VERSION "HNNBNNNYNNNNNNNNNNNNNNNNNNNNNNNNNNNNNNNNNN/4/%%%/4/'%**4NNN///"

NS_ :

BS_ :

BU_:  Airbag BAP_Tester ICAS1_Gateway ICAS1_KommunikationsServer LE1 LE2 Motor_BEV Schaltbetaetigung

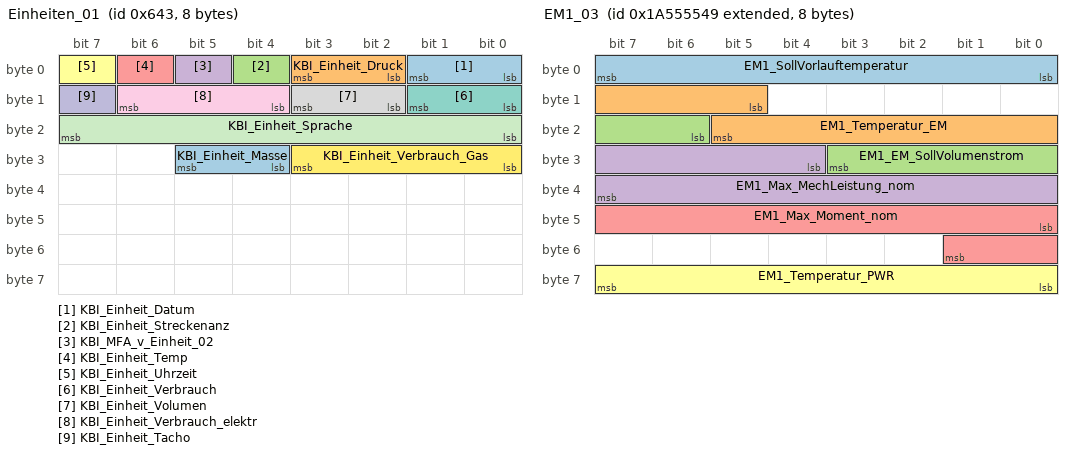
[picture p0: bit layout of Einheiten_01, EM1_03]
BO_ 1603 Einheiten_01: 8 ICAS1_KommunikationsServer
 SG_ KBI_Einheit_Datum  : 0|2@1+ (1.000000,0.000000) [0.000000|3.000000] "" Vector__XXX
 SG_ KBI_Einheit_Druck  : 2|2@1+ (1.000000,0.000000) [0.000000|3.000000] "" Vector__XXX
 SG_ KBI_Einheit_Streckenanz  : 4|1@1+ (1.000000,0.000000) [0.000000|1.000000] "" Vector__XXX
 SG_ KBI_MFA_v_Einheit_02  : 5|1@1+ (1.000000,0.000000) [0.000000|1.000000] "" Motor_BEV
 SG_ KBI_Einheit_Temp  : 6|1@1+ (1.000000,0.000000) [0.000000|1.000000] "" Vector__XXX
 SG_ KBI_Einheit_Uhrzeit  : 7|1@1+ (1.000000,0.000000) [0.000000|1.000000] "" Vector__XXX
 SG_ KBI_Einheit_Verbrauch  : 8|2@1+ (1.000000,0.000000) [0.000000|3.000000] "" Vector__XXX
 SG_ KBI_Einheit_Volumen  : 10|2@1+ (1.000000,0.000000) [0.000000|3.000000] "" Vector__XXX
 SG_ KBI_Einheit_Verbrauch_elektr  : 12|3@1+ (1.000000,0.000000) [0.000000|7.000000] "" Vector__XXX
 SG_ KBI_Einheit_Tacho  : 15|1@1+ (1.000000,0.000000) [0.000000|1.000000] "" Motor_BEV
 SG_ KBI_Einheit_Sprache  : 16|8@1+ (1.000000,0.000000) [0.000000|255.000000] "" Vector__XXX
 SG_ KBI_Einheit_Verbrauch_Gas  : 24|4@1+ (1.000000,0.000000) [0.000000|15.000000] "" Vector__XXX
 SG_ KBI_Einheit_Masse  : 28|2@1+ (1.000000,0.000000) [0.000000|3.000000] "" Vector__XXX

BO_ 192 EM1_01: 32 LE1
 SG_ EM1_01_CRC  : 0|8@1+ (1.000000,0.000000) [0.000000|255.000000] "" ICAS1_Gateway Motor_BEV
 SG_ EM1_01_BZ  : 8|4@1+ (1.000000,0.000000) [0.000000|15.000000] "" ICAS1_Gateway Motor_BEV
 SG_ EM1_Istmodus  : 12|4@1+ (1.000000,0.000000) [0.000000|15.000000] "" ICAS1_Gateway Motor_BEV
 SG_ EM1_IstMoment  : 16|12@1+ (0.500000,-1023.000000) [-1023.000000|1023.500000] "Unit_NewtoMeter" ICAS1_Gateway Motor_BEV
 SG_ EM1_Moment_AR_Eingriff  : 28|12@1+ (0.500000,-1023.000000) [-1023.000000|1023.500000] "Unit_NewtoMeter" ICAS1_Gateway Motor_BEV
 SG_ EM1_IstDrehzahl  : 40|15@1+ (1.000000,-10000.000000) [-10000.000000|22765.000000] "Unit_MinutInver" ICAS1_Gateway Motor_BEV
 SG_ EM1_AR_aktiv  : 55|1@1+ (1.000000,0.000000) [0.000000|1.000000] "" ICAS1_Gateway Motor_BEV
 SG_ EM1_IstSpannung  : 56|12@1+ (0.250000,0.000000) [0.000000|1023.250000] "Unit_Volt" ICAS1_Gateway Motor_BEV
 SG_ EM1_Strom_HV  : 68|12@1+ (0.500000,-1023.000000) [-1023.000000|1023.500000] "Unit_Amper" ICAS1_Gateway Motor_BEV
 SG_ EM1_Max_Moment  : 80|11@1+ (1.000000,-1023.000000) [-1023.000000|1022.000000] "Unit_NewtoMeter" ICAS1_Gateway Motor_BEV
 SG_ EM1_ErwGrenzen_aktiv  : 91|1@1+ (1.000000,0.000000) [0.000000|1.000000] "" ICAS1_Gateway Motor_BEV
 SG_ EM1_Min_Moment  : 92|11@1+ (1.000000,-1023.000000) [-1023.000000|1022.000000] "Unit_NewtoMeter" ICAS1_Gateway Motor_BEV
 SG_ EM1_Fehler_ElAntriebAbschaltung  : 103|1@1+ (1.000000,0.000000) [0.000000|1.000000] "" ICAS1_Gateway Motor_BEV
 SG_ EM1_Max_Moment_Lim  : 104|11@1+ (1.000000,-1023.000000) [-1023.000000|1022.000000] "Unit_NewtoMeter" ICAS1_Gateway Motor_BEV
 SG_ EM1_Fehler_Notabschaltung  : 115|1@1+ (1.000000,0.000000) [0.000000|1.000000] "" ICAS1_Gateway Motor_BEV
 SG_ EM1_Min_Moment_Lim  : 116|11@1+ (1.000000,-1023.000000) [-1023.000000|1022.000000] "Unit_NewtoMeter" ICAS1_Gateway Motor_BEV
 SG_ EM1_Status_DrzEingriff  : 127|2@1+ (1.000000,0.000000) [0.000000|3.000000] "" ICAS1_Gateway Motor_BEV
 SG_ EM1_Mom_DrzEingriff  : 129|11@1+ (1.000000,-1023.000000) [-1023.000000|1022.000000] "Unit_NewtoMeter" ICAS1_Gateway Motor_BEV

BO_ 2463978673 EM1_02: 32 LE1
 SG_ EM1_Status_Spgfreiheit  : 12|2@1+ (1.000000,0.000000) [0.000000|3.000000] "" Motor_BEV
 SG_ EM1_Status_EoHVL  : 14|2@1+ (1.000000,0.000000) [0.000000|3.000000] "" Motor_BEV
 SG_ EM1_Max_LeistungMech_Sockel  : 16|13@1+ (200.000000,-819000.000000) [-819000.000000|818800.000000] "Unit_Watt" Vector__XXX
 SG_ EM1_Max_Moment_Sockel  : 29|11@1+ (1.000000,-1023.000000) [-1023.000000|1022.000000] "Unit_NewtoMeter" Vector__XXX
 SG_ EM1_Min_LeistungMech_Sockel  : 40|13@1+ (200.000000,-819000.000000) [-819000.000000|818800.000000] "Unit_Watt" Vector__XXX
 SG_ EM1_Min_Moment_Sockel  : 53|11@1+ (1.000000,-1023.000000) [-1023.000000|1022.000000] "Unit_NewtoMeter" Vector__XXX
 SG_ EM1_PerfInd_MaxLeistung  : 64|10@1+ (0.200000,0.000000) [0.000000|200.000000] "Unit_PerCent" Motor_BEV
 SG_ EM1_PerfInd_MaxMoment  : 74|10@1+ (0.200000,0.000000) [0.000000|200.000000] "Unit_PerCent" Motor_BEV
 SG_ EM1_AnlernenElMotor_Anf  : 84|1@1+ (1.000000,0.000000) [0.000000|1.000000] "" Motor_BEV
 SG_ EM1_OBD_Lampe_Anf  : 85|1@1+ (1.000000,0.000000) [0.000000|1.000000] "" Motor_BEV
 SG_ EM1_Generator_Moment  : 86|10@1+ (1.000000,0.000000) [0.000000|1021.000000] "Unit_NewtoMeter" Motor_BEV
 SG_ EM1_PerfInd_Temperatur  : 96|8@1+ (0.800000,0.000000) [0.000000|200.000000] "Unit_PerCent" Motor_BEV
 SG_ EM1_MaxZul_Drehzahl  : 104|8@1+ (80.000000,0.000000) [0.000000|20240.000000] "Unit_RevPerMinute" Motor_BEV
 SG_ EM1_Min_Moment_Gesamt  : 112|11@1+ (1.000000,-1023.000000) [-1023.000000|1022.000000] "Unit_NewtoMeter" Motor_BEV
 SG_ EM1_Fehlerlampe_Anf  : 123|1@1+ (1.000000,0.000000) [0.000000|1.000000] "" Motor_BEV
 SG_ EM1_Max_Moment_Gesamt  : 124|11@1+ (1.000000,-1023.000000) [-1023.000000|1022.000000] "Unit_NewtoMeter" Motor_BEV
 SG_ EM1_Warnlampe_Anf  : 135|1@1+ (1.000000,0.000000) [0.000000|1.000000] "" Motor_BEV
 SG_ EM1_Rekuperation  : 136|15@1+ (10.000000,0.000000) [0.000000|327670.000000] "Unit_WattSecond" Motor_BEV
 SG_ EM1_Rekuperation_Ueberlauf  : 151|1@1+ (1.000000,0.000000) [0.000000|1.000000] "" Motor_BEV
 SG_ EM1_Verbrauch  : 152|15@1+ (10.000000,0.000000) [0.000000|327670.000000] "Unit_WattSecond" Motor_BEV
 SG_ EM1_Verbrauch_Ueberlauf  : 167|1@1+ (1.000000,0.000000) [0.000000|1.000000] "" Motor_BEV
 SG_ EM1_Fehler_AE  : 168|1@1+ (1.000000,0.000000) [0.000000|1.000000] "" Motor_BEV
 SG_ EM1_Fehler_Leistungsred  : 169|1@1+ (1.000000,0.000000) [0.000000|1.000000] "" Motor_BEV
 SG_ EM1_Fehler_ElAntriebFreilauf  : 170|1@1+ (1.000000,0.000000) [0.000000|1.000000] "" Motor_BEV
 SG_ EM1_PWR_SollVolumenstrom  : 171|6@1+ (0.500000,0.000000) [0.000000|30.500000] "Unit_LiterPerMinut" Motor_BEV

BO_ 2589283657 EM1_03: 8 LE1
 SG_ EM1_SollVorlauftemperatur  : 0|8@1+ (0.500000,-40.000000) [-40.000000|86.500000] "Unit_DegreCelsi" Motor_BEV
 SG_ EM1_Temperatur_EM  : 13|9@1+ (1.000000,-40.000000) [-40.000000|469.000000] "Unit_DegreCelsi" ICAS1_Gateway Motor_BEV
 SG_ EM1_EM_SollVolumenstrom  : 22|6@1+ (0.500000,0.000000) [0.000000|30.500000] "Unit_LiterPerMinut" Motor_BEV
 SG_ EM1_Max_MechLeistung_nom  : 28|12@1+ (200.000000,0.000000) [0.000000|818600.000000] "Unit_Watt" Motor_BEV
 SG_ EM1_Max_Moment_nom  : 40|10@1+ (1.000000,0.000000) [0.000000|1021.000000] "Unit_NewtoMeter" Motor_BEV
 SG_ EM1_Temperatur_PWR  : 56|8@1+ (1.000000,-40.000000) [-40.000000|213.000000] "Unit_DegreCelsi" ICAS1_Gateway Motor_BEV

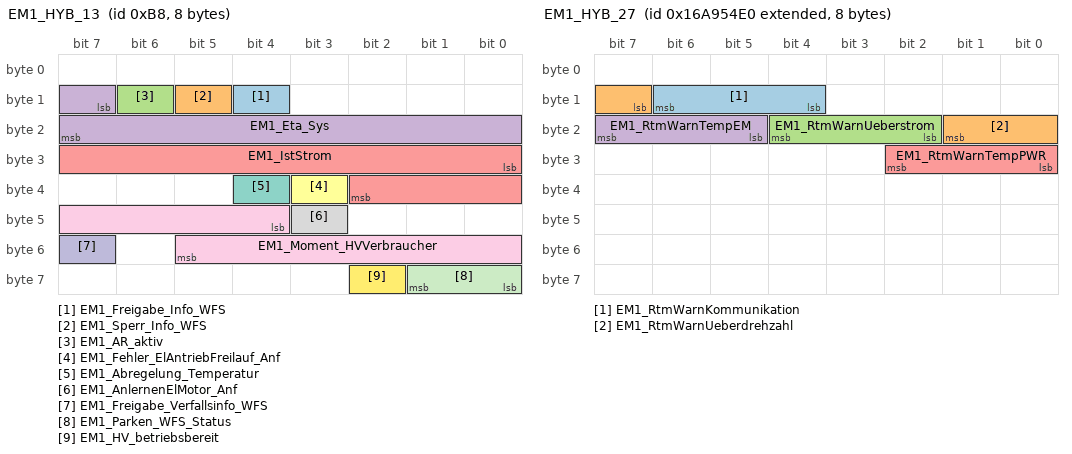
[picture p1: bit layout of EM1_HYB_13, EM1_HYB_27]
BO_ 184 EM1_HYB_13: 8 LE1
 SG_ EM1_Freigabe_Info_WFS  : 12|1@1+ (1.000000,0.000000) [0.000000|1.000000] "" ICAS1_Gateway Motor_BEV
 SG_ EM1_Sperr_Info_WFS  : 13|1@1+ (1.000000,0.000000) [0.000000|1.000000] "" ICAS1_Gateway Motor_BEV
 SG_ EM1_AR_aktiv  : 14|1@1+ (1.000000,0.000000) [0.000000|1.000000] "" ICAS1_Gateway
 SG_ EM1_Eta_Sys  : 15|9@1+ (0.200000,0.000000) [0.000000|101.800000] "Unit_PerCent" ICAS1_Gateway
 SG_ EM1_IstStrom  : 24|11@1+ (1.000000,-1023.000000) [-1023.000000|1022.000000] "Unit_Amper" ICAS1_Gateway
 SG_ EM1_Fehler_ElAntriebFreilauf_Anf  : 35|1@1+ (1.000000,0.000000) [0.000000|1.000000] "" ICAS1_Gateway
 SG_ EM1_Abregelung_Temperatur  : 36|1@1+ (1.000000,0.000000) [0.000000|1.000000] "" ICAS1_Gateway
 SG_ EM1_AnlernenElMotor_Anf  : 43|1@1+ (1.000000,0.000000) [0.000000|1.000000] "" ICAS1_Gateway
 SG_ EM1_Moment_HVVerbraucher  : 44|10@1+ (1.000000,-511.000000) [-511.000000|511.000000] "Unit_NewtoMeter" ICAS1_Gateway
 SG_ EM1_Freigabe_Verfallsinfo_WFS  : 55|1@1+ (1.000000,0.000000) [0.000000|1.000000] "" ICAS1_Gateway Motor_BEV
 SG_ EM1_Parken_WFS_Status  : 56|2@1+ (1.000000,0.000000) [0.000000|3.000000] "" ICAS1_Gateway
 SG_ EM1_HV_betriebsbereit  : 58|1@1+ (1.000000,0.000000) [0.000000|1.000000] "" ICAS1_Gateway

BO_ 2527679712 EM1_HYB_27: 8 LE1
 SG_ EM1_RtmWarnKommunikation  : 12|3@1+ (1.000000,0.000000) [0.000000|7.000000] "" Vector__XXX
 SG_ EM1_RtmWarnUeberdrehzahl  : 15|3@1+ (1.000000,0.000000) [0.000000|7.000000] "" ICAS1_Gateway
 SG_ EM1_RtmWarnUeberstrom  : 18|3@1+ (1.000000,0.000000) [0.000000|7.000000] "" ICAS1_Gateway
 SG_ EM1_RtmWarnTempEM  : 21|3@1+ (1.000000,0.000000) [0.000000|7.000000] "" ICAS1_Gateway
 SG_ EM1_RtmWarnTempPWR  : 24|3@1+ (1.000000,0.000000) [0.000000|7.000000] "" ICAS1_Gateway

BO_ 193 EM2_01: 32 LE2
 SG_ EM2_01_CRC  : 0|8@1+ (1.000000,0.000000) [0.000000|255.000000] "" Motor_BEV
 SG_ EM2_01_BZ  : 8|4@1+ (1.000000,0.000000) [0.000000|15.000000] "" Motor_BEV
 SG_ EM2_Istmodus  : 12|4@1+ (1.000000,0.000000) [0.000000|15.000000] "" ICAS1_Gateway Motor_BEV
 SG_ EM2_IstMoment  : 16|12@1+ (0.500000,-1023.000000) [-1023.000000|1023.500000] "Unit_NewtoMeter" ICAS1_Gateway Motor_BEV
 SG_ EM2_Moment_AR_Eingriff  : 28|12@1+ (0.500000,-1023.000000) [-1023.000000|1023.500000] "Unit_NewtoMeter" Motor_BEV
 SG_ EM2_IstDrehzahl  : 40|15@1+ (1.000000,-10000.000000) [-10000.000000|22765.000000] "Unit_MinutInver" ICAS1_Gateway Motor_BEV
 SG_ EM2_AR_aktiv  : 55|1@1+ (1.000000,0.000000) [0.000000|1.000000] "" Motor_BEV
 SG_ EM2_IstSpannung  : 56|12@1+ (0.250000,0.000000) [0.000000|1023.250000] "Unit_Volt" ICAS1_Gateway Motor_BEV
 SG_ EM2_Strom_HV  : 68|12@1+ (0.500000,-1023.000000) [-1023.000000|1023.500000] "Unit_Amper" ICAS1_Gateway Motor_BEV
 SG_ EM2_Max_Moment  : 80|11@1+ (1.000000,-1023.000000) [-1023.000000|1022.000000] "Unit_NewtoMeter" Motor_BEV
 SG_ EM2_ErwGrenzen_aktiv  : 91|1@1+ (1.000000,0.000000) [0.000000|1.000000] "" Motor_BEV
 SG_ EM2_Min_Moment  : 92|11@1+ (1.000000,-1023.000000) [-1023.000000|1022.000000] "Unit_NewtoMeter" Motor_BEV
 SG_ EM2_Fehler_ElAntriebAbschaltung  : 103|1@1+ (1.000000,0.000000) [0.000000|1.000000] "" Motor_BEV
 SG_ EM2_Max_Moment_Lim  : 104|11@1+ (1.000000,-1023.000000) [-1023.000000|1022.000000] "Unit_NewtoMeter" Motor_BEV
 SG_ EM2_Fehler_Notabschaltung  : 115|1@1+ (1.000000,0.000000) [0.000000|1.000000] "" ICAS1_Gateway Motor_BEV
 SG_ EM2_Min_Moment_Lim  : 116|11@1+ (1.000000,-1023.000000) [-1023.000000|1022.000000] "Unit_NewtoMeter" Motor_BEV
 SG_ EM2_Status_DrzEingriff  : 127|2@1+ (1.000000,0.000000) [0.000000|3.000000] "" ICAS1_Gateway Motor_BEV
 SG_ EM2_Mom_DrzEingriff  : 129|11@1+ (1.000000,-1023.000000) [-1023.000000|1022.000000] "Unit_NewtoMeter" Motor_BEV

BO_ 2463978674 EM2_02: 32 LE2
 SG_ EM2_Status_Spgfreiheit  : 12|2@1+ (1.000000,0.000000) [0.000000|3.000000] "" Motor_BEV
 SG_ EM2_Status_EoHVL  : 14|2@1+ (1.000000,0.000000) [0.000000|3.000000] "" Motor_BEV
 SG_ EM2_Max_LeistungMech_Sockel  : 16|13@1+ (200.000000,-819000.000000) [-819000.000000|818800.000000] "Unit_Watt" Vector__XXX
 SG_ EM2_Max_Moment_Sockel  : 29|11@1+ (1.000000,-1023.000000) [-1023.000000|1022.000000] "Unit_NewtoMeter" Vector__XXX
 SG_ EM2_Min_LeistungMech_Sockel  : 40|13@1+ (200.000000,-819000.000000) [-819000.000000|818800.000000] "Unit_Watt" Vector__XXX
 SG_ EM2_Min_Moment_Sockel  : 53|11@1+ (1.000000,-1023.000000) [-1023.000000|1022.000000] "Unit_NewtoMeter" Vector__XXX
 SG_ EM2_PerfInd_MaxLeistung  : 64|10@1+ (0.200000,0.000000) [0.000000|200.000000] "Unit_PerCent" Motor_BEV
 SG_ EM2_PerfInd_MaxMoment  : 74|10@1+ (0.200000,0.000000) [0.000000|200.000000] "Unit_PerCent" Motor_BEV
 SG_ EM2_AnlernenElMotor_Anf  : 84|1@1+ (1.000000,0.000000) [0.000000|1.000000] "" Motor_BEV
 SG_ EM2_OBD_Lampe_Anf  : 85|1@1+ (1.000000,0.000000) [0.000000|1.000000] "" Motor_BEV
 SG_ EM2_Generator_Moment  : 86|10@1+ (1.000000,0.000000) [0.000000|1021.000000] "Unit_NewtoMeter" Motor_BEV
 SG_ EM2_PerfInd_Temperatur  : 96|8@1+ (0.800000,0.000000) [0.000000|200.000000] "Unit_PerCent" Motor_BEV
 SG_ EM2_MaxZul_Drehzahl  : 104|8@1+ (80.000000,0.000000) [0.000000|20240.000000] "Unit_RevPerMinute" Motor_BEV
 SG_ EM2_Min_Moment_Gesamt  : 112|11@1+ (1.000000,-1023.000000) [-1023.000000|1022.000000] "Unit_NewtoMeter" Motor_BEV
 SG_ EM2_Fehlerlampe_Anf  : 123|1@1+ (1.000000,0.000000) [0.000000|1.000000] "" Motor_BEV
 SG_ EM2_Max_Moment_Gesamt  : 124|11@1+ (1.000000,-1023.000000) [-1023.000000|1022.000000] "Unit_NewtoMeter" Motor_BEV
 SG_ EM2_Warnlampe_Anf  : 135|1@1+ (1.000000,0.000000) [0.000000|1.000000] "" Motor_BEV
 SG_ EM2_Rekuperation  : 136|15@1+ (10.000000,0.000000) [0.000000|327670.000000] "Unit_WattSecond" Motor_BEV
 SG_ EM2_Rekuperation_Ueberlauf  : 151|1@1+ (1.000000,0.000000) [0.000000|1.000000] "" Motor_BEV
 SG_ EM2_Verbrauch  : 152|15@1+ (10.000000,0.000000) [0.000000|327670.000000] "Unit_WattSecond" Motor_BEV
 SG_ EM2_Verbrauch_Ueberlauf  : 167|1@1+ (1.000000,0.000000) [0.000000|1.000000] "" Motor_BEV
 SG_ EM2_Fehler_AE  : 168|1@1+ (1.000000,0.000000) [0.000000|1.000000] "" Motor_BEV
 SG_ EM2_Fehler_Leistungsred  : 169|1@1+ (1.000000,0.000000) [0.000000|1.000000] "" Motor_BEV
 SG_ EM2_Fehler_ElAntriebFreilauf  : 170|1@1+ (1.000000,0.000000) [0.000000|1.000000] "" Motor_BEV
 SG_ EM2_PWR_SollVolumenstrom  : 171|6@1+ (0.500000,0.000000) [0.000000|30.500000] "Unit_LiterPerMinut" Motor_BEV

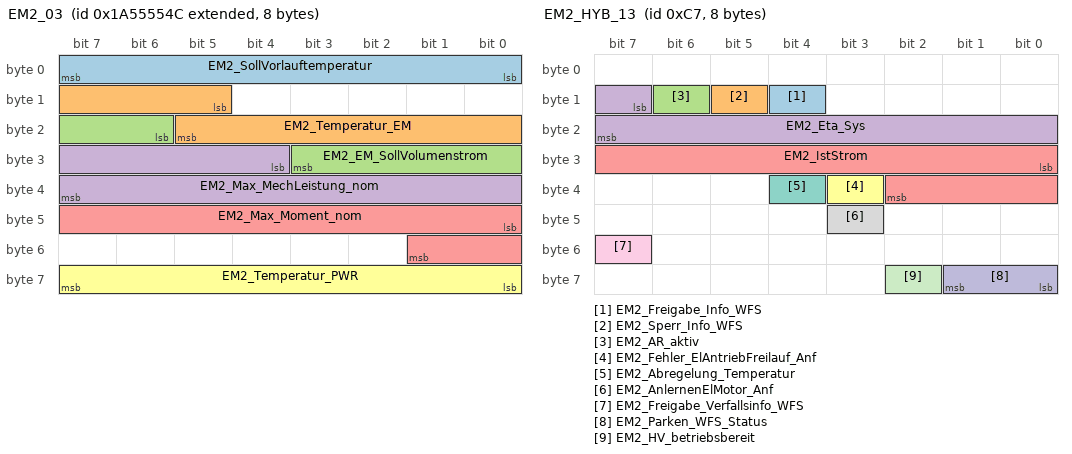
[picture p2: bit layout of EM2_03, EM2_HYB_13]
BO_ 2589283660 EM2_03: 8 LE2
 SG_ EM2_SollVorlauftemperatur  : 0|8@1+ (0.500000,-40.000000) [-40.000000|86.500000] "Unit_DegreCelsi" Motor_BEV
 SG_ EM2_Temperatur_EM  : 13|9@1+ (1.000000,-40.000000) [-40.000000|469.000000] "Unit_DegreCelsi" ICAS1_Gateway Motor_BEV
 SG_ EM2_EM_SollVolumenstrom  : 22|6@1+ (0.500000,0.000000) [0.000000|30.500000] "Unit_LiterPerMinut" Motor_BEV
 SG_ EM2_Max_MechLeistung_nom  : 28|12@1+ (200.000000,0.000000) [0.000000|818600.000000] "Unit_Watt" Motor_BEV
 SG_ EM2_Max_Moment_nom  : 40|10@1+ (1.000000,0.000000) [0.000000|1021.000000] "Unit_NewtoMeter" Motor_BEV
 SG_ EM2_Temperatur_PWR  : 56|8@1+ (1.000000,-40.000000) [-40.000000|213.000000] "Unit_DegreCelsi" ICAS1_Gateway Motor_BEV

BO_ 199 EM2_HYB_13: 8 LE2
 SG_ EM2_Freigabe_Info_WFS  : 12|1@1+ (1.000000,0.000000) [0.000000|1.000000] "" ICAS1_Gateway Motor_BEV
 SG_ EM2_Sperr_Info_WFS  : 13|1@1+ (1.000000,0.000000) [0.000000|1.000000] "" ICAS1_Gateway Motor_BEV
 SG_ EM2_AR_aktiv  : 14|1@1+ (1.000000,0.000000) [0.000000|1.000000] "" ICAS1_Gateway
 SG_ EM2_Eta_Sys  : 15|9@1+ (0.200000,0.000000) [0.000000|101.800000] "Unit_PerCent" ICAS1_Gateway
 SG_ EM2_IstStrom  : 24|11@1+ (1.000000,-1023.000000) [-1023.000000|1022.000000] "Unit_Amper" ICAS1_Gateway
 SG_ EM2_Fehler_ElAntriebFreilauf_Anf  : 35|1@1+ (1.000000,0.000000) [0.000000|1.000000] "" ICAS1_Gateway
 SG_ EM2_Abregelung_Temperatur  : 36|1@1+ (1.000000,0.000000) [0.000000|1.000000] "" ICAS1_Gateway
 SG_ EM2_AnlernenElMotor_Anf  : 43|1@1+ (1.000000,0.000000) [0.000000|1.000000] "" ICAS1_Gateway
 SG_ EM2_Freigabe_Verfallsinfo_WFS  : 55|1@1+ (1.000000,0.000000) [0.000000|1.000000] "" ICAS1_Gateway Motor_BEV
 SG_ EM2_Parken_WFS_Status  : 56|2@1+ (1.000000,0.000000) [0.000000|3.000000] "" ICAS1_Gateway
 SG_ EM2_HV_betriebsbereit  : 58|1@1+ (1.000000,0.000000) [0.000000|1.000000] "" ICAS1_Gateway

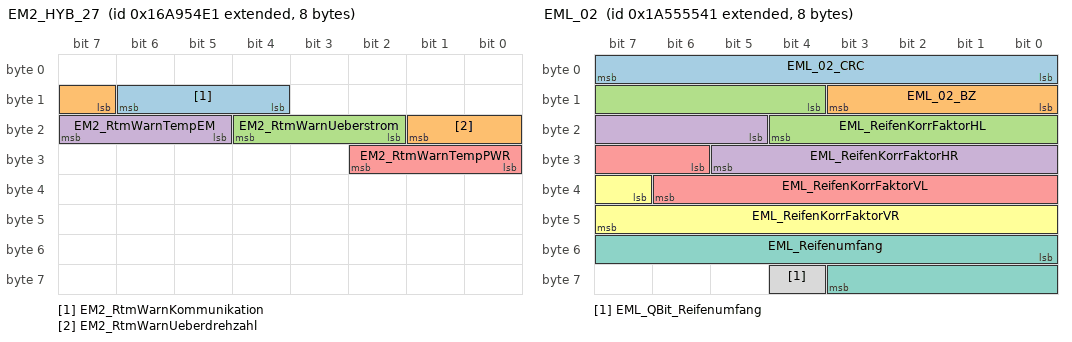
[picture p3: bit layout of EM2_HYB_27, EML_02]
BO_ 2527679713 EM2_HYB_27: 8 LE2
 SG_ EM2_RtmWarnKommunikation  : 12|3@1+ (1.000000,0.000000) [0.000000|7.000000] "" Vector__XXX
 SG_ EM2_RtmWarnUeberdrehzahl  : 15|3@1+ (1.000000,0.000000) [0.000000|7.000000] "" ICAS1_Gateway
 SG_ EM2_RtmWarnUeberstrom  : 18|3@1+ (1.000000,0.000000) [0.000000|7.000000] "" ICAS1_Gateway
 SG_ EM2_RtmWarnTempEM  : 21|3@1+ (1.000000,0.000000) [0.000000|7.000000] "" ICAS1_Gateway
 SG_ EM2_RtmWarnTempPWR  : 24|3@1+ (1.000000,0.000000) [0.000000|7.000000] "" ICAS1_Gateway

BO_ 2589283649 EML_02: 8 ICAS1_Gateway
 SG_ EML_02_CRC  : 0|8@1+ (1.000000,0.000000) [0.000000|255.000000] "" Vector__XXX
 SG_ EML_02_BZ  : 8|4@1+ (1.000000,0.000000) [0.000000|15.000000] "" Vector__XXX
 SG_ EML_ReifenKorrFaktorHL  : 12|9@1+ (0.000488,0.850000) [0.850000|1.098535] "" Vector__XXX
 SG_ EML_ReifenKorrFaktorHR  : 21|9@1+ (0.000488,0.850000) [0.850000|1.098535] "" Vector__XXX
 SG_ EML_ReifenKorrFaktorVL  : 30|9@1+ (0.000488,0.850000) [0.850000|1.098535] "" Vector__XXX
 SG_ EML_ReifenKorrFaktorVR  : 39|9@1+ (0.000488,0.850000) [0.850000|1.098535] "" Vector__XXX
 SG_ EML_Reifenumfang  : 48|12@1+ (1.000000,0.000000) [0.000000|4095.000000] "Unit_MilliMeter" Motor_BEV
 SG_ EML_QBit_Reifenumfang  : 60|1@1+ (1.000000,0.000000) [0.000000|1.000000] "" Motor_BEV

BO_ 608 EML_07: 8 ICAS1_Gateway
 SG_ EML_AnzeigeGeschw  : 54|10@1+ (0.320000,0.000000) [0.000000|325.120000] "Unit_KiloMeterPerHour" Motor_BEV

BO_ 2589283751 Entfernungen_01: 8 ICAS1_KommunikationsServer
 SG_ KBI_Kilometerstand_HiRes_meter  : 32|32@1+ (1.000000,0.000000) [0.000000|4294967295.000000] "Unit_Meter" Motor_BEV

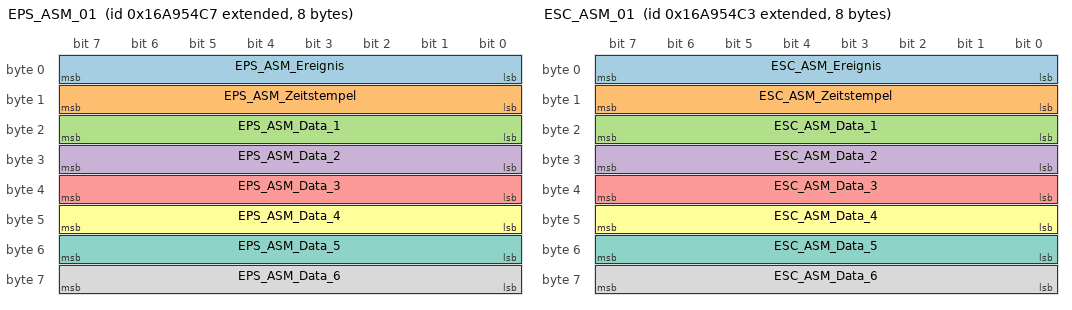
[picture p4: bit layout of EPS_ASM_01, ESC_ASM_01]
BO_ 2527679687 EPS_ASM_01: 8 ICAS1_Gateway
 SG_ EPS_ASM_Ereignis  : 0|8@1+ (1.000000,0.000000) [1.000000|254.000000] "Unit_None" Airbag
 SG_ EPS_ASM_Zeitstempel  : 8|8@1+ (0.080000,0.000000) [0.000000|20.320000] "Unit_None" Airbag
 SG_ EPS_ASM_Data_1  : 16|8@1+ (1.000000,0.000000) [0.000000|255.000000] "Unit_None" Airbag
 SG_ EPS_ASM_Data_2  : 24|8@1+ (1.000000,0.000000) [0.000000|255.000000] "Unit_None" Airbag
 SG_ EPS_ASM_Data_3  : 32|8@1+ (1.000000,0.000000) [0.000000|255.000000] "Unit_None" Airbag
 SG_ EPS_ASM_Data_4  : 40|8@1+ (1.000000,0.000000) [0.000000|255.000000] "Unit_None" Airbag
 SG_ EPS_ASM_Data_5  : 48|8@1+ (1.000000,0.000000) [0.000000|255.000000] "Unit_None" Airbag
 SG_ EPS_ASM_Data_6  : 56|8@1+ (1.000000,0.000000) [0.000000|255.000000] "Unit_None" Airbag

BO_ 258 ESC_50: 48 ICAS1_Gateway
 SG_ ESC_50_CRC  : 0|8@1+ (1.000000,0.000000) [0.000000|255.000000] "" Motor_BEV
 SG_ ESC_50_BZ  : 8|4@1+ (1.000000,0.000000) [0.000000|15.000000] "" Motor_BEV
 SG_ ESP_QBit_Gierrate  : 12|1@1+ (1.000000,0.000000) [0.000000|1.000000] "" Motor_BEV
 SG_ ESP_QBit_Laengsbeschl  : 13|1@1+ (1.000000,0.000000) [0.000000|1.000000] "" Motor_BEV
 SG_ ESP_QBit_Querb  : 14|1@1+ (1.000000,0.000000) [0.000000|1.000000] "" Motor_BEV
 SG_ ESP_Querbeschleunigung  : 16|8@1+ (0.010000,-1.270000) [-1.270000|1.270000] "Unit_ForceOfGravi" Airbag Motor_BEV
 SG_ ESP_Laengsbeschl  : 24|10@1+ (0.031250,-16.000000) [-16.000000|15.906250] "Unit_MeterPerSeconSquar" Airbag Motor_BEV
 SG_ ESC_Motorstartverzoegerung  : 34|1@1+ (1.000000,0.000000) [0.000000|1.000000] "" Vector__XXX
 SG_ ESC_SeitenwindAssistent_Eingriff  : 35|1@1+ (1.000000,0.000000) [0.000000|1.000000] "" Vector__XXX
 SG_ ESP_Anschleppstart_Freigabe  : 36|2@1+ (1.000000,0.000000) [0.000000|3.000000] "" Vector__XXX
 SG_ ESC_Unterdruckmangel_erkannt  : 38|1@1+ (1.000000,0.000000) [0.000000|1.000000] "" Vector__XXX
 SG_ ESP_Gierrate  : 40|14@1+ (0.010000,0.000000) [0.000000|163.820000] "Unit_DegreOfArcPerSecon" Airbag Motor_BEV
 SG_ ESP_VZ_Gierrate  : 54|1@1+ (1.000000,0.000000) [0.000000|1.000000] "" Airbag Motor_BEV
 SG_ ESP_Notbremsanzeige  : 55|1@1+ (1.000000,0.000000) [0.000000|1.000000] "" Vector__XXX
 SG_ ESP_SpannungsAnf  : 56|1@1+ (1.000000,0.000000) [0.000000|1.000000] "" Vector__XXX
 SG_ ESP_PLA_Abbruch  : 57|3@1+ (1.000000,0.000000) [0.000000|7.000000] "" Vector__XXX
 SG_ ESP_Status_ESP_PLA  : 60|4@1+ (1.000000,0.000000) [0.000000|15.000000] "" Vector__XXX
 SG_ ESP_QBit_Bremsdruck  : 76|1@1+ (1.000000,0.000000) [0.000000|1.000000] "" Airbag Motor_BEV
 SG_ ESP_QBit_Fahrer_bremst  : 77|1@1+ (1.000000,0.000000) [0.000000|1.000000] "" Vector__XXX
 SG_ ESP_Schwelle_Unterdruck  : 78|2@1+ (1.000000,0.000000) [0.000000|3.000000] "" Vector__XXX
 SG_ ESP_Bremsdruck  : 80|10@1+ (0.300000,-30.000000) [-30.000000|276.600000] "Unit_Bar" Motor_BEV
 SG_ ESP_Fahrer_bremst  : 90|1@1+ (1.000000,0.000000) [0.000000|1.000000] "" Vector__XXX
 SG_ ESP_Verz_TSK_aktiv  : 91|1@1+ (1.000000,0.000000) [0.000000|1.000000] "" Vector__XXX
 SG_ ESP_Lenkeingriff_ADS  : 92|1@1+ (1.000000,0.000000) [0.000000|1.000000] "" Vector__XXX
 SG_ ESP_Konsistenz_TSK  : 93|1@1+ (1.000000,0.000000) [0.000000|1.000000] "" Vector__XXX
 SG_ ESP_Bremsruck_AWV2  : 94|1@1+ (1.000000,0.000000) [0.000000|1.000000] "" Vector__XXX
 SG_ ESP_Konsistenz_AWV2  : 95|1@1+ (1.000000,0.000000) [0.000000|1.000000] "" Vector__XXX
 SG_ ECD_Fehler  : 96|1@1+ (1.000000,0.000000) [0.000000|1.000000] "" Vector__XXX
 SG_ ECD_nicht_verfuegbar  : 97|1@1+ (1.000000,0.000000) [0.000000|1.000000] "" Vector__XXX
 SG_ ESP_Status_Bremsentemp  : 98|1@1+ (1.000000,0.000000) [0.000000|1.000000] "" Vector__XXX
 SG_ ESP_Autohold_Standby  : 99|1@1+ (1.000000,0.000000) [0.000000|1.000000] "" Vector__XXX
 SG_ ESP_HDC_Standby  : 100|1@1+ (1.000000,0.000000) [0.000000|1.000000] "" Vector__XXX
 SG_ ESP_HBA_aktiv  : 101|1@1+ (1.000000,0.000000) [0.000000|1.000000] "" Vector__XXX
 SG_ ESP_Prefill_ausgeloest  : 102|1@1+ (1.000000,0.000000) [0.000000|1.000000] "" Vector__XXX
 SG_ ESP_Rueckwaertsfahrt_erkannt  : 103|1@1+ (1.000000,0.000000) [0.000000|1.000000] "" Vector__XXX
 SG_ ESP_Status_Anfahrhilfe  : 104|1@1+ (1.000000,0.000000) [0.000000|1.000000] "" Vector__XXX
 SG_ ESP_HDC_aktiv  : 105|1@1+ (1.000000,0.000000) [0.000000|1.000000] "" Vector__XXX
 SG_ ESP_StartStopp_Info  : 106|2@1+ (1.000000,0.000000) [0.000000|3.000000] "" Vector__XXX
 SG_ ESP_Eingr_HL  : 108|1@1+ (1.000000,0.000000) [0.000000|1.000000] "" Vector__XXX
 SG_ ESP_Eingr_HR  : 109|1@1+ (1.000000,0.000000) [0.000000|1.000000] "" Vector__XXX
 SG_ ESP_Eingr_VL  : 110|1@1+ (1.000000,0.000000) [0.000000|1.000000] "" Vector__XXX
 SG_ ESP_Eingr_VR  : 111|1@1+ (1.000000,0.000000) [0.000000|1.000000] "" Vector__XXX
 SG_ ESP_BKV_Unterdruck  : 112|8@1+ (4.000000,0.000000) [4.000000|1012.000000] "Unit_MilliBar" Vector__XXX
 SG_ ESP_Autohold_aktiv  : 120|1@1+ (1.000000,0.000000) [0.000000|1.000000] "" Vector__XXX
 SG_ ESP_FStatus_Anfahrhilfe  : 121|1@1+ (1.000000,0.000000) [0.000000|1.000000] "" Vector__XXX
 SG_ ESP_Verz_EPB_aktiv  : 122|1@1+ (1.000000,0.000000) [0.000000|1.000000] "" Vector__XXX
 SG_ ECD_Bremslicht  : 123|1@1+ (1.000000,0.000000) [0.000000|1.000000] "" Motor_BEV
 SG_ ESP_Verzoeg_EPB_verf  : 124|1@1+ (1.000000,0.000000) [0.000000|1.000000] "" Vector__XXX
 SG_ ESP_Status_Bremsdruck  : 125|1@1+ (1.000000,0.000000) [0.000000|1.000000] "" Vector__XXX
 SG_ ESP_Anforderung_EPB  : 126|2@1+ (1.000000,0.000000) [0.000000|3.000000] "" Vector__XXX
 SG_ ESP_ANB_CM_Rueckk_Umsetz  : 140|1@1+ (1.000000,0.000000) [0.000000|1.000000] "" Vector__XXX
 SG_ ESP_Konsistenz_ACC_Botschaft  : 141|1@1+ (1.000000,0.000000) [0.000000|1.000000] "" Vector__XXX
 SG_ ESP_Stillstandsphase_erschoepft  : 142|1@1+ (1.000000,0.000000) [0.000000|1.000000] "" Vector__XXX
 SG_ ESP_ZT_Rueckk_Umsetz  : 143|1@1+ (1.000000,0.000000) [0.000000|1.000000] "" Vector__XXX
 SG_ ESP_Tuerkontakt_Fahrertuer  : 144|1@1+ (1.000000,0.000000) [0.000000|1.000000] "" Vector__XXX
 SG_ ESP_Abrutschen_Stillstand  : 146|1@1+ (1.000000,0.000000) [0.000000|1.000000] "" Vector__XXX
 SG_ ESP_Fahrer_tritt_ZBR_Schw  : 147|1@1+ (1.000000,0.000000) [0.000000|1.000000] "" Vector__XXX
 SG_ ESP_QBit_v_ref  : 169|1@1+ (1.000000,0.000000) [0.000000|1.000000] "" Vector__XXX
 SG_ ESP_v_ref_Fahrtrichtung  : 170|2@1+ (1.000000,0.000000) [0.000000|3.000000] "" Motor_BEV
 SG_ ESC_Bremsdruckgradient  : 172|8@1+ (10.000000,0.000000) [0.000000|2500.000000] "Unit_BarPerSecon" Vector__XXX
 SG_ ESP_v_ref  : 180|12@1+ (0.125000,0.000000) [0.000000|511.500000] "Unit_KiloMeterPerHour" Airbag Motor_BEV
 SG_ ESC_Hydr_Fkt_aktiv  : 223|2@1+ (1.000000,0.000000) [0.000000|3.000000] "" Vector__XXX
 SG_ ESC_QBit_Fahrerbremswunsch  : 225|1@1+ (1.000000,0.000000) [0.000000|1.000000] "" Motor_BEV
 SG_ ESC_Fahrerbremswunsch  : 226|10@1+ (0.300000,-30.000000) [-30.000000|276.600000] "Unit_Bar" Motor_BEV
 SG_ ESCGeneratorSollMoment  : 236|12@1+ (3.000000,-12279.000000) [-12279.000000|0.000000] "" Motor_BEV
 SG_ ESC_Raddruck_max  : 248|8@1+ (1.000000,0.000000) [0.000000|250.000000] "Unit_Bar" Vector__XXX
 SG_ EPB_QBit_Pedalweg_Kuppl  : 269|1@1+ (1.000000,0.000000) [0.000000|1.000000] "" Vector__XXX
 SG_ EPB_Freig_Verzoeg_Anf  : 271|1@1+ (1.000000,0.000000) [0.000000|1.000000] "" Vector__XXX
 SG_ EPB_Verzoeg_Anf  : 272|8@1+ (0.048000,-7.968000) [-7.968000|4.224000] "Unit_MeterPerSeconSquar" Vector__XXX
 SG_ EPB_Pedalweg_Kuppl  : 288|8@1+ (0.400000,0.000000) [8.000000|92.000000] "Unit_PerCent" Vector__XXX
 SG_ EPB_DAA_Randbed_erf  : 305|1@1+ (1.000000,0.000000) [0.000000|1.000000] "" Vector__XXX
 SG_ EPB_Fehlerstatus_02  : 306|2@1+ (1.000000,0.000000) [0.000000|3.000000] "" Vector__XXX
 SG_ EPB_Schalterposition  : 308|2@1+ (1.000000,0.000000) [0.000000|3.000000] "" Airbag
 SG_ EPB_QBit_Schalterpos  : 310|1@1+ (1.000000,0.000000) [0.000000|1.000000] "" Vector__XXX
 SG_ EPB_Spannkraft  : 312|5@1+ (1.000000,0.000000) [0.000000|29.000000] "Unit_KiloNewto" Vector__XXX
 SG_ EPB_Status_02  : 317|3@1+ (1.000000,0.000000) [0.000000|7.000000] "" Motor_BEV
 SG_ EPB_Status  : 320|2@1+ (1.000000,0.000000) [0.000000|3.000000] "" Vector__XXX
 SG_ ESP_Status_Bremsentemp_02  : 322|2@1+ (1.000000,0.000000) [0.000000|3.000000] "" Motor_BEV

BO_ 252 ESC_51: 48 ICAS1_Gateway
 SG_ ESC_51_CRC  : 0|8@1+ (1.000000,0.000000) [0.000000|255.000000] "" Motor_BEV
 SG_ ESC_51_BZ  : 8|4@1+ (1.000000,0.000000) [0.000000|15.000000] "" Motor_BEV
 SG_ ESC_aktBr_Modus  : 12|2@1+ (1.000000,0.000000) [0.000000|3.000000] "" Vector__XXX
 SG_ ESC_Blending_Solldruck  : 14|10@1+ (0.250000,0.000000) [0.000000|250.000000] "Unit_Bar" Vector__XXX
 SG_ ESC_aktBr_Volumenstrom  : 24|16@1+ (0.007812,-252.000000) [-252.000000|252.000000] "Unit_MilliLiterPerSec" Vector__XXX
 SG_ ESC_EBKV_Kraftblending_Modus  : 40|2@1+ (1.000000,0.000000) [0.000000|3.000000] "" Vector__XXX
 SG_ ESC_Bremsdruck_Modell  : 42|10@1+ (0.250000,0.000000) [0.000000|250.000000] "Unit_Bar" Motor_BEV
 SG_ ESC_Bremsdruck_02  : 52|10@1+ (0.300000,-30.000000) [-30.000000|276.600000] "Unit_Bar" Vector__XXX
 SG_ ESC_QBit_Bremsdruck_02  : 62|1@1+ (1.000000,0.000000) [0.000000|1.000000] "" Vector__XXX
 SG_ ESP_HL_Radgeschw_02  : 64|16@1+ (0.007500,0.000000) [0.000000|491.490000] "Unit_KiloMeterPerHour" Airbag LE1 LE2 Motor_BEV
 SG_ ESP_HR_Radgeschw_02  : 80|16@1+ (0.007500,0.000000) [0.000000|491.490000] "Unit_KiloMeterPerHour" Airbag LE1 LE2 Motor_BEV
 SG_ ESP_VL_Radgeschw_02  : 96|16@1+ (0.007500,0.000000) [0.000000|491.490000] "Unit_KiloMeterPerHour" Airbag LE1 LE2 Motor_BEV
 SG_ ESP_VR_Radgeschw_02  : 112|16@1+ (0.007500,0.000000) [0.000000|491.490000] "Unit_KiloMeterPerHour" Airbag LE1 LE2 Motor_BEV
 SG_ ESP_FZR_uebersteuern  : 128|8@1+ (0.004000,0.000000) [0.000000|1.000000] "" Vector__XXX
 SG_ ESP_FZR_untersteuern  : 136|8@1+ (0.004000,0.000000) [0.000000|1.000000] "" Vector__XXX
 SG_ ESC_Anf_Mindestreku  : 144|1@1+ (1.000000,0.000000) [0.000000|1.000000] "" Motor_BEV
 SG_ ESC_GMV_aktiv  : 145|3@1+ (1.000000,0.000000) [0.000000|7.000000] "" Vector__XXX
 SG_ ESC_GMV_nicht_verfuegbar  : 148|1@1+ (1.000000,0.000000) [0.000000|1.000000] "" Vector__XXX
 SG_ ESC_Status_vRef_Stuetzeingriff  : 149|1@1+ (1.000000,0.000000) [0.000000|1.000000] "" Motor_BEV
 SG_ FDR_Allradverteilung_aktiv  : 150|1@1+ (1.000000,0.000000) [0.000000|1.000000] "" Vector__XXX
 SG_ FDR_Anf_Allradbetrieb  : 151|1@1+ (1.000000,0.000000) [0.000000|1.000000] "" Vector__XXX
 SG_ ESP_HL_Bremsmoment  : 152|8@1+ (20.000000,0.000000) [0.000000|5060.000000] "Unit_NewtoMeter" Motor_BEV
 SG_ ESP_HR_Bremsmoment  : 160|8@1+ (20.000000,0.000000) [0.000000|5060.000000] "Unit_NewtoMeter" Motor_BEV
 SG_ ESP_VR_Bremsmoment  : 168|8@1+ (40.000000,0.000000) [0.000000|10120.000000] "Unit_NewtoMeter" Motor_BEV
 SG_ ESP_VL_Bremsmoment  : 176|8@1+ (40.000000,0.000000) [0.000000|10120.000000] "Unit_NewtoMeter" Motor_BEV
 SG_ ESP_FDR_uebersteuern  : 184|8@1+ (0.004000,0.000000) [0.000000|1.000000] "" Motor_BEV
 SG_ ESP_FDR_untersteuern  : 192|8@1+ (0.004000,0.000000) [0.000000|1.000000] "" Motor_BEV
 SG_ TSMomBegrenzung  : 268|12@1+ (3.000000,-12279.000000) [-12279.000000|0.000000] "" Motor_BEV
 SG_ ESC_Allrad_Anteil_max_sek  : 280|9@1+ (0.200000,0.000000) [0.000000|100.000000] "Unit_PerCent" Motor_BEV
 SG_ ESC_Allrad_Anteil_min_sek  : 289|9@1+ (0.200000,0.000000) [0.000000|100.000000] "Unit_PerCent" Motor_BEV
 SG_ ESC_Status_Eingriff  : 298|2@1+ (1.000000,0.000000) [0.000000|3.000000] "" Motor_BEV
 SG_ ESC_Status_Eingriff_sek  : 300|2@1+ (1.000000,0.000000) [0.000000|3.000000] "" Motor_BEV
 SG_ ESC_MomRad_Eingriff  : 302|13@1+ (3.000000,-12279.000000) [-12279.000000|12279.000000] "Unit_None" Motor_BEV
 SG_ ESC_MomRad_Eingriff_sek  : 315|13@1+ (3.000000,-12279.000000) [-12279.000000|12279.000000] "Unit_None" Motor_BEV
 SG_ ESC_Achsdrehzahl_Max  : 328|14@1+ (0.400000,-800.000000) [-800.000000|5752.400000] "Unit_MinutInver" Motor_BEV
 SG_ ESC_Achsdrehzahl_Min  : 342|14@1+ (0.400000,-800.000000) [-800.000000|5752.400000] "Unit_MinutInver" Motor_BEV
 SG_ ESC_Achsdrehzahl_Max_sek  : 356|14@1+ (0.400000,-800.000000) [-800.000000|5752.400000] "Unit_MinutInver" Motor_BEV
 SG_ ESC_Achsdrehzahl_Min_sek  : 370|14@1+ (0.400000,-800.000000) [-800.000000|5752.400000] "Unit_MinutInver" Motor_BEV

BO_ 2463978647 ESC_52: 16 ICAS1_Gateway
 SG_ ESP_ACC_LDE  : 12|1@1+ (1.000000,0.000000) [0.000000|1.000000] "" Vector__XXX
 SG_ ESP_Allrad_Antrieb  : 13|1@1+ (1.000000,0.000000) [0.000000|1.000000] "" Vector__XXX
 SG_ ESP_Codierung_ADS  : 14|2@1+ (1.000000,0.000000) [0.000000|3.000000] "" Vector__XXX
 SG_ ESP_RTA_HL  : 16|8@1+ (0.048828,-6.201170) [-6.201170|6.152346] "Unit_PerCent" Motor_BEV
 SG_ ESP_RTA_HR  : 24|8@1+ (0.048828,-6.201170) [-6.201170|6.152346] "Unit_PerCent" Motor_BEV
 SG_ ESP_RTA_VR  : 32|8@1+ (0.048828,-6.201170) [-6.201170|6.152346] "Unit_PerCent" Motor_BEV
 SG_ OBD_Fehler_Radsensor_HL  : 40|4@1+ (1.000000,0.000000) [0.000000|15.000000] "" Motor_BEV
 SG_ OBD_Fehler_Radsensor_HR  : 44|4@1+ (1.000000,0.000000) [0.000000|15.000000] "" Motor_BEV
 SG_ OBD_Fehler_Radsensor_VL  : 48|4@1+ (1.000000,0.000000) [0.000000|15.000000] "" Motor_BEV
 SG_ OBD_Fehler_Radsensor_VR  : 52|4@1+ (1.000000,0.000000) [0.000000|15.000000] "" Motor_BEV
 SG_ ESP_Qualifizierung_Antriebsart  : 56|1@1+ (1.000000,0.000000) [0.000000|1.000000] "" Vector__XXX
 SG_ ESP_Offroad_Modus  : 57|1@1+ (1.000000,0.000000) [0.000000|1.000000] "" Vector__XXX
 SG_ ESP_MKB_ausloesbar  : 58|1@1+ (1.000000,0.000000) [0.000000|1.000000] "" Vector__XXX
 SG_ ESP_Stat_FallBack_eBKV  : 59|1@1+ (1.000000,0.000000) [0.000000|1.000000] "" Vector__XXX
 SG_ ESP_CM_Variante  : 60|1@1+ (1.000000,0.000000) [0.000000|1.000000] "" Vector__XXX
 SG_ ESP_OBD_Status  : 61|1@1+ (1.000000,0.000000) [0.000000|1.000000] "" Motor_BEV
 SG_ ESP_Rollenmodus_Deaktivieren  : 62|1@1+ (1.000000,0.000000) [0.000000|1.000000] "" Motor_BEV
 SG_ ESP_nachtr_Stopp_Anf  : 63|1@1+ (1.000000,0.000000) [0.000000|1.000000] "" Vector__XXX

BO_ 2527679683 ESC_ASM_01: 8 ICAS1_Gateway
 SG_ ESC_ASM_Ereignis  : 0|8@1+ (1.000000,0.000000) [1.000000|254.000000] "Unit_None" Airbag
 SG_ ESC_ASM_Zeitstempel  : 8|8@1+ (0.080000,0.000000) [0.000000|20.320000] "Unit_Secon" Airbag
 SG_ ESC_ASM_Data_1  : 16|8@1+ (1.000000,0.000000) [0.000000|255.000000] "" Airbag
 SG_ ESC_ASM_Data_2  : 24|8@1+ (1.000000,0.000000) [0.000000|255.000000] "" Airbag
 SG_ ESC_ASM_Data_3  : 32|8@1+ (1.000000,0.000000) [0.000000|255.000000] "" Airbag
 SG_ ESC_ASM_Data_4  : 40|8@1+ (1.000000,0.000000) [0.000000|255.000000] "" Airbag
 SG_ ESC_ASM_Data_5  : 48|8@1+ (1.000000,0.000000) [0.000000|255.000000] "" Airbag
 SG_ ESC_ASM_Data_6  : 56|8@1+ (1.000000,0.000000) [0.000000|255.000000] "" Airbag

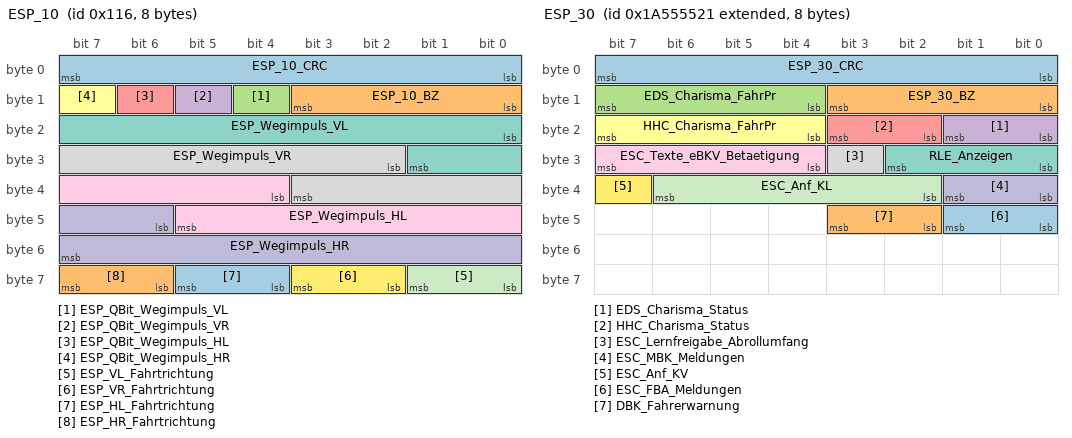
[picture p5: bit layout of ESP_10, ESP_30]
BO_ 278 ESP_10: 8 ICAS1_Gateway
 SG_ ESP_10_CRC  : 0|8@1+ (1.000000,0.000000) [0.000000|255.000000] "" Vector__XXX
 SG_ ESP_10_BZ  : 8|4@1+ (1.000000,0.000000) [0.000000|15.000000] "" Vector__XXX
 SG_ ESP_QBit_Wegimpuls_VL  : 12|1@1+ (1.000000,0.000000) [0.000000|1.000000] "" Motor_BEV
 SG_ ESP_QBit_Wegimpuls_VR  : 13|1@1+ (1.000000,0.000000) [0.000000|1.000000] "" Motor_BEV
 SG_ ESP_QBit_Wegimpuls_HL  : 14|1@1+ (1.000000,0.000000) [0.000000|1.000000] "" Motor_BEV
 SG_ ESP_QBit_Wegimpuls_HR  : 15|1@1+ (1.000000,0.000000) [0.000000|1.000000] "" Motor_BEV
 SG_ ESP_Wegimpuls_VL  : 16|10@1+ (1.000000,0.000000) [0.000000|1000.000000] "" Motor_BEV
 SG_ ESP_Wegimpuls_VR  : 26|10@1+ (1.000000,0.000000) [0.000000|1000.000000] "" Motor_BEV
 SG_ ESP_Wegimpuls_HL  : 36|10@1+ (1.000000,0.000000) [0.000000|1000.000000] "" Motor_BEV
 SG_ ESP_Wegimpuls_HR  : 46|10@1+ (1.000000,0.000000) [0.000000|1000.000000] "" Motor_BEV
 SG_ ESP_VL_Fahrtrichtung  : 56|2@1+ (1.000000,0.000000) [0.000000|3.000000] "" Motor_BEV
 SG_ ESP_VR_Fahrtrichtung  : 58|2@1+ (1.000000,0.000000) [0.000000|3.000000] "" Motor_BEV
 SG_ ESP_HL_Fahrtrichtung  : 60|2@1+ (1.000000,0.000000) [0.000000|3.000000] "" Motor_BEV
 SG_ ESP_HR_Fahrtrichtung  : 62|2@1+ (1.000000,0.000000) [0.000000|3.000000] "" Motor_BEV

BO_ 1629 ESP_20: 8 ICAS1_Gateway
 SG_ ESP_20_CRC  : 0|8@1+ (1.000000,0.000000) [0.000000|255.000000] "" Vector__XXX
 SG_ ESP_20_BZ  : 8|4@1+ (1.000000,0.000000) [0.000000|15.000000] "" Vector__XXX
 SG_ BR_Systemart  : 12|2@1+ (1.000000,0.000000) [0.000000|3.000000] "" Vector__XXX
 SG_ ESP_SpannungsAnf_02  : 14|2@1+ (1.000000,0.000000) [0.000000|3.000000] "" Vector__XXX
 SG_ ESP_Zaehnezahl  : 16|8@1+ (1.000000,0.000000) [0.000000|255.000000] "" Vector__XXX
 SG_ ESP_Charisma_FahrPr  : 24|4@1+ (1.000000,0.000000) [0.000000|15.000000] "" Vector__XXX
 SG_ ESP_Charisma_Status  : 28|2@1+ (1.000000,0.000000) [0.000000|3.000000] "" Vector__XXX
 SG_ ESP_Wiederstart_Anz_01  : 30|1@1+ (1.000000,0.000000) [0.000000|1.000000] "" Vector__XXX
 SG_ ESP_Wiederstart_Anz_02  : 31|1@1+ (1.000000,0.000000) [0.000000|1.000000] "" Vector__XXX
 SG_ ESP_Wiederstart_Anz_03  : 32|1@1+ (1.000000,0.000000) [0.000000|1.000000] "" Vector__XXX
 SG_ ESP_Wiederstart_Anz_04  : 33|1@1+ (1.000000,0.000000) [0.000000|1.000000] "" Vector__XXX
 SG_ ESP_Stoppverbot_Anz_01  : 34|1@1+ (1.000000,0.000000) [0.000000|1.000000] "" Vector__XXX
 SG_ ESP_Stoppverbot_Anz_02  : 35|1@1+ (1.000000,0.000000) [0.000000|1.000000] "" Vector__XXX
 SG_ ESP_Stoppverbot_Anz_03  : 36|1@1+ (1.000000,0.000000) [0.000000|1.000000] "" Vector__XXX
 SG_ ESP_Stoppverbot_Anz_04  : 37|1@1+ (1.000000,0.000000) [0.000000|1.000000] "" Vector__XXX
 SG_ ESP_Stoppverbot_Anz_05  : 38|1@1+ (1.000000,0.000000) [0.000000|1.000000] "" Vector__XXX
 SG_ ESP_Stoppverbot_Anz_06  : 39|1@1+ (1.000000,0.000000) [0.000000|1.000000] "" Vector__XXX
 SG_ ESP_Stoppverbot_Anz_07  : 40|1@1+ (1.000000,0.000000) [0.000000|1.000000] "" Vector__XXX
 SG_ ESP_Stoppverbot_Anz_Std  : 41|1@1+ (1.000000,0.000000) [0.000000|1.000000] "" Vector__XXX
 SG_ ESP_Dachrelingsensor  : 42|2@1+ (1.000000,0.000000) [0.000000|3.000000] "" Vector__XXX
 SG_ ESP_Stoppverbot_Anz_08  : 44|1@1+ (1.000000,0.000000) [0.000000|1.000000] "" Vector__XXX
 SG_ HDC_Charisma_FahrPr  : 45|4@1+ (1.000000,0.000000) [0.000000|15.000000] "" Vector__XXX
 SG_ HDC_Charisma_Status  : 49|2@1+ (1.000000,0.000000) [0.000000|3.000000] "" Vector__XXX
 SG_ BR_QBit_Reifenumfang  : 51|1@1+ (1.000000,0.000000) [0.000000|1.000000] "" LE1 LE2
 SG_ BR_Reifenumfang  : 52|12@1+ (1.000000,0.000000) [0.000000|4095.000000] "Unit_MilliMeter" LE1 LE2

BO_ 253 ESP_21: 8 ICAS1_Gateway
 SG_ ESP_21_CRC  : 0|8@1+ (1.000000,0.000000) [0.000000|255.000000] "" Airbag LE1 LE2 Motor_BEV
 SG_ ESP_21_BZ  : 8|4@1+ (1.000000,0.000000) [0.000000|15.000000] "" Airbag LE1 LE2 Motor_BEV
 SG_ BR_Eingriffsmoment  : 12|10@1+ (1.000000,-509.000000) [-509.000000|509.000000] "" Vector__XXX
 SG_ ESP_PLA_Bremseingriff  : 22|1@1+ (1.000000,0.000000) [0.000000|1.000000] "" Vector__XXX
 SG_ ESP_Diagnose  : 23|1@1+ (1.000000,0.000000) [0.000000|1.000000] "" Vector__XXX
 SG_ ESC_Reku_Freigabe  : 24|1@1+ (1.000000,0.000000) [0.000000|1.000000] "" Motor_BEV
 SG_ ESC_v_Signal_Qualifier_High_Low  : 25|3@1+ (1.000000,0.000000) [0.000000|7.000000] "" Airbag
 SG_ ESP_Vorsteuerung  : 28|1@1+ (1.000000,0.000000) [0.000000|1.000000] "" Motor_BEV
 SG_ ESP_AWV3_Brems_aktiv  : 29|1@1+ (1.000000,0.000000) [0.000000|1.000000] "" Vector__XXX
 SG_ OBD_Schlechtweg  : 30|1@1+ (1.000000,0.000000) [0.000000|1.000000] "" Vector__XXX
 SG_ OBD_QBit_Schlechtweg  : 31|1@1+ (1.000000,0.000000) [0.000000|1.000000] "" Vector__XXX
 SG_ ESP_v_Signal  : 32|16@1+ (0.010000,0.000000) [0.000000|655.320000] "Unit_KiloMeterPerHour" Airbag LE1 LE2 Motor_BEV
 SG_ ASR_Tastung_passiv  : 48|1@1+ (1.000000,0.000000) [0.000000|1.000000] "" Airbag Motor_BEV
 SG_ ESP_Tastung_passiv  : 49|1@1+ (1.000000,0.000000) [0.000000|1.000000] "" Airbag Motor_BEV
 SG_ ESP_Systemstatus  : 50|1@1+ (1.000000,0.000000) [0.000000|1.000000] "" Motor_BEV
 SG_ ASR_Schalteingriff  : 51|2@1+ (1.000000,0.000000) [0.000000|3.000000] "" Vector__XXX
 SG_ ESP_Haltebestaetigung  : 53|1@1+ (1.000000,0.000000) [0.000000|1.000000] "" Vector__XXX
 SG_ ESP_MKB_Abbruch_Geschw  : 54|1@1+ (1.000000,0.000000) [0.000000|1.000000] "" Vector__XXX
 SG_ ESP_QBit_v_Signal  : 55|1@1+ (1.000000,0.000000) [0.000000|1.000000] "" LE1 LE2 Motor_BEV
 SG_ ABS_Bremsung  : 56|1@1+ (1.000000,0.000000) [0.000000|1.000000] "" Airbag Motor_BEV
 SG_ ASR_Anf  : 57|1@1+ (1.000000,0.000000) [0.000000|1.000000] "" Vector__XXX
 SG_ MSR_Anf  : 58|1@1+ (1.000000,0.000000) [0.000000|1.000000] "" Vector__XXX
 SG_ EBV_Eingriff  : 59|1@1+ (1.000000,0.000000) [0.000000|1.000000] "" Vector__XXX
 SG_ EDS_Eingriff  : 60|1@1+ (1.000000,0.000000) [0.000000|1.000000] "" Motor_BEV
 SG_ ESP_Eingriff  : 61|1@1+ (1.000000,0.000000) [0.000000|1.000000] "" Airbag Motor_BEV
 SG_ ESP_ASP  : 62|1@1+ (1.000000,0.000000) [0.000000|1.000000] "" Vector__XXX
 SG_ ESP_Anhaltevorgang_ACC_aktiv  : 63|1@1+ (1.000000,0.000000) [0.000000|1.000000] "" Vector__XXX

BO_ 795 ESP_24: 8 ICAS1_Gateway
 SG_ ESP_24_CRC  : 0|8@1+ (1.000000,0.000000) [0.000000|255.000000] "" Vector__XXX
 SG_ ESP_24_BZ  : 8|4@1+ (1.000000,0.000000) [0.000000|15.000000] "" Vector__XXX
 SG_ ESP_Lampe  : 12|1@1+ (1.000000,0.000000) [0.000000|1.000000] "" Motor_BEV
 SG_ ABS_Lampe  : 13|1@1+ (1.000000,0.000000) [0.000000|1.000000] "" Vector__XXX
 SG_ BK_Lampe_02  : 14|2@1+ (1.000000,0.000000) [0.000000|3.000000] "" Vector__XXX
 SG_ TC_Lampe  : 16|1@1+ (1.000000,0.000000) [0.000000|1.000000] "" Vector__XXX
 SG_ ESP_m_Raddrehz  : 17|15@1+ (0.002000,0.000000) [0.000000|65.278000] "Unit_Hertz" Vector__XXX
 SG_ ESP_Textanzeigen_03  : 32|5@1+ (1.000000,0.000000) [0.000000|31.000000] "" Vector__XXX
 SG_ ESP_Meldungen  : 37|3@1+ (1.000000,0.000000) [0.000000|7.000000] "" Vector__XXX
 SG_ ESP_Wegimp_VA  : 40|11@1+ (1.000000,0.000000) [0.000000|2047.000000] "" Vector__XXX
 SG_ ESP_Fehlerstatus_Wegimp  : 51|1@1+ (1.000000,0.000000) [0.000000|1.000000] "" Vector__XXX
 SG_ ESP_Wegimp_Ueberlauf  : 52|1@1+ (1.000000,0.000000) [0.000000|1.000000] "" Vector__XXX
 SG_ ESP_QBit_Wegimp_VA  : 53|1@1+ (1.000000,0.000000) [0.000000|1.000000] "" Vector__XXX
 SG_ ESP_HDC_FktLampe  : 54|1@1+ (1.000000,0.000000) [0.000000|1.000000] "" Vector__XXX
 SG_ ESP_Off_Lampe  : 55|1@1+ (1.000000,0.000000) [0.000000|1.000000] "" Airbag
 SG_ ESP_HDC_Regelgeschw  : 56|7@1+ (0.320000,0.000000) [0.320000|39.680000] "Unit_KiloMeterPerHour" Vector__XXX
 SG_ ESP_BKV_Warnung  : 63|1@1+ (1.000000,0.000000) [0.000000|1.000000] "" Vector__XXX

BO_ 2589283617 ESP_30: 8 ICAS1_Gateway
 SG_ ESP_30_CRC  : 0|8@1+ (1.000000,0.000000) [0.000000|255.000000] "" Vector__XXX
 SG_ ESP_30_BZ  : 8|4@1+ (1.000000,0.000000) [0.000000|15.000000] "" Vector__XXX
 SG_ EDS_Charisma_FahrPr  : 12|4@1+ (1.000000,0.000000) [0.000000|15.000000] "" Vector__XXX
 SG_ EDS_Charisma_Status  : 16|2@1+ (1.000000,0.000000) [0.000000|3.000000] "" Vector__XXX
 SG_ HHC_Charisma_Status  : 18|2@1+ (1.000000,0.000000) [0.000000|3.000000] "" Vector__XXX
 SG_ HHC_Charisma_FahrPr  : 20|4@1+ (1.000000,0.000000) [0.000000|15.000000] "" Vector__XXX
 SG_ RLE_Anzeigen  : 24|3@1+ (1.000000,0.000000) [0.000000|7.000000] "" Vector__XXX
 SG_ ESC_Lernfreigabe_Abrollumfang  : 27|1@1+ (1.000000,0.000000) [0.000000|1.000000] "" Vector__XXX
 SG_ ESC_Texte_eBKV_Betaetigung  : 28|4@1+ (1.000000,0.000000) [0.000000|15.000000] "" Vector__XXX
 SG_ ESC_MBK_Meldungen  : 32|2@1+ (1.000000,0.000000) [0.000000|3.000000] "" Vector__XXX
 SG_ ESC_Anf_KL  : 34|5@1+ (3.225806,0.000000) [0.000000|100.000000] "Unit_PerCent" Motor_BEV
 SG_ ESC_Anf_KV  : 39|1@1+ (1.000000,0.000000) [0.000000|1.000000] "" Motor_BEV
 SG_ ESC_FBA_Meldungen  : 40|2@1+ (1.000000,0.000000) [0.000000|3.000000] "" Vector__XXX
 SG_ DBK_Fahrerwarnung  : 42|2@1+ (1.000000,0.000000) [0.000000|3.000000] "" Vector__XXX

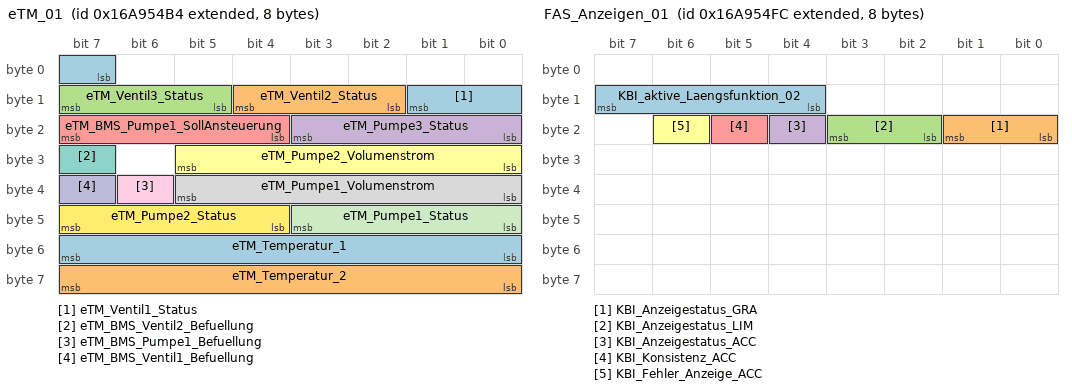
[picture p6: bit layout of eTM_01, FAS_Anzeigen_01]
BO_ 2527679668 eTM_01: 8 Motor_BEV
 SG_ eTM_Ventil1_Status  : 7|3@1+ (1.000000,0.000000) [0.000000|7.000000] "" ICAS1_Gateway
 SG_ eTM_Ventil2_Status  : 10|3@1+ (1.000000,0.000000) [0.000000|7.000000] "" ICAS1_Gateway
 SG_ eTM_Ventil3_Status  : 13|3@1+ (1.000000,0.000000) [0.000000|7.000000] "" ICAS1_Gateway
 SG_ eTM_Pumpe3_Status  : 16|4@1+ (10.000000,0.000000) [0.000000|130.000000] "Unit_PerCent" ICAS1_Gateway
 SG_ eTM_BMS_Pumpe1_SollAnsteuerung  : 20|4@1+ (10.000000,0.000000) [0.000000|130.000000] "Unit_PerCent" ICAS1_Gateway
 SG_ eTM_Pumpe2_Volumenstrom  : 24|6@1+ (0.500000,0.000000) [0.000000|30.500000] "Unit_LiterPerMinut" ICAS1_Gateway LE1 LE2
 SG_ eTM_BMS_Ventil2_Befuellung  : 31|1@1+ (1.000000,0.000000) [0.000000|1.000000] "" ICAS1_Gateway
 SG_ eTM_Pumpe1_Volumenstrom  : 32|6@1+ (0.500000,0.000000) [0.000000|30.500000] "Unit_LiterPerMinut" ICAS1_Gateway LE1 LE2
 SG_ eTM_BMS_Pumpe1_Befuellung  : 38|1@1+ (1.000000,0.000000) [0.000000|1.000000] "" ICAS1_Gateway
 SG_ eTM_BMS_Ventil1_Befuellung  : 39|1@1+ (1.000000,0.000000) [0.000000|1.000000] "" ICAS1_Gateway
 SG_ eTM_Pumpe1_Status  : 40|4@1+ (10.000000,0.000000) [0.000000|130.000000] "Unit_PerCent" ICAS1_Gateway LE1 LE2
 SG_ eTM_Pumpe2_Status  : 44|4@1+ (10.000000,0.000000) [0.000000|130.000000] "Unit_PerCent" ICAS1_Gateway LE1 LE2
 SG_ eTM_Temperatur_1  : 48|8@1+ (0.750000,-40.000000) [-40.000000|149.750000] "Unit_DegreCelsi" ICAS1_Gateway LE1 LE2
 SG_ eTM_Temperatur_2  : 56|8@1+ (0.750000,-40.000000) [-40.000000|149.750000] "Unit_DegreCelsi" ICAS1_Gateway LE1 LE2

BO_ 2527679740 FAS_Anzeigen_01: 8 ICAS1_KommunikationsServer
 SG_ KBI_aktive_Laengsfunktion_02  : 12|4@1+ (1.000000,0.000000) [0.000000|15.000000] "" Motor_BEV
 SG_ KBI_Anzeigestatus_GRA  : 16|2@1+ (1.000000,0.000000) [0.000000|3.000000] "" Motor_BEV
 SG_ KBI_Anzeigestatus_LIM  : 18|2@1+ (1.000000,0.000000) [0.000000|3.000000] "" Motor_BEV
 SG_ KBI_Anzeigestatus_ACC  : 20|1@1+ (1.000000,0.000000) [0.000000|1.000000] "" Vector__XXX
 SG_ KBI_Konsistenz_ACC  : 21|1@1+ (1.000000,0.000000) [0.000000|1.000000] "" Vector__XXX
 SG_ KBI_Fehler_Anzeige_ACC  : 22|1@1+ (1.000000,0.000000) [0.000000|1.000000] "" Vector__XXX

BO_ 2589283684 FoD_01: 8 ICAS1_Gateway
 SG_ GRA_FoD_Status  : 58|2@1+ (1.000000,0.000000) [0.000000|3.000000] "" Vector__XXX
 SG_ FoD_Transmission_Info  : 60|2@1+ (1.000000,0.000000) [0.000000|3.000000] "" Motor_BEV

BO_ 2549875574 FoD_MO_01_Req: 8 ICAS1_Gateway
 SG_ FoD_MO_01_Req_Data  : 0|64@1+ (1.000000,0.000000) [0.000000|18446744073709551616.000000] "" Motor_BEV

BO_ 2550006646 FoD_MO_01_Resp: 8 Motor_BEV
 SG_ FoD_MO_01_Resp_Data  : 0|64@1+ (1.000000,0.000000) [0.000000|18446744073709551616.000000] "" ICAS1_Gateway

BO_ 987 Gateway_72: 8 ICAS1_Gateway
 SG_ BCM_01_alt  : 0|1@1+ (1.000000,0.000000) [0.000000|1.000000] "" Airbag
 SG_ SMLS_01_alt  : 1|1@1+ (1.000000,0.000000) [0.000000|1.000000] "" Vector__XXX
 SG_ ZV_02_alt  : 2|1@1+ (1.000000,0.000000) [0.000000|1.000000] "" Vector__XXX
 SG_ Wischer_01_alt  : 3|1@1+ (1.000000,0.000000) [0.000000|1.000000] "" Vector__XXX
 SG_ Anhaenger_01_alt  : 4|1@1+ (1.000000,0.000000) [0.000000|1.000000] "" Airbag
 SG_ Klima_Sensor_02_alt  : 5|1@1+ (1.000000,0.000000) [0.000000|1.000000] "" Vector__XXX
 SG_ Verdeck_01_alt  : 6|1@1+ (1.000000,0.000000) [0.000000|1.000000] "" Vector__XXX
 SG_ Klima_11_alt  : 7|1@1+ (1.000000,0.000000) [0.000000|1.000000] "" Vector__XXX
 SG_ WFS_01_alt  : 8|1@1+ (1.000000,0.000000) [0.000000|1.000000] "" Vector__XXX
 SG_ Licht_Anf_01_alt  : 9|1@1+ (1.000000,0.000000) [0.000000|1.000000] "" Vector__XXX
 SG_ ZV_verriegelt_extern_soll  : 10|1@1+ (1.000000,0.000000) [0.000000|1.000000] "" Vector__XXX
 SG_ BH_Lichthupe  : 11|1@1+ (1.000000,0.000000) [0.000000|1.000000] "" Vector__XXX
 SG_ WFS_Klemmenfreigabe  : 12|1@1+ (1.000000,0.000000) [0.000000|1.000000] "" Vector__XXX
 SG_ ZV_Tankklappe_offen  : 13|1@1+ (1.000000,0.000000) [0.000000|1.000000] "" Vector__XXX
 SG_ AAG_Anhaenger_abgesteckt  : 14|1@1+ (1.000000,0.000000) [0.000000|1.000000] "" Vector__XXX
 SG_ BCM1_LDS_Stellung  : 15|3@1+ (1.000000,0.000000) [0.000000|7.000000] "" Vector__XXX
 SG_ VS_Verdeck_Anf  : 18|1@1+ (1.000000,0.000000) [0.000000|1.000000] "" Vector__XXX
 SG_ VS_VD_entriegelt  : 19|1@1+ (1.000000,0.000000) [0.000000|1.000000] "" Vector__XXX
 SG_ ZV_HFS_offen  : 20|1@1+ (1.000000,0.000000) [0.000000|1.000000] "" Vector__XXX
 SG_ ZV_HBFS_offen  : 21|1@1+ (1.000000,0.000000) [0.000000|1.000000] "" Vector__XXX
 SG_ VS_VD_offen_ver  : 22|1@1+ (1.000000,0.000000) [0.000000|1.000000] "" Vector__XXX
 SG_ VS_VD_zu_ver  : 23|1@1+ (1.000000,0.000000) [0.000000|1.000000] "" Vector__XXX
 SG_ ZV_BT_offen  : 24|1@1+ (1.000000,0.000000) [0.000000|1.000000] "" Vector__XXX
 SG_ BCM1_Rueckfahrlicht_Schalter  : 25|1@1+ (1.000000,0.000000) [0.000000|1.000000] "" Airbag Motor_BEV
 SG_ ZV_FT_offen  : 26|1@1+ (1.000000,0.000000) [0.000000|1.000000] "" Vector__XXX
 SG_ Wischer_vorne_aktiv  : 27|1@1+ (1.000000,0.000000) [0.000000|1.000000] "" Vector__XXX
 SG_ AAG_Anhaenger_erkannt  : 28|1@1+ (1.000000,0.000000) [0.000000|1.000000] "" Airbag
 SG_ BCM1_MH_Schalter  : 29|1@1+ (1.000000,0.000000) [0.000000|1.000000] "" Vector__XXX
 SG_ ZV_HD_offen  : 30|1@1+ (1.000000,0.000000) [0.000000|1.000000] "" Vector__XXX
 SG_ Waschen_vorne_aktiv  : 31|1@1+ (1.000000,0.000000) [0.000000|1.000000] "" Vector__XXX
 SG_ KL_Thermomanagement  : 32|2@1+ (1.000000,0.000000) [0.000000|3.000000] "" Vector__XXX
 SG_ WFS_Schluessel_Fahrberecht  : 34|4@1+ (1.000000,0.000000) [0.000000|15.000000] "" Vector__XXX
 SG_ BCM_Rueckfahrlicht_Anf  : 38|1@1+ (1.000000,0.000000) [0.000000|1.000000] "" Vector__XXX
 SG_ WWSs_01_alt  : 39|1@1+ (1.000000,0.000000) [0.000000|1.000000] "" Vector__XXX
 SG_ BCM_Tankklappensteller_Fehler  : 40|1@1+ (1.000000,0.000000) [0.000000|1.000000] "" Vector__XXX
 SG_ AAG_LED_aktiv  : 41|1@1+ (1.000000,0.000000) [0.000000|1.000000] "" Vector__XXX
 SG_ ZV_verriegelt_soll  : 42|2@1+ (1.000000,0.000000) [0.000000|3.000000] "" Vector__XXX
 SG_ ZV_Schluessel_Zugang  : 44|4@1+ (1.000000,0.000000) [0.000000|15.000000] "" Vector__XXX
 SG_ WFS_ID_Geb_autorisiert_in_Kl15  : 48|1@1+ (1.000000,0.000000) [0.000000|1.000000] "" Vector__XXX
 SG_ BH_Fernlicht  : 49|1@1+ (1.000000,0.000000) [0.000000|1.000000] "" Vector__XXX
 SG_ BH_Blinker_li  : 50|1@1+ (1.000000,0.000000) [0.000000|1.000000] "" Vector__XXX
 SG_ BH_Blinker_re  : 51|1@1+ (1.000000,0.000000) [0.000000|1.000000] "" Vector__XXX
 SG_ BCM1_OBD_FStatus_ATemp  : 52|4@1+ (1.000000,0.000000) [0.000000|15.000000] "" Vector__XXX
 SG_ BCM1_Aussen_Temp_ungef  : 56|8@1+ (0.500000,-50.000000) [-50.000000|76.000000] "Unit_DegreCelsi" Vector__XXX

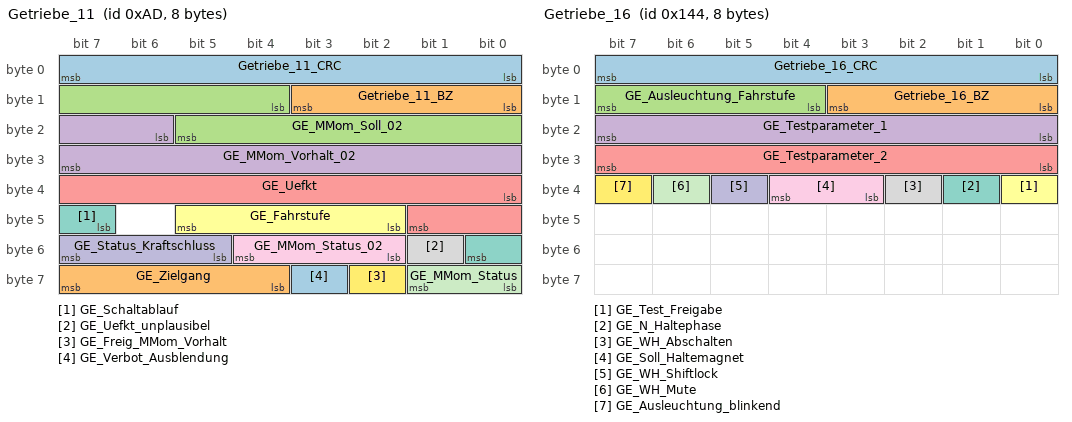
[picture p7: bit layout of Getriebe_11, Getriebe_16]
BO_ 173 Getriebe_11: 8 Motor_BEV
 SG_ Getriebe_11_CRC  : 0|8@1+ (1.000000,0.000000) [0.000000|255.000000] "" ICAS1_Gateway
 SG_ Getriebe_11_BZ  : 8|4@1+ (1.000000,0.000000) [0.000000|15.000000] "" ICAS1_Gateway
 SG_ GE_MMom_Soll_02  : 12|10@1+ (1.000000,-509.000000) [-509.000000|509.000000] "" ICAS1_Gateway
 SG_ GE_MMom_Vorhalt_02  : 22|10@1+ (1.000000,-509.000000) [-509.000000|509.000000] "" ICAS1_Gateway
 SG_ GE_Uefkt  : 32|10@1+ (0.100000,0.000000) [0.000000|102.200000] "" ICAS1_Gateway
 SG_ GE_Fahrstufe  : 42|4@1+ (1.000000,0.000000) [0.000000|15.000000] "" ICAS1_Gateway
 SG_ GE_Schaltablauf  : 47|2@1+ (1.000000,0.000000) [0.000000|3.000000] "" ICAS1_Gateway
 SG_ GE_Uefkt_unplausibel  : 49|1@1+ (1.000000,0.000000) [0.000000|1.000000] "" ICAS1_Gateway
 SG_ GE_MMom_Status_02  : 50|3@1+ (1.000000,0.000000) [0.000000|7.000000] "" ICAS1_Gateway
 SG_ GE_Status_Kraftschluss  : 53|3@1+ (1.000000,0.000000) [0.000000|7.000000] "" ICAS1_Gateway
 SG_ GE_MMom_Status  : 56|2@1+ (1.000000,0.000000) [0.000000|3.000000] "" ICAS1_Gateway
 SG_ GE_Freig_MMom_Vorhalt  : 58|1@1+ (1.000000,0.000000) [0.000000|1.000000] "" ICAS1_Gateway
 SG_ GE_Verbot_Ausblendung  : 59|1@1+ (1.000000,0.000000) [0.000000|1.000000] "" ICAS1_Gateway
 SG_ GE_Zielgang  : 60|4@1+ (1.000000,0.000000) [0.000000|15.000000] "" ICAS1_Gateway

BO_ 324 Getriebe_16: 8 Motor_BEV
 SG_ Getriebe_16_CRC  : 0|8@1+ (1.000000,0.000000) [0.000000|255.000000] "" ICAS1_Gateway Schaltbetaetigung
 SG_ Getriebe_16_BZ  : 8|4@1+ (1.000000,0.000000) [0.000000|15.000000] "" ICAS1_Gateway Schaltbetaetigung
 SG_ GE_Ausleuchtung_Fahrstufe  : 12|4@1+ (1.000000,0.000000) [0.000000|15.000000] "" ICAS1_Gateway Schaltbetaetigung
 SG_ GE_Testparameter_1  : 16|8@1+ (1.000000,0.000000) [0.000000|255.000000] "" ICAS1_Gateway Schaltbetaetigung
 SG_ GE_Testparameter_2  : 24|8@1+ (1.000000,0.000000) [0.000000|255.000000] "" ICAS1_Gateway Schaltbetaetigung
 SG_ GE_Test_Freigabe  : 32|1@1+ (1.000000,0.000000) [0.000000|1.000000] "" ICAS1_Gateway Schaltbetaetigung
 SG_ GE_N_Haltephase  : 33|1@1+ (1.000000,0.000000) [0.000000|1.000000] "" ICAS1_Gateway Schaltbetaetigung
 SG_ GE_WH_Abschalten  : 34|1@1+ (1.000000,0.000000) [0.000000|1.000000] "" ICAS1_Gateway Schaltbetaetigung
 SG_ GE_Soll_Haltemagnet  : 35|2@1+ (1.000000,0.000000) [0.000000|3.000000] "" ICAS1_Gateway Schaltbetaetigung
 SG_ GE_WH_Shiftlock  : 37|1@1+ (1.000000,0.000000) [0.000000|1.000000] "" ICAS1_Gateway Schaltbetaetigung
 SG_ GE_WH_Mute  : 38|1@1+ (1.000000,0.000000) [0.000000|1.000000] "" ICAS1_Gateway Schaltbetaetigung
 SG_ GE_Ausleuchtung_blinkend  : 39|1@1+ (1.000000,0.000000) [0.000000|1.000000] "" ICAS1_Gateway Schaltbetaetigung

CM_ BO_ 1603 "abMQBmit8Byte";
CM_ BO_ 1629 "neuimMQB";
CM_ BO_ 253 "NeueMomenteimMQB
Struktur ab MQB mit CRC8 entstanden aus ESP_01";
CM_ BO_ 795 "neufürMQBwg.Absicherung
Entstanden aus ESP_04";
CM_ BO_ 987 "Komfort->Antrieb,Extended,Fahrwerk,Infotainment";
CM_ SG_ 1603 KBI_Einheit_Datum "AnzeigevariantedesDatums";
CM_ SG_ 1603 KBI_Einheit_Druck "EinheitdesDruckes";
CM_ SG_ 1603 KBI_Einheit_Streckenanz "EinheitderStreckenanzeige";
CM_ SG_ 1603 KBI_MFA_v_Einheit_02 "EinheitderGeschwindigkeit,dievomFahrerimCar-Menügewähltwurde.VeränderlicheGrösse,imGegensatzzurEinheitdesTachokranzes.

Redundant in der Einheiten_01 Botschaft definiert, um Konsistenz zur BAP-Festlegung zu haben.";
CM_ SG_ 1603 KBI_Einheit_Temp "EinheitderTemperatur";
CM_ SG_ 1603 KBI_Einheit_Uhrzeit "AnzeigevariantederUhrzeit";
CM_ SG_ 1603 KBI_Einheit_Verbrauch "EinheitderVerbrauchs";
CM_ SG_ 1603 KBI_Einheit_Volumen "EinheitdesVolumens";
CM_ SG_ 1603 KBI_Einheit_Verbrauch_elektr "EinheitelektrischerVerbrauch";
CM_ SG_ 1603 KBI_Einheit_Tacho "Information,obessichumMeilen-oderKmh-Kombihandelt,EinheitdesTachosentsprichtdemZifferblatt,Grösseistnichtveränderlich";
CM_ SG_ 1603 KBI_Einheit_Sprache "SieheBAP-DatenfestlegungUnitMaster";
CM_ SG_ 1603 KBI_Einheit_Verbrauch_Gas "UnterscheidungzwischenM3/hundkg/hfürKomfortverbrauchsberechnung.";
CM_ SG_ 1603 KBI_Einheit_Masse "EinheitderMasse(Verwendungz.B.ASTA)";
CM_ SG_ 192 EM1_01_CRC "FürMLB:
Berechnung siehe Lastenheft 'Kommunikationsabsicherung für FlexRay und CAN'
Ab MQB und MLBevo:
Berechnung siehe Lastenheft 'End-to-End Kommunikationsabsicherung'

Endwerte siehe Begleitdokument 'S-PDU Kennungsfolgen'";
CM_ SG_ 192 EM1_01_BZ "4bitBotschaftszähler,wirdmitjederSendebotschaftinkrementiert";
CM_ SG_ 192 EM1_Istmodus "aktuelleBetriebsartderE-Maschine...
0: Standby; Kommunikation aktiv; PSM: Aktiver Kurzschluss eingenommen
1: Momentenreglung
2: Drehzahlregeung (interner Regelkreis)
3: Spannungsregelung
4: Drehzahlregelung (externer Regelkreis)
5: interner Inver";
CM_ SG_ 192 EM1_IstMoment "Momentanwert:E-MaschinenMoment";
CM_ SG_ 192 EM1_Moment_AR_Eingriff "Momentanwert:EingriffsmomentderAnti-Ruckel-FunktionimPWR";
CM_ SG_ 192 EM1_IstDrehzahl "Momentanwert:E-MaschinenDrehzahl";
CM_ SG_ 192 EM1_AR_aktiv "Ruckeldämpferaktiv";
CM_ SG_ 192 EM1_IstSpannung "Momentanwert:HV-SpannungamPWR";
CM_ SG_ 192 EM1_Strom_HV "Momentanwert:HVDC-StromdesPWR";
CM_ SG_ 192 EM1_Max_Moment "maximaldarstellbaresMomentfüreineimFunktionslastenheftdefinierteDauer

Die Berechnung der Momentengrenzen wird projektspezifisch festgelegt";
CM_ SG_ 192 EM1_ErwGrenzen_aktiv "DieabsolutenMomentengrenzensindfürdieDurchführungeinesVKM-Startsggf.aufgeweitet";
CM_ SG_ 192 EM1_Min_Moment "minimaldarstellbaresMomentfüreineimFunktionslastenheftdefinierteDauer

Die Berechnung der Momentengrenzen wird projektspezifisch festgelegt
";
CM_ SG_ 192 EM1_Fehler_ElAntriebAbschaltung "Fehler:PWRbefindetsichimaktivenKurzschluss
alle vom EMS gesendeten Max- und Min-Momente und das aktuelle EM-Moment nehmen in diesem Zustand den Wert des für die aktuelle Drehzahl entsprechenden Schleppmoments der E-Maschine an";
CM_ SG_ 192 EM1_Max_Moment_Lim "MaximalesMomentbeidermomentanenMaschinendrehzahl,motorischerBetrieb,berechnetausAbregelstromMO_EMx_Max_Strom_LimundaktuellerSpannung";
CM_ SG_ 192 EM1_Fehler_Notabschaltung "Fehler:LeistungselektronikfordertAbschaltungdesHV-NetzeswegeneinesschwerenFehlersan";
CM_ SG_ 192 EM1_Min_Moment_Lim "MinimalesMomentbeidermomentanenMaschinendrehzahl,generatorischerBetrieb,berechnetausAbregelstromMO_EMx_Min_Strom_LimundaktuellerSpannung";
CM_ SG_ 192 EM1_Status_DrzEingriff "StatusASR-EingriffüberEM-Regelung";
CM_ SG_ 192 EM1_Mom_DrzEingriff "WirksamesMomentderEMzumBegrenzenderDrehzahlaufDrehzahlbegrenzung";
CM_ SG_ 2463978673 EM1_Status_Spgfreiheit "0=Init(ohneFunktion)
1 = Leistungselektronik HV-Komponenten spannungsfrei (U_Zwkr < 20V)
2 = Leistungselektronik HV_Komponenten nicht spannungsfrei (U_Zwkr >= 20V)
3 = Fehler (z. B. Fehler in der Sensorik)";
CM_ SG_ 2463978673 EM1_Status_EoHVL "StatusderHV-SpannungamPWRfürdieFunktionEoHVL";
CM_ SG_ 2463978673 EM1_Max_LeistungMech_Sockel "MaximalmöglichemechanischeLeistungoberhalbdesEckpunkts,bezogenaufdiezugeteilteelektrischeLeistung,";
CM_ SG_ 2463978673 EM1_Max_Moment_Sockel "MaximalmöglichesMomentbiszumEckpunktbezogenaufdiezugeteilteelektrischeLeistung,motorischerBetrieb";
CM_ SG_ 2463978673 EM1_Min_LeistungMech_Sockel "MinimalmöglichemechanischeLeistungoberhalbdesEckpunkts,bezogenaufdiezugeteilteelektrischeLeistung,generatorischerBetrieb";
CM_ SG_ 2463978673 EM1_Min_Moment_Sockel "MinimalmöglichesMomentbiszumEckpunktbezogenaufdiezugeteilteelektrischeLeistung,generatorischerBetrieb";
CM_ SG_ 2463978673 EM1_PerfInd_MaxLeistung "Performance-IndikatorfürdieVerfügbarkeitderMaximalleistung";
CM_ SG_ 2463978673 EM1_PerfInd_MaxMoment "Performance-IndikatorfürdieVerfügbarkeitdesMaximalmoments";
CM_ SG_ 2463978673 EM1_AnlernenElMotor_Anf "DiagnoseanforderungvonE-Maschine/PWR:Hybrid-ControllerschaltetüberMO_EM_Sollmodus=6bzw.MY3_EM_modeReq=6E-Maschine/PWRaktivindenKalibriermodus(Strategiemusssicherstellen,dasskeinMomentbeiderEMangefordertwird.)";
CM_ SG_ 2463978673 EM1_OBD_Lampe_Anf "InallenVW-/Audi-FahrzeugenisteinMIL-Master-Konzeptumgesetzt.DazuermitteltjedesOBD-SteuergerätdeneigenenMIL-Status.EineMIL-AnsteuerungwirdvombetroffenenOBD-SteuergerätperMIL-RequestüberCANandenMIL-Masterweitergegeben.DerMIL-Mas";
CM_ SG_ 2463978673 EM1_Generator_Moment "ErforderlichesgeneratorischesMomentzurDarstellungderelektrischenWunschleistungbeidermomentanenMaschinendrehzahl";
CM_ SG_ 2463978673 EM1_PerfInd_Temperatur "ThermischerPerformance-IndikatorabhängigvonMaschinen-undLE-Temperatur";
CM_ SG_ 2463978673 EM1_MaxZul_Drehzahl "EM1_MaxZul_DrehzahlstelltdiemaximaleDrehzahlgrenzefürLEbzw.EMdardieimFreilaufzulässigist.FürDrehzahlengrößerdieserGrenzewirddieLEzumKomponentenschutzunabhängigvonderKommandierungindenAKSumschalten.";
CM_ SG_ 2463978673 EM1_Min_Moment_Gesamt "MinimalmöglichesMomentbeidermomentanenMaschinendrehzahlbezogenaufdievomSystemaufnehmbareelektrischeGesamtleistungMO_EM1_Min_Leistung_Gesamt,generatorischerBetrieb";
CM_ SG_ 2463978673 EM1_Fehlerlampe_Anf "AnforderungderrotenHybrid-WarnlampeimKombi";
CM_ SG_ 2463978673 EM1_Max_Moment_Gesamt "MaximalmöglichesMomentbeidermomentanenMaschinendrehzahlbezogenaufdieimSystemverfügbareelektrischeGesamtleistungMO_EM1_Max_Leistung_Gesamt,motorischerBetrieb";
CM_ SG_ 2463978673 EM1_Warnlampe_Anf "AnforderungdergelbenHybrid-WarnlampeimKombi";
CM_ SG_ 2463978673 EM1_Rekuperation "Rekuperation-EnergiederEMgetriebeintegriert";
CM_ SG_ 2463978673 EM1_Rekuperation_Ueberlauf "RekuperationleistungssignalEM1_Rekuperationmindest1xübergelaufen";
CM_ SG_ 2463978673 EM1_Verbrauch "Antriebs-EnergiederEM1getriebeintegriert";
CM_ SG_ 2463978673 EM1_Verbrauch_Ueberlauf "Überlauf-BitfürdasSignalEM1_Verbrauch.
Rekuperationleistungssignal mindest 1x übergelaufen;";
CM_ SG_ 2463978673 EM1_Fehler_AE "AusgabeeinesFehlersinderFunktionaktiveEntladungimPWR";
CM_ SG_ 2463978673 EM1_Fehler_Leistungsred "EingeschränkteLeistungsfähigkeitaufGrundeinsinternenFehlers";
CM_ SG_ 2463978673 EM1_Fehler_ElAntriebFreilauf "Fehler:EMimFreilauf;LeistungselektronikfordertBegrenzungdermaximalenDrehzahlan,umÜberspannungimHV-Zwischenkreiszuvermeiden";
CM_ SG_ 2463978673 EM1_PWR_SollVolumenstrom "FürdieKühlungdesPWRaktuellmindestensbenötigterKühlwasservolumenstrom";
CM_ SG_ 2589283657 EM1_SollVorlauftemperatur "SolltemperaturdesKühlmittelsamVorlaufdesPWR";
CM_ SG_ 2589283657 EM1_Temperatur_EM "TemperaturderE-Maschine";
CM_ SG_ 2589283657 EM1_EM_SollVolumenstrom "FürdieKühlungderE-MaschineaktuellmindestensbenötigterKühlwasservolumenstrom


MQB/MEB: funktional 500ms (Cyclic) Zykluszeit notwendig

MLBevo: funktional 50ms (OnChange) Zykluszeit notwendig";
CM_ SG_ 2589283657 EM1_Max_MechLeistung_nom "MaximaleparametrierteLeistungdeselektrischenAntriebsbestehendausPWRundEM,interneBegrenzung";
CM_ SG_ 2589283657 EM1_Max_Moment_nom "MaximalesparametriertesMomentdeselektrischenAntriebsbestehendausPWRundEM,interneBegrenzung";
CM_ SG_ 2589283657 EM1_Temperatur_PWR "Momentanwert:TemperaturdesPWR";
CM_ SG_ 184 EM1_Freigabe_Info_WFS "WFS-Freigabeinformation";
CM_ SG_ 184 EM1_Sperr_Info_WFS "WFS-Sperrinformation
";
CM_ SG_ 184 EM1_AR_aktiv "Ruckeldämpferaktiv";
CM_ SG_ 184 EM1_Eta_Sys "InstantaneousefficiencyofelectricaldriveEM1/MomentanerWirkungsgradelektrischerAntriebEM1";
CM_ SG_ 184 EM1_IstStrom "Momentanwert:StromüberPWR";
CM_ SG_ 184 EM1_Fehler_ElAntriebFreilauf_Anf "WirdgesetztumdenzwingendenBedarfeinerUmschaltungindenFreilaufanzuzeigen.VergleicheSignalEM1_MaxZul_Drehzahl.";
CM_ SG_ 184 EM1_Abregelung_Temperatur "LeistungsbegrenzungaufgrundÜbertemperaturderE-Maschine/desPWR";
CM_ SG_ 184 EM1_AnlernenElMotor_Anf "DiagnoseanforderungvonE-Maschine/PWR:Hybrid-ControllerschaltetüberMO_EM_Sollmodus=6bzw.MY3_EM_modeReq=6E-Maschine/PWRaktivindenKalibriermodus(Strategiemusssicherstellen,dasskeinMomentbeiderEMangefordertwird.)";
CM_ SG_ 184 EM1_Moment_HVVerbraucher "rechnerischbenötigtesGenerator-Moment,umdenBedarfderel.Nebenverbraucherincl.Batterieladungabzudecken";
CM_ SG_ 184 EM1_Freigabe_Verfallsinfo_WFS "WFS";
CM_ SG_ 184 EM1_Parken_WFS_Status "StatusderLimitierung";
CM_ SG_ 184 EM1_HV_betriebsbereit "1:Ready_HV/1:HV-NetzSpannungimBetriebsbereich";
CM_ SG_ 2527679712 EM1_RtmWarnKommunikation "RealTimeMonitoringEM1buscommunicationfault";
CM_ SG_ 2527679712 EM1_RtmWarnUeberdrehzahl "RTMSignaloverspeedwarningEM1";
CM_ SG_ 2527679712 EM1_RtmWarnUeberstrom "RTMSignalover-currentwarningEM1";
CM_ SG_ 2527679712 EM1_RtmWarnTempEM "RTMSignalover-tempwarningEM1";
CM_ SG_ 2527679712 EM1_RtmWarnTempPWR "RTMSignalover-tempwarningEM1-PWR";
CM_ SG_ 193 EM2_01_CRC "FürMLB:
Berechnung siehe Lastenheft 'Kommunikationsabsicherung für FlexRay und CAN'
Ab MQB und MLBevo:
Berechnung siehe Lastenheft 'End-to-End Kommunikationsabsicherung'

Endwerte siehe Begleitdokument 'S-PDU Kennungsfolgen'";
CM_ SG_ 193 EM2_01_BZ "4bitBotschaftszähler,wirdmitjederSendebotschaftinkrementiert";
CM_ SG_ 193 EM2_Istmodus "aktuelleBetriebsartderE-Maschine...
0: Standby; Kommunikation aktiv; PSM: Aktiver Kurzschluss eingenommen
1: Momentenreglung
2: Drezahlregeung (interner Regelkreis)
3: Spannungsregelung
4: Drehzahlregelung (externer Regelkreis)
5: interner Invert";
CM_ SG_ 193 EM2_IstMoment "Momentanwert:E-MaschinenMoment";
CM_ SG_ 193 EM2_Moment_AR_Eingriff "Momentanwert:EingriffsmomentderAnti-Ruckel-FunktionimPWR";
CM_ SG_ 193 EM2_IstDrehzahl "Momentanwert:E-MaschinenDrehzahl";
CM_ SG_ 193 EM2_AR_aktiv "Ruckeldämpferaktiv";
CM_ SG_ 193 EM2_IstSpannung "Momentanwert:HV-SpannungamPWR";
CM_ SG_ 193 EM2_Strom_HV "Momentanwert:HVDC-StromdesPWR";
CM_ SG_ 193 EM2_Max_Moment "maximaldarstellbaresMomentfüreineimFunktionslastenheftdefinierteDauer

Die Berechnung der Momentengrenzen wird projektspezifisch festgelegt
";
CM_ SG_ 193 EM2_ErwGrenzen_aktiv "DieabsolutenMomentengrenzensindfürdieDurchführungeinesVKM-Startsggf.aufgeweitet";
CM_ SG_ 193 EM2_Min_Moment "minimaldarstellbaresMomentfüreineimFunktionslastenheftdefinierteDauer

Die Berechnung der Momentengrenzen wird projektspezifisch festgelegt
";
CM_ SG_ 193 EM2_Fehler_ElAntriebAbschaltung "Fehler:PWRbefindetsichimaktivenKurzschluss
alle vom EMS gesendeten Max- und Min-Momente und das aktuelle EM-Moment nehmen in diesem Zustand den Wert des für die aktuelle Drehzahl entsprechenden Schleppmoments der E-Maschine an";
CM_ SG_ 193 EM2_Max_Moment_Lim "MaximalesMomentbeidermomentanenMaschinendrehzahl,motorischerBetrieb,berechnetausAbregelstromMO_EMx_Max_Strom_LimundaktuellerSpannung";
CM_ SG_ 193 EM2_Fehler_Notabschaltung "Fehler:LeistungselektronikfordertAbschaltungdesHV-NetzeswegeneinesschwerenFehlersan";
CM_ SG_ 193 EM2_Min_Moment_Lim "MinimalesMomentbeidermomentanenMaschinendrehzahl,generatorischerBetrieb,berechnetausAbregelstromMO_EMx_Min_Strom_LimundaktuellerSpannung";
CM_ SG_ 193 EM2_Status_DrzEingriff "StatusASR-EingriffüberEM-Regelung";
CM_ SG_ 193 EM2_Mom_DrzEingriff "WirksamesMomentderEMzumBegrenzenderDrehzahlaufDrehzahlbegrenzung";
CM_ SG_ 2463978674 EM2_Status_Spgfreiheit "0=Init(ohneFunktion)
1 = Leistungselektronik HV-Komponenten spannungsfrei (U_Zwkr < 20V)
2 = Leistungselektronik HV_Komponenten nicht spannungsfrei (U_Zwkr >= 20V)
3 = Fehler (z. B. Fehler in der Sensorik)";
CM_ SG_ 2463978674 EM2_Status_EoHVL "StatusderHV-SpannungamPWRfürdieFunktionEoHVL";
CM_ SG_ 2463978674 EM2_Max_LeistungMech_Sockel "MaximalmöglichemechanischeLeistungoberhalbdesEckpunkts,bezogenaufdiezugeteilteelektrischeLeistung,";
CM_ SG_ 2463978674 EM2_Max_Moment_Sockel "MaximalmöglichesMomentbiszumEckpunktbezogenaufdiezugeteilteelektrischeLeistung,motorischerBetrieb";
CM_ SG_ 2463978674 EM2_Min_LeistungMech_Sockel "MinimalmöglichemechanischeLeistungoberhalbdesEckpunkts,bezogenaufdiezugeteilteelektrischeLeistung,generatorischerBetrieb";
CM_ SG_ 2463978674 EM2_Min_Moment_Sockel "MinimalmöglichesMomentbiszumEckpunktbezogenaufdiezugeteilteelektrischeLeistung,generatorischerBetrieb";
CM_ SG_ 2463978674 EM2_PerfInd_MaxLeistung "Performance-IndikatorfürdieVerfügbarkeitderMaximalleistung";
CM_ SG_ 2463978674 EM2_PerfInd_MaxMoment "Performance-IndikatorfürdieVerfügbarkeitdesMaximalmoments";
CM_ SG_ 2463978674 EM2_AnlernenElMotor_Anf "DiagnoseanforderungvonE-Maschine/PWR:Hybrid-ControllerschaltetüberMO_EM_Sollmodus=6bzw.MY3_EM_modeReq=6E-Maschine/PWRaktivindenKalibriermodus(Strategiemusssicherstellen,dasskeinMomentbeiderEMangefordertwird.)";
CM_ SG_ 2463978674 EM2_OBD_Lampe_Anf "InallenVW-/Audi-FahrzeugenisteinMIL-Master-Konzeptumgesetzt.DazuermitteltjedesOBD-SteuergerätdeneigenenMIL-Status.EineMIL-AnsteuerungwirdvombetroffenenOBD-SteuergerätperMIL-RequestüberCANandenMIL-Masterweitergegeben.DerMIL-Mas";
CM_ SG_ 2463978674 EM2_Generator_Moment "ErforderlichesgeneratorischesMomentzurDarstellungderelektrischenWunschleistungbeidermomentanenMaschinendrehzahl";
CM_ SG_ 2463978674 EM2_PerfInd_Temperatur "ThermischerPerformance-IndikatorabhängigvonMaschinen-undLE-Temperatur";
CM_ SG_ 2463978674 EM2_MaxZul_Drehzahl "EM2_MaxZul_DrehzahlstelltdiemaximaleDrehzahlgrenzefürLEbzw.EMdardieimFreilaufzulässigist.FürDrehzahlengrößerdieserGrenzewirddieLEzumKomponentenschutzunabhängigvonderKommandierungindenAKSumschalten.";
CM_ SG_ 2463978674 EM2_Min_Moment_Gesamt "MinimalmöglichesMomentbeidermomentanenMaschinendrehzahlbezogenaufdievomSystemaufnehmbareelektrischeGesamtleistungMO_EM1_Min_Leistung_Gesamt,generatorischerBetrieb";
CM_ SG_ 2463978674 EM2_Fehlerlampe_Anf "AnforderungderrotenHybrid-WarnlampeimKombi";
CM_ SG_ 2463978674 EM2_Max_Moment_Gesamt "MaximalmöglichesMomentbeidermomentanenMaschinendrehzahlbezogenaufdieimSystemverfügbareelektrischeGesamtleistungMO_EM1_Max_Leistung_Gesamt,motorischerBetrieb";
CM_ SG_ 2463978674 EM2_Warnlampe_Anf "AnforderungdergelbenHybrid-WarnlampeimKombi";
CM_ SG_ 2463978674 EM2_Rekuperation "Rekuperation-EnergiederEMhinterachsintegriert";
CM_ SG_ 2463978674 EM2_Rekuperation_Ueberlauf "RekuperationleistungssignalEM2_Rekuperationmindest1xübergelaufen";
CM_ SG_ 2463978674 EM2_Verbrauch "Antriebs-EnergiederEM2hinterachsintegriert";
CM_ SG_ 2463978674 EM2_Verbrauch_Ueberlauf "Überlauf-BitfürdasSignalEM2_Verbrauch.
Rekuperationleistungssignal mindest 1x übergelaufen;";
CM_ SG_ 2463978674 EM2_Fehler_AE "AusgabeeinesFehlersinderFunktionaktiveEntladungimPWR";
CM_ SG_ 2463978674 EM2_Fehler_Leistungsred "EingeschränkteLeistungsfähigkeitaufGrundeinsinternenFehlers";
CM_ SG_ 2463978674 EM2_Fehler_ElAntriebFreilauf "Fehler:EMimFreilauf;LeistungselektronikfordertBegrenzungdermaximalenDrehzahlan,umÜberspannungimHV-Zwischenkreiszuvermeiden";
CM_ SG_ 2463978674 EM2_PWR_SollVolumenstrom "FürdieKühlungdesPWRaktuellmindestensbenötigterKühlwasservolumenstrom";
CM_ SG_ 2589283660 EM2_SollVorlauftemperatur "SolltemperaturdesKühlmittelsamVorlaufdesPWR";
CM_ SG_ 2589283660 EM2_Temperatur_EM "TemperaturderE-Maschine";
CM_ SG_ 2589283660 EM2_EM_SollVolumenstrom "FürdieKühlungderE-MaschineaktuellmindestensbenötigterKühlwasservolumenstrom


MQB/MEB: funktional 500ms (Cyclic) Zykluszeit notwendig

MLBevo: funktional 50ms (OnChange) Zykluszeit notwendig";
CM_ SG_ 2589283660 EM2_Max_MechLeistung_nom "MaximaleparametrierteLeistungdeselektrischenAntriebsbestehendausPWRundEM,interneBegrenzung";
CM_ SG_ 2589283660 EM2_Max_Moment_nom "MaximalesparametriertesMomentdeselektrischenAntriebsbestehendausPWRundEM,interneBegrenzung";
CM_ SG_ 2589283660 EM2_Temperatur_PWR "Momentanwert:TemperaturdesPWR";
CM_ SG_ 199 EM2_Freigabe_Info_WFS "WFS-Freigabeinformation

";
CM_ SG_ 199 EM2_Sperr_Info_WFS "WFS-Sperrinformation
";
CM_ SG_ 199 EM2_AR_aktiv "Ruckeldämpferaktiv";
CM_ SG_ 199 EM2_Eta_Sys "InstantaneousefficiencyofelectricaldriveEM2/MomentanerWirkungsgradelektrischerAntriebEM2";
CM_ SG_ 199 EM2_IstStrom "Momentanwert:StromüberPWR";
CM_ SG_ 199 EM2_Fehler_ElAntriebFreilauf_Anf "WirdgesetztumdenzwingendenBedarfeinerUmschaltungindenFreilaufanzuzeigen.VergleicheSignalEM1_MaxZul_Drehzahl.";
CM_ SG_ 199 EM2_Abregelung_Temperatur "LeistungsbegrenzungaufgrundÜbertemperaturderE-Maschine/desPWR";
CM_ SG_ 199 EM2_AnlernenElMotor_Anf "DiagnoseanforderungvonE-Maschine/PWR:Hybrid-ControllerschaltetüberMO_EM_Sollmodus=6bzw.MY3_EM_modeReq=6E-Maschine/PWRaktivindenKalibriermodus(Strategiemusssicherstellen,dasskeinMomentbeiderEMangefordertwird.)";
CM_ SG_ 199 EM2_Freigabe_Verfallsinfo_WFS "WFS";
CM_ SG_ 199 EM2_Parken_WFS_Status "StatusderLimitierung";
CM_ SG_ 199 EM2_HV_betriebsbereit "1:Ready_HV/1:HV-NetzSpannungimBetriebsbereich";
CM_ SG_ 2527679713 EM2_RtmWarnKommunikation "RealTimeMonitoringEM2buscommunicationfault";
CM_ SG_ 2527679713 EM2_RtmWarnUeberdrehzahl "RTMSignaloverspeedwarningEM2";
CM_ SG_ 2527679713 EM2_RtmWarnUeberstrom "RTMSignalover-currentwarningEM2";
CM_ SG_ 2527679713 EM2_RtmWarnTempEM "RTMSignalover-tempwarningEM2";
CM_ SG_ 2527679713 EM2_RtmWarnTempPWR "RTMSignalover-tempwarningEM2-PWR";
CM_ SG_ 2589283649 EML_02_CRC "FürMLB:
Berechnung siehe Lastenheft 'Kommunikationsabsicherung für FlexRay und CAN'
Ab MQB und MLBevo:
Berechnung siehe Lastenheft 'End-to-End Kommunikationsabsicherung'

Endwerte siehe Begleitdokument 'S-PDU Kennungsfolgen'";
CM_ SG_ 2589283649 EML_02_BZ "4bitBotschaftszähler,wirdmitjederSendebotschaftinkrementiert";
CM_ SG_ 2589283649 EML_ReifenKorrFaktorHL "KorrekturfaktorReifenumfangHintenLinks";
CM_ SG_ 2589283649 EML_ReifenKorrFaktorHR "KorrekturfaktorReifenumfangHintenRechts";
CM_ SG_ 2589283649 EML_ReifenKorrFaktorVL "KorrekturfaktorReifenumfangVorneLinks";
CM_ SG_ 2589283649 EML_ReifenKorrFaktorVR "KorrekturfaktorReifenumfangVorneRechts";
CM_ SG_ 2589283649 EML_Reifenumfang "MittlererReifenumfangdesEMLinMillimeter.BeiASIL-AnforderungenistdieFachabteilungzukontaktieren.";
CM_ SG_ 2589283649 EML_QBit_Reifenumfang "QBitdesmittlerenReifenumfangs.GesetztbeiErsatzwert,InitoderFehler.";
CM_ SG_ 608 EML_AnzeigeGeschw "BetragdesaktuellenGeschwindigkeitssignalsinFahrzeugbewegungsrichtungzurAnzeigenachEuroNCAP.BeiASIL-AnforderungenistdieFachabteilungzukontaktieren.";
CM_ SG_ 2589283751 KBI_Kilometerstand_HiRes_meter "HöchauflösenderesSignalalsKBI_Kilometerstand_HiResumUmrechnungzuvermindernundeinehöhereAuflösungals0,1kmzuerhalten.
Auflösung 1m / Bit
4 Byte länge (Doubleword)";
CM_ SG_ 2527679687 EPS_ASM_Ereignis "DiesesSignaldefiniert,welcheFunktionundwelcheArtvonAktivitätdasSendenderBotschaftandenAssistenzsystemmonitorASMveranlassthat.";
CM_ SG_ 2527679687 EPS_ASM_Zeitstempel "DiesesSignalermöglichtdiezeitlicheZuordnungdervonmehrerenFunktionenaufdemEPS-SGandenAssistenzsystemmonitorASMgesendetenStatusbotschaften.";
CM_ SG_ 2527679687 EPS_ASM_Data_1 "DieseSignalwirdvonmehrerenFunktionenaufdemEPS-SGgemäßderASM-DatendefinitionbefülltundandenAssistenzsystemmonitorASMgesendet";
CM_ SG_ 2527679687 EPS_ASM_Data_2 "DieseSignalwirdvonmehrerenFunktionenaufdemEPS-SGgemäßderASM-DatendefinitionbefülltundandenAssistenzsystemmonitorASMgesendet";
CM_ SG_ 2527679687 EPS_ASM_Data_3 "DieseSignalwirdvonmehrerenFunktionenaufdemEPS-SGgemäßderASM-DatendefinitionbefülltundandenAssistenzsystemmonitorASMgesendet";
CM_ SG_ 2527679687 EPS_ASM_Data_4 "DieseSignalwirdvonmehrerenFunktionenaufdemEPS-SGgemäßderASM-DatendefinitionbefülltundandenAssistenzsystemmonitorASMgesendet";
CM_ SG_ 2527679687 EPS_ASM_Data_5 "DieseSignalwirdvonmehrerenFunktionenaufdemEPS-SGgemäßderASM-DatendefinitionbefülltundandenAssistenzsystemmonitorASMgesendet";
CM_ SG_ 2527679687 EPS_ASM_Data_6 "DieseSignalwirdvonmehrerenFunktionenaufdemEPS-SGgemäßderASM-DatendefinitionbefülltundandenAssistenzsystemmonitorASMgesendet";
CM_ SG_ 258 ESC_50_CRC "FürMLB:
Berechnung siehe Lastenheft 'Kommunikationsabsicherung für FlexRay und CAN'
Ab MQB und MLBevo:
Berechnung siehe Lastenheft 'End-to-End Kommunikationsabsicherung'

Endwerte siehe Begleitdokument 'S-PDU Kennungsfolgen'";
CM_ SG_ 258 ESC_50_BZ "4bitBotschaftszähler,wirdmitjederSendebotschaftinkrementiert";
CM_ SG_ 258 ESP_QBit_Gierrate "QBitderGierrate.GesetztbeiErsatzwert,InitoderFehler.
";
CM_ SG_ 258 ESP_QBit_Laengsbeschl "QBitderLängsbeschleunigung.GesetztbeiErsatzwert,InitoderFehler.
";
CM_ SG_ 258 ESP_QBit_Querb "QBitderQuerbeschleunigung.GesetztbeiErsatzwert,InitoderFehler.";
CM_ SG_ 258 ESP_Querbeschleunigung "Beschleunigungswertiny-Achse

MLB: Gemessener Wert
0xFF = Fehler (wie bereits im Wertebereich spezifizert)
Bei ESP-Abschaltung durch modellgestützte Überwachung wird das Signal weiterhin ausgegeben.
Im AU64x und AU57x erfolgt die Bereitstellung der";
CM_ SG_ 258 ESP_Laengsbeschl "Beschleunigungswertinx-Achse

MLB: Im AU64x und AU57x erfolgt die Bereitstellung der Sensorwerte durch SARA-SG! Im AU64x und AU57x wird bei ESP-Abschaltung durch modellgestützte Überwachung das Signal weiterhin ausgegeben.

MQB: reines ABS schickt 0";
CM_ SG_ 258 ESC_Motorstartverzoegerung "MitdemSignal'Motorstartverzögerung'wirddenaktivenTeilnehmernermöglicht,einenMotorstartdurchdieStart-Stop-Funktionzuverzögern.";
CM_ SG_ 258 ESC_SeitenwindAssistent_Eingriff "MitdiesemStatusbitwirdeineaktiveRegelungdurchdenSeitenwindassistentensignalisiert.";
CM_ SG_ 258 ESP_Anschleppstart_Freigabe "BildeneinerSchleppstartfreigabeausFahrdynamiksicht.SchleppstartabbruchbeikritischerFahrzeugstabilität";
CM_ SG_ 258 ESC_Unterdruckmangel_erkannt "ESChateinenUnterdruckmangelimBremskraftverstärkerfestgestellt";
CM_ SG_ 258 ESP_Gierrate "Winkelgeschwindigkeitumdiez-Achse,ESP_VZ_Gierrate&ESP_QBit_Gierratebeachten!!!

MLB: gemessener Wert
tatsächliche Auflösung Bosch ESP: 0,27 Grad/s

Ab AU64x Auflösung wie die tatsächliche Skalierung 0,01. Im AU64x und AU57x wird bei ESP-Absch";
CM_ SG_ 258 ESP_VZ_Gierrate "VorzeichenderGierrate";
CM_ SG_ 258 ESP_Notbremsanzeige "ABS/ASRoderESPhatNotbremssituationerkannt.
Weiterführende Informationen im Lastenheft spezifiziert und in der entsprechenden Fachabteilung zu erfragen.

";
CM_ SG_ 258 ESP_SpannungsAnf "DieRekuperationkannmitderAnforderungeinerhöherenSpannungeingeschränktwerden.";
CM_ SG_ 258 ESP_PLA_Abbruch "WennderBremseingriffabgebrochenwurde,wirdindiesemSignalderGrunddesAbbruchsdargestellt.
Dies ist nur gültig, wenn der Status ESP_Status_ESP_PLA = '0xA' ist.";
CM_ SG_ 258 ESP_Status_ESP_PLA "ZustandderStatusmaschinederBremsefürdiekorrespondierendeStatusmaschineindemPLA-SG";
CM_ SG_ 258 ESP_QBit_Bremsdruck "QBitdesBremsdrucks.GesetztbeiErsatzwert,InitoderFehler.";
CM_ SG_ 258 ESP_QBit_Fahrer_bremst "GültigkeitderBremsdruckschwelleninformationdesSignalsESP_Fahrer_bremstvomESPSG
0x1 = Druckschwelleninformation kann noch nicht oder aufgrund eines Fehlers nicht ausgegeben werden
";
CM_ SG_ 258 ESP_Schwelle_Unterdruck "VerwendungimMQBfürHBV-ProjekteoderwennfürSt/SteinUnterdrucksensorverbautist";
CM_ SG_ 258 ESP_Bremsdruck "RohwertdesBremsdrucks
Für Fahrzeuge mit elektrischem Bremskraftverstärker gilt: Aus dem Signal ESP_Bremsdruck lässt sich kein Fahrerbremswunsch ableiten. Das Signal bildet lediglich den hydraulischen Anteil der Fahrzeugverzögerung ab. Der Rohwert des S";
CM_ SG_ 258 ESP_Fahrer_bremst "BitwirdgesetztbeimÜberschreitenderBremsdruckschwelle

Weiterführende Informationen im Lastenheft spezifiziert und in der entsprechenden Fachabteilung zu erfragen.
";
CM_ SG_ 258 ESP_Verz_TSK_aktiv "RückmeldeinformationandenTriebsstrangkoordinator/ACC,dassdieECD-Verzögerungsanforderungaktuellumgesetztwird";
CM_ SG_ 258 ESP_Lenkeingriff_ADS "ImFalleeinesfahrzeugstabilisierendenLenkeingriffsdesADS-SystemssollACC/GRAdeaktiviertwerden.

Im MQB wird dieses Signal nicht unterstützt!";
CM_ SG_ 258 ESP_Konsistenz_TSK "RückmeldungzumSendereinerVerzögerungsanforderung(Triebstrangskoordinator)bezüglichPrüfungderChecksumme,desBotschaftszählers,deslangenTimeoutundDLC.WirdauchgesetztbeiVerzögerungsanforderunggrößereinerapplizierbarenSchwelle.
";
CM_ SG_ 258 ESP_Bremsruck_AWV2 "DasSignaldientalsRückmeldungzumACC,dasseinangeforderterAWV2-Bremsruckdurchgeführtwird.DiepositiveRückmeldunglöstu.a.eineentsprechendeFahrerinformationimKombiinstrumentaus";
CM_ SG_ 258 ESP_Konsistenz_AWV2 "RückmeldungzumSendereinerAWV-Anforderung(ACC-Steuergerät)bezüglichPrüfungderChecksumme,desBotschaftszählers,deslangenTimeoutundDLC.
";
CM_ SG_ 258 ECD_Fehler "ESPkanndieVerzögerungsregelung/BremsenregelungaufgrundeinesinternenFehlersnichtausführen,mitFehlereintragimESP.
";
CM_ SG_ 258 ECD_nicht_verfuegbar "ESPkanndieVerzögerungsregelung/Bremsenregelungtemporärnichtausführen(z.B.Netzwerkmanagement-Betriebe-KL15Aus;v<18km/h;ESPinDiagnose,...),ohneFehlereintragimESP.

";
CM_ SG_ 258 ESP_Status_Bremsentemp "ECD-Bremsscheibentemperaturmodell.RückmeldungfürSendereinerECDVerzögerungsanforderung,ohneFehlereintragimESP";
CM_ SG_ 258 ESP_Autohold_Standby "RückmeldunganEPB,dassderFahrerdieFunktionAutoholdmindestenseinmalangeforderthat.ImFalleinesESP-AusfallesodereinerÜbernahmeaufforderungerfolgtdieEPB-ZuschaltungnurnachSetzendiesesBits.BitwirdgesetztnachBetätigungdesAutohol";
CM_ SG_ 258 ESP_HDC_Standby "Verwendung/BedienungimMQBundAU57xAllroad:
Flag wird vom ESP gesetzt, wenn über den HDC-Taster die HDC-Funktion eingeschalten wurde";
CM_ SG_ 258 ESP_HBA_aktiv "Verwendung/BedienungabD4
Signal gibt an, ob der hydraulische Bremsassistent im Regler aktiviert wurde

Im MQB wird das Signal nicht unterstützt!

";
CM_ SG_ 258 ESP_Prefill_ausgeloest "MLB:Verwendung/BedienungabD4
zeigt, ob die Funktion Prefill (aufgrund Fahrpedalgradient) ausgelöst wird; zeigt keinen Funktionszustand bezüglich Fehlerstilllegung

MQB: Wird gesetzt bei jeder Art von aktivem Prefill";
CM_ SG_ 258 ESP_Rueckwaertsfahrt_erkannt "nurbeiAU57xundAU416sowieAudiB8PA
Info, ob Rückwärtsfahrt über internen Algorithmus sicher erkannt

Im MQB wird das Signal nicht unterstützt!";
CM_ SG_ 258 ESP_Status_Anfahrhilfe "FunktionsstatusdesBerganfahrassistenten
MQB: Auswertung im Getriebe zwecks Standabkopplung";
CM_ SG_ 258 ESP_HDC_aktiv "MQBundAU57xAllroad:MitdiesemStatusbitwirdeinegeradeaktiveRegelungdesBergabfahrassistenten(HillDescentControl)signalisiert.";
CM_ SG_ 258 ESP_StartStopp_Info "Stopp-FreigabeundStart-AnforderungandenStart-Stopp-Koordinator";
CM_ SG_ 258 ESP_Eingr_HL "wirdvonQSPundNeigungsanzeigeverwendet

Flag wird vom ESP gesetzt, sobald aufgrund eines ESP-Eingriffs am Rad aktiv Druck aufgebaut wird.
Frühestens mit öffnen des Ventils und spätestens bei einem Bremsmoment von 100Nm. Flag bleibt solange gesetzt ";
CM_ SG_ 258 ESP_Eingr_HR "wirdvonQSPundNeigungsanzeigeverwendet

Flag wird vom ESP gesetzt, sobald aufgrund eines ESP-Eingriffs am Rad aktiv Druck aufgebaut wird.
Frühestens mit öffnen des Ventils und spätestens bei einem Bremsmoment von 100Nm. Flag bleibt solange gesetzt ";
CM_ SG_ 258 ESP_Eingr_VL "wirdvonQSPundNeigungsanzeigeverwendet

Flag wird vom ESP gesetzt, sobald aufgrund eines ESP-Eingriffs am Rad aktiv Druck aufgebaut wird.
Frühestens mit öffnen des Ventils und spätestens bei einem Bremsmoment von 100Nm. Flag bleibt solange gesetzt ";
CM_ SG_ 258 ESP_Eingr_VR "wirdvonQSPundNeigungsanzeigeverwendet

Flag wird vom ESP gesetzt, sobald aufgrund eines ESP-Eingriffs am Rad aktiv Druck aufgebaut wird.
Frühestens mit öffnen des Ventils und spätestens bei einem Bremsmoment von 100Nm. Flag bleibt solange gesetzt ";
CM_ SG_ 258 ESP_BKV_Unterdruck "DermaximaleWertwirdauf1012mbarbegrenzt.
Dieses Signal wird im AU64x nicht unterstützt.

Hinweis: Auch bei nicht verbautem BKV-Unterdrucksensor könnte während der Initialisierung der Initialisierungswert gesendet werden.";
CM_ SG_ 258 ESP_Autohold_aktiv "RückmeldunganEPB,dassAutoholdaktivist.";
CM_ SG_ 258 ESP_FStatus_Anfahrhilfe "BeigesetztemBitstehtdieFunktionBerganfahrassistent(Hillhold)nichtzurVerfügung";
CM_ SG_ 258 ESP_Verz_EPB_aktiv "BeigesetztemBitwirddieVerzögerungsanforderungvonEPBumgesetzt.";
CM_ SG_ 258 ECD_Bremslicht "BremslichtansteuerungdurchECD-Funktion";
CM_ SG_ 258 ESP_Verzoeg_EPB_verf "BeigesetztemBitistderVerzögerungsregelerfürEPBverfügbar.";
CM_ SG_ 258 ESP_Status_Bremsdruck "MLB:BeigesetztemBitliegtp>ca.2baran,hervorgerufendurchFahrer,ASR,FZR,ECD,Bremsregler...beiAbfalldesBitsistp<Xbar,beiaktivemECD-EingriffEndedesEingriffs

Weiterführende Informationen im Lastenheft spezifiziert und in der";
CM_ SG_ 258 ESP_Anforderung_EPB "ESPfordertvonderEPBÖffnenbzw.Schliessenan.NotwendigwegenAutohold-Funktion.";
CM_ SG_ 258 ESP_ANB_CM_Rueckk_Umsetz "DasSignaldientalsRückmeldungzumACC,dasseineangeforderteANB-CMdurchgeführtwird.DiepositiveRückmeldunglöstu.a.eineentsprechendeFahrerinformationimKombiinstrumentaus";
CM_ SG_ 258 ESP_Konsistenz_ACC_Botschaft "RückmeldungzumSenderderVerzögerungsanforderungACCbezüglichPrüfungCHK/CRC,BZundlangerTimeout.WirdauchgesetztbeieinerVerzögerungsanforderunggrößeralseineapplizierbareSchwelle.

Im D4/C7: Botschaft ACC_05
Im MQB: Botschaft ACC_07";
CM_ SG_ 258 ESP_Stillstandsphase_erschoepft "RückmeldungvomESP,dasseineangefordertessicheresHaltenimStillstandnichtmehrlängermöglichist.";
CM_ SG_ 258 ESP_ZT_Rueckk_Umsetz "DasSignaldientalsRückmeldungzumACC,dasseineangeforderteZielbremsung/Teilbremsungdurchgeführtwird.DiepositiveRückmeldunglöstu.a.eineentsprechendeFahrerinformationimKombiinstrumentaus";
CM_ SG_ 258 ESP_Tuerkontakt_Fahrertuer "LogischerPegelderHW-LeitungzumTürkontaktschalterimESP-SG.
0 > Schalter geschlossen
1 > Schalter offen

Ungefilterter und unplausibilisierter Status der HW-Leitung vom Fahrertür-Türkontaktschalter zum ESP.
Redundanz für Systemsicherheit notwend";
CM_ SG_ 258 ESP_Abrutschen_Stillstand "DasESPteiltüberdiesesBitmit,dasseinAbrutschenimStillstanderkanntwurde.

Im MQB wird das Signal nicht unterstützt!";
CM_ SG_ 258 ESP_Fahrer_tritt_ZBR_Schw "RückmeldungdesESPanAWV,obderFahrerdieaktuellgültigeZBR-Schwelleübertritt";
CM_ SG_ 258 ESP_QBit_v_ref "QBitderReferenzgeschwindigkeitESP_v_ref.GesetztbeiErsatzwert,InitoderFehler.
Detailinformationen zu dem Signal sind dem Lastenheft 'Signalexport - Funktionale Anforderungen an ESP' zu entnehmen - Signal ESP_St_v_fzg_ref";
CM_ SG_ 258 ESP_v_ref_Fahrtrichtung "SignalstelltdieInformationenüberdieFahrtrichtungdesFahrzeugesdar.SiewirdalsVorzeichenderReferenzgeschwindigkeitESP_v_refinterpretiertundbasiertaufdenDrehrichtungenderRäder.
Detailinformationen zu dem Signal sind dem Lastenheft 'Si";
CM_ SG_ 258 ESC_Bremsdruckgradient "DasSignalzeigtdenvomFahrergedrucktenBremsdruckgradienten";
CM_ SG_ 258 ESP_v_ref "MLBevo:
Signal wird nur von einem BOSCH ESP System zur Verfügung gestellt. Exklusives Signal vom BOSCH ESP zum BOSCH Airbag für ROSEII Funktion und für Fahrwerkregelsysteme.
Verwendung nur nach vorheriger Abstimmung mit den verantwortlichen EF Fachbere";
CM_ SG_ 258 ESC_Hydr_Fkt_aktiv "InfoüberdieAktivitätvonDruckaufbaufunktionenimESCundUebermittlungdesWarnlevelanEBKV.";
CM_ SG_ 258 ESC_QBit_Fahrerbremswunsch "GesetztbeiErsatzwert,InitoderFehler.";
CM_ SG_ 258 ESC_Fahrerbremswunsch "PHEV:BerechneterDruckanhanddeseBKV-AusgangsstangenwegssowieESP-pMC.Rekunichtaktiv-->vergleichbarmitESP_Bremsdruck;Rekuaktiv-->virtuellerBremsdruck
Konv.: entspricht ESP_Bremsdruck";
CM_ SG_ 258 ESCGeneratorSollMoment "InMLBevoFaktorinTS_Faktor_Radmomentebeachten!

Verzögernd wirkender Antriebsstrangsollmomentenanteil aus Bremspedalbetätigung auf Summenradebene.";
CM_ SG_ 258 ESC_Raddruck_max "StelltdenzahlenmäßighöchstenDruckwertderviermodelliertenRaddrückedar.";
CM_ SG_ 258 EPB_Freig_Verzoeg_Anf "Verzögerungsanforderung	";
CM_ SG_ 258 EPB_Verzoeg_Anf "SteuerungsanforderunganandereSysteme(z.B.ESP),umwährendderFahrt,durchdenHandbremsschalterausgelöst,zubremsen(ECD-Funktion)";
CM_ SG_ 258 EPB_Pedalweg_Kuppl "SignalentsprichtTastverhältnisdesPWM.GesamtwegKupplungspedal10%bis90%,damitzuerwartendeWerte25bis225.25beiKupplungspedalnichtgetreten,225beiKupplungspedalvolldurchgetreten.
2% Toleranz wird im Wertebereich ermöglicht (8%-92%).
";
CM_ SG_ 258 EPB_DAA_Randbed_erf "DieRandbedingungenzumautomatischenÖffnenderEPB(FunktionDAA)sinderfülltundeinBetätigendesFahrpedalsführtzumÖffnenderEPB.";
CM_ SG_ 258 EPB_Fehlerstatus_02 "AnpassungderTexteandieaktuellenZuständefürweitergehendeFunktionen(Stillstandsmanager)";
CM_ SG_ 258 EPB_Schalterposition "SpiegeltdieSchalterstellungwieder.

0x3 = Schalterfehler ";
CM_ SG_ 258 EPB_Spannkraft "ErzeugteSpannkraft.BeziehtsichaufdieAktuatoren.

MQB: Spannkraftwerte entsprechen nicht den tatsächlichen Spannkräften. Genauere Informationen bitte in der Fachabteilung erfragen! ";
CM_ SG_ 258 EPB_Status_02 "ErweiterungderZuständeumeingenaueresBilddesaktuellenZustandeszuerhaltenfürweitergehendeFunktionen(Stillstandsmanager)
";
CM_ SG_ 258 EPB_Status "GibtdenZustandderEPB-Aktuatorenan.

Nur VW526/PAG E2: Wert 0x3 bedeutet 'unbekannt'

";
CM_ SG_ 258 ESP_Status_Bremsentemp_02 "Bremsscheibentemperaturmodell.RückmeldungfürSendereinerVerzögerungsanforderung";
CM_ SG_ 252 ESC_51_CRC "FürMLB:
Berechnung siehe Lastenheft 'Kommunikationsabsicherung für FlexRay und CAN'
Ab MQB und MLBevo:
Berechnung siehe Lastenheft 'End-to-End Kommunikationsabsicherung'

Endwerte siehe Begleitdokument 'S-PDU Kennungsfolgen'";
CM_ SG_ 252 ESC_51_BZ "4bitBotschaftszähler,wirdmitjederSendebotschaftinkrementiert";
CM_ SG_ 252 ESC_aktBr_Modus "KontextdesSignalsESC_aktBr_Volumenstrom:
0: AktivBremsung per eBKV nicht aktiv
1: aktiver Druckaufbau per ESP-Pumpe: eBKV muss Volumen über HZ nachführen
2: Aktivbremsung per eBKV aktiv
3: eBKV bei Aktivbremsung im Runout: ESP-Pumpe muss zusätzlich";
CM_ SG_ 252 ESC_Blending_Solldruck "ZieldruckwährendRekuperation.DasSignalistspezifischaufbereitetundwirdfürdiePedakraftkompensationimeBKVgenutzt.

MQB/MQB2020: Wird nur von einem blendfähigen ESC unterstützt, wie es in mHEV und pHEV Fahrzeugen eingesetzt wird.";
CM_ SG_ 252 ESC_aktBr_Volumenstrom "VolumenstromvorgabefürAktivbremsungpereBKV,
Kontext des Volumenstroms wird im Signal ESC_aktBr_Modus übertragen";
CM_ SG_ 252 ESC_EBKV_Kraftblending_Modus "FreigabederPedalkraftkompensation(FunktiondeseBKV)

MQB/MQB2020: Wird nur von einem blendfähigen ESC unterstützt, wie es in mHEV und pHEV Fahrzeugen eingesetzt wird.";
CM_ SG_ 252 ESC_Bremsdruck_Modell "Virtueller,ausdemWert'EBKV_Stangenweg_Fahrerwunsch'berechneterHauptzylinderdruck.WährendeinerhydraulischenBremsungentsprichtdieserDrucknahezudem'ESC_Bremsdruck_02'.WährendeinerBremsungmitRekuperationisteseinberechneterWert,derd";
CM_ SG_ 252 ESC_Bremsdruck_02 "RohwertdesBremsdrucks
Für Fahrzeuge mit elektrischem Bremskraftverstärker gilt: Aus dem Signal ESC_Bremsdruck_02 lässt sich kein Fahrerbremswunsch ableiten. Das Signal bildet lediglich den hydraulischen Anteil der Fahrzeugverzögerung ab. Der Rohwert de";
CM_ SG_ 252 ESC_QBit_Bremsdruck_02 "QBitdesESC_Bremsdruck_02.GesetztbeiErsatzwert,InitoderFehler.";
CM_ SG_ 252 ESP_HL_Radgeschw_02 "Radgeschwindigkeithintenlinks";
CM_ SG_ 252 ESP_HR_Radgeschw_02 "Radgeschwindigkeithintenrechts";
CM_ SG_ 252 ESP_VL_Radgeschw_02 "Radgeschwindigkeitvornelinks";
CM_ SG_ 252 ESP_VR_Radgeschw_02 "Radgeschwindigkeitvornerechts";
CM_ SG_ 252 ESP_FZR_uebersteuern "Fahrzeugerkenntuebersteuern";
CM_ SG_ 252 ESP_FZR_untersteuern "Fahrzeugerkenntuntersteuern";
CM_ SG_ 252 ESC_Anf_Mindestreku "BeiWert==1solldurchdenAntriebeineimProjektdefinierteMindestrekuperationsleistungdesE-AntriebszurAnforderungdurchdasBremssystemschnellstmöglichfreigegebenwerden.DiesdientzurEntlastungderReibbremse.";
CM_ SG_ 252 ESC_GMV_aktiv "RueckmeldungGiermomentvorgabeaktiv";
CM_ SG_ 252 ESC_GMV_nicht_verfuegbar "RueckmeldungGiermomentvorgabenichtverfuegbar";
CM_ SG_ 252 ESC_Status_vRef_Stuetzeingriff "DasSignalqualifizierteineMomentenreduzierunganderHinterachsezurStützungderESCReferenzgeschwindigkeit.DieReduzierungerfolgtüberdieSignaleESC_MomRad_EingriffbzwESC_MomRad_Eingriff_sek";
CM_ SG_ 252 FDR_Allradverteilung_aktiv "AllradumverteilungausFDRaktivundvomMSGumzusetzen";
CM_ SG_ 252 FDR_Anf_Allradbetrieb "AnforderungdesFahrdynamikreglersanMSGzurAktivierungdesAllradbetriebs.";
CM_ SG_ 252 ESP_HL_Bremsmoment "BremsmomentHL
Ausgabe nach LAH: Ausgabe der internen Radbremsmomente / Radbremsdrücke / durch das ESP";
CM_ SG_ 252 ESP_HR_Bremsmoment "BremsmomentHR
Ausgabe nach LAH: Ausgabe der internen Radbremsmomente / Radbremsdrücke / durch das ESP";
CM_ SG_ 252 ESP_VR_Bremsmoment "BremsmomentVR
Ausgabe nach LAH: Ausgabe der internen Radbremsmomente / Radbremsdrücke / durch das ESP";
CM_ SG_ 252 ESP_VL_Bremsmoment "BremsmomentVL
Ausgabe nach LAH: Ausgabe der internen Radbremsmomente / Radbremsdrücke / durch das ESP";
CM_ SG_ 252 ESP_FDR_uebersteuern "ModularerFahrdynamikreglererkenntÜbersteuern.
Bei Integration modularer Fahrdynamikregler in ESC MEB: Verwendung durch eAllradfunktion in MSG.";
CM_ SG_ 252 ESP_FDR_untersteuern "ModularerFahrdynamikreglererkenntUntersteuern.
Bei Integration modularer Fahrdynamikregler in ESC MEB: Verwendung durch eAllradfunktion in MSG.";
CM_ SG_ 252 TSMomBegrenzung "InMLBevoFaktorinTS_Faktor_Radmomentebeachten!

Begrenzung des verzögernd wirkenden Antriebsstrangsollmomentenanteil auf Summenradebene";
CM_ SG_ 252 ESC_Allrad_Anteil_max_sek "MaximalerprozentualerAnteildersekundärenAntriebsachseamGesamtmoment-wirdsoweitdiesdurchdieLeistungsfähigkeitderAchsemöglichisteingehalten";
CM_ SG_ 252 ESC_Allrad_Anteil_min_sek "MinimalerprozentualerAnteildersekundärenAntriebsachseamGesamtmoment-wirdsoweitdiesdurchdieLeistungsfähigkeitderAchsemöglichisteingehalten";
CM_ SG_ 252 ESC_Status_Eingriff "DasSignalqualifiziert„ESC_MomRad_Eingriff“undgibtan,wiediesesSignalumzusetzenist";
CM_ SG_ 252 ESC_Status_Eingriff_sek "DasSignalqualifiziert„ESC_MomRad_Eingriff_sek“undgibtan,wiediesesSignalumzusetzenist";
CM_ SG_ 252 ESC_MomRad_Eingriff "Eingriffs-Momenten-AnforderungvomESCandasASGfürdieprimäreAchse;aufBezugsebene„MomentamRad;FaktorinTS_Faktor_Radmomentebeachten!";
CM_ SG_ 252 ESC_MomRad_Eingriff_sek "Eingriffs-Momenten-AnforderungvomESCandasASGfürdiesekundäreAchse;aufBezugsebene„MomentamRad;FaktorinTS_Faktor_Radmomentebeachten!SignalistnurrelevantfürmechanischgetrennteAchsantriebe(z.B.equattro)";
CM_ SG_ 252 ESC_Achsdrehzahl_Max "LimitAchsdrehzahlfürdiePrimärachse";
CM_ SG_ 252 ESC_Achsdrehzahl_Min "LimitAchsdrehzahlfürdiePrimärachse";
CM_ SG_ 252 ESC_Achsdrehzahl_Max_sek "LimitAchsdrehzahlfürdieSekundärachse";
CM_ SG_ 252 ESC_Achsdrehzahl_Min_sek "LimitAchsdrehzahlfürdieSekundärachse";
CM_ SG_ 2463978647 ESP_ACC_LDE "Verwendung/BedienungabFolgeprojekteD4,abernichtimD4selbst
Lebensdauerende für ACC-Bremsung erreicht";
CM_ SG_ 2463978647 ESP_Allrad_Antrieb "ImMQBwirddasSignalnichtunterstützt!";
CM_ SG_ 2463978647 ESP_Codierung_ADS "ESPgibtfürEmpfängerimFahrzeugaus,obADSverbaut/nichtverbautist.

Im MQB wird das Signal nicht unterstützt!
";
CM_ SG_ 2463978647 ESP_RTA_HL "PhysikalischerWertebereich+/-5%.DerReifentoleranzabgleichbeziehtsichaufdaslinkeVorderrad.

physikalischer Wert = ( (Hex-Wert - 0x7F) / 2048 )*100%

Im MQB wird das Signal nicht unterstützt!";
CM_ SG_ 2463978647 ESP_RTA_HR "PhysikalischerWertebereich+/-5%.DerReifentoleranzabgleichbeziehtsichaufdaslinkeVorderrad.

physikalischer Wert = ( (Hex-Wert - 0x7F) / 2048 )*100%

Im MQB wird das Signal nicht unterstützt!";
CM_ SG_ 2463978647 ESP_RTA_VR "PhysikalischerWertebereich+/-5%.DerReifentoleranzabgleichbeziehtsichaufdaslinkeVorderrad.

physikalischer Wert = ( (Hex-Wert - 0x7F) / 2048 )*100%

Im MQB wird das Signal nicht unterstützt!";
CM_ SG_ 2463978647 OBD_Fehler_Radsensor_HL "FürMotor-SG(gesetzlicheVorgabe)";
CM_ SG_ 2463978647 OBD_Fehler_Radsensor_HR "FürMotor-SG(gesetzlicheVorgabe)";
CM_ SG_ 2463978647 OBD_Fehler_Radsensor_VL "FürMotor-SG(gesetzlicheVorgabe)";
CM_ SG_ 2463978647 OBD_Fehler_Radsensor_VR "FürMotor-SG(gesetzlicheVorgabe)";
CM_ SG_ 2463978647 ESP_Qualifizierung_Antriebsart "SignalforBentleyBY83x:ESP_wheel_drive_selector

Bit qualifiziert für neue Projekte (ab D4 ff.) das Signal 'ESP_Quattro_Antrieb', d.h. ist 'ESP_Qualifizierung_Antriebsart'
auf 0x1 gesetzt, ändert sich die bisherige Bedeutung des Signals 'ESP_Quattro";
CM_ SG_ 2463978647 ESP_Offroad_Modus "NurVW526:BeiOffroad-FahrzeugenkannübereinenSchaltereinOffroadmodusgewähltwerden,dieserwirdhierangezeigt.BeiOffroadPlus-FahrzeugenwirdhierderOffroadmodusindirektdurchdasVerteilergetriebevorgegeben(ALR_Offroad=1)undeingespie";
CM_ SG_ 2463978647 ESP_MKB_ausloesbar "ESPhatFunktionMulti-Kollisions-Bremsungfreigeschaltet";
CM_ SG_ 2463978647 ESP_Stat_FallBack_eBKV "DasSignalzeigtdemeBKVan,obseineRückfallebeneimESPverfügbarist.";
CM_ SG_ 2463978647 ESP_CM_Variante "SignalgibtanwelcheCM-Varianteunterstuetztwird.
";
CM_ SG_ 2463978647 ESP_OBD_Status "DiesesBitsteuertdieMIL-Lampean(MotorsteuergerätreichtdieseInfoanKombiweiter).";
CM_ SG_ 2463978647 ESP_Rollenmodus_Deaktivieren "ZwangzumAbbruchdesRollenmodusmitanschließenderESP-Vollfunktion.
MQB: Zwang zum Abbruch des Rollenmodus in allen Funktionsteilnehmern (Empfänger) mit anschließender ESP-Vollfunktion (Sender).
Signal wird vom ESP dauerhaft mit gültigen Werten bedat";
CM_ SG_ 2463978647 ESP_nachtr_Stopp_Anf "DiesesSignaldientdemMotoralsTrigger,dasseinnachträglicherMotorstoppeingeleitetwerdenkann,wennesdieBedingungendesStStKoordinatorsdieszulassen.";
CM_ SG_ 2527679683 ESC_ASM_Ereignis "DiesesSignaldefiniert,welcheFunktionundwelcheArtvonAktivitätdasSendenderBotschaftandenAssistenzsystemmonitorASMveranlassthat.";
CM_ SG_ 2527679683 ESC_ASM_Zeitstempel "DiesesSignalermöglichtdiezeitlicheZuordnungdervonmehrerenFunktionenaufdemESC-SGandenAssistenzsystemmonitorASMgesendetenStatusbotschaften";
CM_ SG_ 2527679683 ESC_ASM_Data_1 "DieseSignalwirdvonmehrerenFunktionenaufdemESC-SGgemäßderASM-DatendefinitionbefülltundandenAssistenzsystemmonitorASMgesendet";
CM_ SG_ 2527679683 ESC_ASM_Data_2 "DieseSignalwirdvonmehrerenFunktionenaufdemESC-SGgemäßderASM-DatendefinitionbefülltundandenAssistenzsystemmonitorASMgesendet";
CM_ SG_ 2527679683 ESC_ASM_Data_3 "DieseSignalwirdvonmehrerenFunktionenaufdemESC-SGgemäßderASM-DatendefinitionbefülltundandenAssistenzsystemmonitorASMgesendet";
CM_ SG_ 2527679683 ESC_ASM_Data_4 "DieseSignalwirdvonmehrerenFunktionenaufdemESC-SGgemäßderASM-DatendefinitionbefülltundandenAssistenzsystemmonitorASMgesendet";
CM_ SG_ 2527679683 ESC_ASM_Data_5 "DieseSignalwirdvonmehrerenFunktionenaufdemESC-SGgemäßderASM-DatendefinitionbefülltundandenAssistenzsystemmonitorASMgesendet";
CM_ SG_ 2527679683 ESC_ASM_Data_6 "DieseSignalwirdvonmehrerenFunktionenaufdemESC-SGgemäßderASM-DatendefinitionbefülltundandenAssistenzsystemmonitorASMgesendet";
CM_ SG_ 278 ESP_10_CRC "FürMLB:
'Berechnung siehe Lastenheft 'Kommunikationsabsicherung für FlexRay und CAN''

Ab MQB und MLBevo:
'Berechnung siehe Lastenheft 'End-to-End Kommunikationsabsicherung''

Endwerte siehe Begleitdokument 'S-PDU Kennungsfolgen'

Wird im Projekt";
CM_ SG_ 278 ESP_10_BZ "Botschaftszähler

Wird im Projekt D4 und D4Hybrid nicht verwendet!  Wird im D4 PA verwendet";
CM_ SG_ 278 ESP_QBit_Wegimpuls_VL "QualifizierungsbitWegimpulszählerVL

Wird im Projekt D4 und D4Hybrid nicht verwendet!  Wird im D4 PA verwendet";
CM_ SG_ 278 ESP_QBit_Wegimpuls_VR "QualifizierungsbitWegimpulszählerVR

Wird im Projekt D4 und D4Hybrid nicht verwendet!  Wird im D4 PA verwendet";
CM_ SG_ 278 ESP_QBit_Wegimpuls_HL "QualifizierungsbitWegimpulszählerHL

Wird im Projekt D4 und D4Hybrid nicht verwendet!  Wird im D4 PA verwendet";
CM_ SG_ 278 ESP_QBit_Wegimpuls_HR "QualifizierungsbitWegimpulszählerHR

Wird im Projekt D4 und D4Hybrid nicht verwendet!  Wird im D4 PA verwendet";
CM_ SG_ 278 ESP_Wegimpuls_VL "WegimpulszählerVL.
Anzahl der Wegimpulse Vorderrad links (steigende und fallende Flanke)
Zähler läuft grundsätzlich vorwärts, auch bei Rückwärtsfahrt.
Nach SG-Reset ist immer, ohne Ausnahme, 1mal der Init Wert 1021 zu senden.

Wird im Projekt D4 und";
CM_ SG_ 278 ESP_Wegimpuls_VR "WegimpulszählerVR.
Anzahl der Wegimpulse Vorderrad rechts (steigende und fallende Flanke)
Zähler läuft grundsätzlich vorwärts, auch bei Rückwärtsfahrt.
Nach SG-Reset ist immer, ohne Ausnahme, 1mal der Init Wert 1021 zu senden.

Wird im Projekt D4 un";
CM_ SG_ 278 ESP_Wegimpuls_HL "WegimpulszählerHL.
Anzahl der Wegimpulse Hinterrad links (steigende und fallende Flanke)
Zähler läuft grundsätzlich vorwärts, auch bei Rückwärtsfahrt.
Nach SG-Reset ist immer, ohne Ausnahme, 1mal der Init Wert 1021 zu senden.

Wird im Projekt D4 und";
CM_ SG_ 278 ESP_Wegimpuls_HR "WegimpulszählerHR.
Anzahl der Wegimpulse Hinterrad rechts (steigende und fallende Flanke)
Zähler läuft grundsätzlich vorwärts, auch bei Rückwärtsfahrt.
Nach SG-Reset ist immer, ohne Ausnahme, 1mal der Init Wert 1021 zu senden.

Wird im Projekt D4 un";
CM_ SG_ 278 ESP_VL_Fahrtrichtung "DrehrichtungRadVL

Weiterführende Informationen im Lastenheft spezifiziert und in der entsprechenden Fachabteilung zu erfragen.

Wird im Projekt D4 und D4Hybrid nicht verwendet!  Wird im D4 PA verwendet";
CM_ SG_ 278 ESP_VR_Fahrtrichtung "DrehrichtungRadVR

Weiterführende Informationen im Lastenheft spezifiziert und in der entsprechenden Fachabteilung zu erfragen.

Wird im Projekt D4 und D4Hybrid nicht verwendet!  Wird im D4 PA verwendet";
CM_ SG_ 278 ESP_HL_Fahrtrichtung "DrehrichtungRadHL

Weiterführende Informationen im Lastenheft spezifiziert und in der entsprechenden Fachabteilung zu erfragen.

Wird im Projekt D4 und D4Hybrid nicht verwendet!  Wird im D4 PA verwendet";
CM_ SG_ 278 ESP_HR_Fahrtrichtung "DrehrichtungRadHR

Weiterführende Informationen im Lastenheft spezifiziert und in der entsprechenden Fachabteilung zu erfragen.

Wird im Projekt D4 und D4Hybrid nicht verwendet!  Wird im D4 PA verwendet";
CM_ SG_ 1629 ESP_20_CRC "FürMLB:
'Berechnung siehe Lastenheft 'Kommunikationsabsicherung für FlexRay und CAN''

Ab MQB und MLBevo:
'Berechnung siehe Lastenheft 'End-to-End Kommunikationsabsicherung''

Endwerte siehe Begleitdokument 'S-PDU Kennungsfolgen'";
CM_ SG_ 1629 BR_Systemart "IdentifikationdesverbautenBremssystems

Dient dem Kombi zur Plausibilisierung";
CM_ SG_ 1629 ESP_SpannungsAnf_02 "ForderungdesESP-SG'szurSpannungsanhebung.";
CM_ SG_ 1629 ESP_Zaehnezahl "KonstanterWertderZähnezahldesverwendetenImpulsradeswirdausgegeben,jederEmpfängerderWegimpulsemussdieZähnezahleinlesen,umeinevolleUmdrehungdesRadeszuerkennen.

Weiterführende Informationen im Lastenheft spezifiziert und in der en";
CM_ SG_ 1629 ESP_Charisma_FahrPr "MLBevo:AktuellesFahrprogrammdesCharisma-Teilnehmers(sieheSystemlastenheftDriveSelect)
MQB: Istwert der Kennlinie (siehe Systemlastenheft MQB FPA)";
CM_ SG_ 1629 ESP_Charisma_Status "SystemstatusdesCharismateilnehmers

Wert 0x3 ist nur für Fahrzeuge ab MQB relevant";
CM_ SG_ 1629 ESP_Wiederstart_Anz_01 "DiesesSignalgibtdiedetaillierteBegründungfüreinenWiederstartvomBremsensteuergerätan.";
CM_ SG_ 1629 ESP_Wiederstart_Anz_02 "DiesesSignalgibtdiedetaillierteBegründungfüreinenWiederstartvomBremsensteuergerätan.";
CM_ SG_ 1629 ESP_Wiederstart_Anz_03 "DiesesSignalgibtdiedetaillierteBegründungfüreinenWiederstartvomBremsensteuergerätan.";
CM_ SG_ 1629 ESP_Wiederstart_Anz_04 "DiesesSignalgibtdiedetaillierteBegründungfüreinenWiederstartvomBremsensteuergerätan.";
CM_ SG_ 1629 ESP_Stoppverbot_Anz_01 "DiesesSignalgibtdiedetaillierteBegründungfüreinStoppverbotvomBremsensteuergerätan.";
CM_ SG_ 1629 ESP_Stoppverbot_Anz_02 "DiesesSignalgibtdiedetaillierteBegründungfüreinStoppverbotvomBremsensteuergerätan.";
CM_ SG_ 1629 ESP_Stoppverbot_Anz_03 "DiesesSignalgibtdiedetaillierteBegründungfüreinStoppverbotvomBremsensteuergerätan.";
CM_ SG_ 1629 ESP_Stoppverbot_Anz_04 "DiesesSignalgibtdiedetaillierteBegründungfüreinStoppverbotvomBremsensteuergerätan.";
CM_ SG_ 1629 ESP_Stoppverbot_Anz_05 "DiesesSignalgibtdiedetaillierteBegründungfüreinStoppverbotvomBremsensteuergerätan.";
CM_ SG_ 1629 ESP_Stoppverbot_Anz_06 "DiesesSignalgibtdiedetaillierteBegründungfüreinStoppverbotvomBremsensteuergerätan.";
CM_ SG_ 1629 ESP_Stoppverbot_Anz_07 "DiesesSignalgibtdiedetaillierteBegründungfüreinStoppverbotvomBremsensteuergerätan.";
CM_ SG_ 1629 ESP_Stoppverbot_Anz_Std "DiesesSignalgibtdiedetaillierteBegründungfüreinStoppverbotvomBremsensteuergerätan.";
CM_ SG_ 1629 ESP_Dachrelingsensor "ErkennungaufVerbaudesDachrelingsensorsundDachquerträger.";
CM_ SG_ 1629 ESP_Stoppverbot_Anz_08 "DiesesSignalgibtdiedetaillierteBegründungfüreinStoppverbotvomBremsensteuergerätan.";
CM_ SG_ 1629 HDC_Charisma_FahrPr "MLBevo:AktuellesFahrprogrammdesCharisma-Teilnehmers(sieheSystemlastenheftDriveSelect)
MQB: Istwert der Kennlinie (siehe Systemlastenheft MQB FPA)";
CM_ SG_ 1629 HDC_Charisma_Status "SystemstatusdesCharismateilnehmers

Wert 0x3 ist nur für Fahrzeuge ab MQB relevant";
CM_ SG_ 1629 BR_QBit_Reifenumfang "GesetztbeiErsatzwert,InitoderFehler.";
CM_ SG_ 1629 BR_Reifenumfang "MittlererRadumfanggerechnetinMillimeter.
Von der Bremse plausibilisierter Wert (Kopie von KBI_Reifenumfang wenn dieser plausibel) oder Ersatzwert aus Bremse wenn KBI_Reifenumfang unplausibel. Bitte das QBit beachten!";
CM_ SG_ 253 ESP_21_CRC "FürMLB:
'Berechnung siehe Lastenheft 'Kommunikationsabsicherung für FlexRay und CAN''

Ab MQB und MLBevo:
'Berechnung siehe Lastenheft 'End-to-End Kommunikationsabsicherung''

Endwerte siehe Begleitdokument 'S-PDU Kennungsfolgen'";
CM_ SG_ 253 BR_Eingriffsmoment "EinheitenloserWert!FaktorinMO_Faktor_Momente_02inMotor_Code_01beachten!
Schnelle reduzierende (ASR) oder erhöhende (MSR) Momentanforderung an den Motor.";
CM_ SG_ 253 ESP_PLA_Bremseingriff "SignalisierungdesaktivenBremseingriffesdesESPaufgrundeinerBremsanforderungvomPLA.";
CM_ SG_ 253 ESP_Diagnose "MLB:NachDiagnoseendewirdeinSW-ResetausgelöstwelchereinenKommunikatiosausfallfürmax.150msverursacht.DiesistbeiSGmitverschärfterTimeoutüberwachung(nichtnachKonzern-LH)zubeachten.

MQB: Weiterführende Informationen im Lastenheft sp";
CM_ SG_ 253 ESC_Reku_Freigabe "MitdiesemBitwirddieRekuperationimMotorsteuergeräterlaubt.BeiAusfallESCwirdRekuperationnichtfreigegeben.

MQB/MQB2020: Wird nur von einem blendfähigen ESC unterstützt, wie es in mHEV und pHEV Fahrzeugen eingesetzt wird.";
CM_ SG_ 253 ESC_v_Signal_Qualifier_High_Low "DasQualifizerungssignalESC_v_Signal_Qualifier_High_LowgibteineInformationüberdieGütedervomBremsregelsystemausgegebenenGeschwindigkeitsinformation'mittlereGeschwindigkeit',wobeiVertrauensbereichefürdasausgegebeneGeschwindigkeitssignal";
CM_ SG_ 253 ESP_Vorsteuerung "zurUnterscheidungzwischenESP-VorsteuermaßnahmenundESP-Regeleingriffen";
CM_ SG_ 253 ESP_AWV3_Brems_aktiv "Teil-,Ziel-oderNotbremsungwirdimESPfürAWV3umgesetzt(dasMSGnutztdieseInfofürdenAbwurfderGRA-Regelung).";
CM_ SG_ 253 OBD_Schlechtweg "FürAusblendungderZündaussetzererkennungimMotorsteuergerät(Otto).Bitwirdgesetzt,wennRad-DrehbeschleunigungimESP>Grenzwertist.VorteilgegenüberRadgeschwindigkeiten,dassESPalle2msdynamischdieRad-Drehbeschleunigungerrechnetunddem";
CM_ SG_ 253 ESP_v_Signal "GeschwindigkeitssignalvomABS/ASRoderESP.MittelwertderangetriebenenRäder.
Bei MSR oder ABS Eingriffen wird die ABS-Referenzgeschwindigkeit für >= 200ms eingespiegelt (Zeit wird mit Aktiv-Flanke der Funktionsbits getriggert)

MQB: Bei Frontantrie";
CM_ SG_ 253 ASR_Tastung_passiv "ASRdeaktiviertoderSchwellengeändert(projektabhängig)
Weiterführende Informationen im Lastenheft spezifiziert und in der entsprechenden Fachabteilung zu erfragen.
";
CM_ SG_ 253 ESP_Tastung_passiv "ESPdeaktiviertoderSchwellengeändert(projektabhängig)
Weiterführende Informationen im Lastenheft spezifiziert und in der entsprechenden Fachabteilung zu erfragen.";
CM_ SG_ 253 ESP_Systemstatus "FehlerstehtfürStillegungESPmitFehlereintrag.

MLB: Flag wird bei Unterspannung im Stand bis einmalig 6km/h (AU48x) oder 10 km/h (AU641, AU57x) überschritten nicht gesetzt (Ausblendung Startvorgang)
Im AU64x, AU57x gilt ESP D4 Funktionsanforderung";
CM_ SG_ 253 ASR_Schalteingriff "WunschandasGetriebewährendeinerASRRegelung

MLB: Es wird nur 0x0 und 0x1 genutzt

";
CM_ SG_ 253 ESP_Haltebestaetigung "RückmeldungvomESP-SG,dassdasFahrzeugaufgrundeinerexternenBremsanforderung(z.B.ACC,PLA,ANB,o.ä.)abgebremstwurdeundimStillstandgehaltenwird.";
CM_ SG_ 253 ESP_MKB_Abbruch_Geschw "ImFalleeinerMultikollisionsbremsungteiltdasESPdenAbbruchderMKBaufgrundderunterenGeschwindigkeitsschwellemit.";
CM_ SG_ 253 ESP_QBit_v_Signal "GeschwindigkeitwirdvomABS/ASRoderESPausErsatzwertenerrechnet,wennBitgesetztist.GütedesSignalsistverändert.";
CM_ SG_ 253 ABS_Bremsung "Antiblockiersystem,BitzeigtauchDruckabbauan(z.B.ESPhatzuvielDruckaufgebautoderungebremsteRegelungaufBahnübergang)
Weiterführende Informationen im Lastenheft spezifiziert und in der entsprechenden Fachabteilung zu erfragen.";
CM_ SG_ 253 ASR_Anf "MLB:DieMomentenanforderung'ASR_MSR_Moment_schnell'und'ASR_Moment_langsam'sindauszuführen
MQB: Die Momentenanforderung 'BR_Eingriffsmoment' ist auszuführen";
CM_ SG_ 253 MSR_Anf "MLB:DieMomentenanforderung'ASR_MSR_Moment_schnell'istauszuführen.
MQB: Die Momentenanforderung 'BR_Eingriffsmoment' ist auszuführen";
CM_ SG_ 253 EBV_Eingriff "ElektronischeBremskraftverteilung,aktuellerEingriff(Druckhalten,Druckabbau)

Im MLB: kein ABS / ESP-Eingriff ???";
CM_ SG_ 253 EDS_Eingriff "ElektronischeDifferentialsperre";
CM_ SG_ 253 ESP_Eingriff "EingriffdesFahrdynamikreglers";
CM_ SG_ 253 ESP_ASP "MLB:Anhaenger-Stabilisierungs-Programm
MQB: Gespannstabilisierung";
CM_ SG_ 253 ESP_Anhaltevorgang_ACC_aktiv "Zeigtan,obACC-Anhaltevorgangaktiv";
CM_ SG_ 795 ESP_24_CRC "FürMLB:
'Berechnung siehe Lastenheft 'Kommunikationsabsicherung für FlexRay und CAN''

Ab MQB und MLBevo:
'Berechnung siehe Lastenheft 'End-to-End Kommunikationsabsicherung''

Endwerte siehe Begleitdokument 'S-PDU Kennungsfolgen'";
CM_ SG_ 795 ESP_Lampe "ZustandderFahrdynamikregelungslampe(MLB:ASRund/oderESP,MQB:nurESP)

Weiterführende Informationen im Lastenheft spezifiziert und in der entsprechenden Fachabteilung zu erfragen.";
CM_ SG_ 795 ABS_Lampe "Sicherheitswarnlampe

Weiterführende Informationen im Lastenheft spezifiziert und in der entsprechenden Fachabteilung zu erfragen.";
CM_ SG_ 795 BK_Lampe_02 "SicherheitswarnlampesignalisiertEBV-Ausfall

MQB: wird auch bei HBV-Ausfall verwendet.

Weiterführende Informationen im Lastenheft spezifiziert und in der entsprechenden Fachabteilung zu erfragen.";
CM_ SG_ 795 TC_Lampe "M-ABSLampe(separateLampefürM-ABS-SystemeMarktBrasilien)

Weiterführende Informationen im Lastenheft spezifiziert und in der entsprechenden Fachabteilung zu erfragen.";
CM_ SG_ 795 ESP_m_Raddrehz "RadumdrehungenproSekundesindEingangsgrößefürdieGeschwindigkeitsberechnungimKombi.AusdieserRaddrehzahlunddemRadumfangwirddieFahrzeuggeschwindigkeiterrechnet.

MLB: Exklusiver Empfänger ist das Kombiinstrument!
MQB: Bei Frontantrieb un";
CM_ SG_ 795 ESP_Textanzeigen_03 "TextanzeigenderFahrdynamikregelungimKombiinstrument

Weiterführende Informationen im Lastenheft spezifiziert und in der entsprechenden Fachabteilung zu erfragen.

Der Signalwert 24 wird nur im BY736 verwendet.";
CM_ SG_ 795 ESP_Meldungen "ESPsendetimHinweis-/StörungsfallandasKombiInformationenzumAnzeigen

Weiterführende Informationen im Lastenheft spezifiziert und in der entsprechenden Fachabteilung zu erfragen.
Ergänzender Hinweis:
1 = Autohold_Hinweis_1 (Anfahrassistent: nu";
CM_ SG_ 795 ESP_Wegimp_VA "WeiterführendeInformationenimLastenheftspezifiziertundinderentsprechendenFachabteilungzuerfragen.

MLB: Die Wegimpulse Vorderachse sind die gemittelten Werte (reine mathematische Operation: Addition und Division durch zwei, keine Filterung) d";
CM_ SG_ 795 ESP_Fehlerstatus_Wegimp "WeiterführendeInformationenimLastenheftspezifiziertundinderentsprechendenFachabteilungzuerfragen.

MLB: Fehler wird gesetzt, wenn beide ESP-Drehzahlfühler an der Vorderachse defekt sind.

MQB: Fehler wird gesetzt, wenn beide Raddrehzahlfühl";
CM_ SG_ 795 ESP_Wegimp_Ueberlauf "DerWegimpulszähleristproZündungslaufmindestenseinmalübergelaufen

Weiterführende Informationen im Lastenheft spezifiziert und in der entsprechenden Fachabteilung zu erfragen.";
CM_ SG_ 795 ESP_QBit_Wegimp_VA "GesetztbeiErsatzwert,InitoderFehler.";
CM_ SG_ 795 ESP_HDC_FktLampe "FunktionslampeBergabfahrassistent.
(Sender blinkt mit dem Bit 3,3Hz)";
CM_ SG_ 795 ESP_Off_Lampe "BitzurAnsteuerungderseparatenESP-off-LampeimKombi(GesetzesforderungUSA)

MLB:
Verwendung/Bedienung ab D4";
CM_ SG_ 795 ESP_HDC_Regelgeschw "Verwendung/BedienungnurimAU57xAllroad:
HDC-Geschwindigkeit
Dient der Anzeige der HDC-Geschwindigkeit und eines Bergabfahrsymbols im Kombi.
HDC-Standby wird gesetzt sobald der Fahrer den HDC-Taster aktiviert hat.
Bei HDC-Off oder während der Initia";
CM_ SG_ 795 ESP_BKV_Warnung "ESPsendetimHinweis-/StörungsfallandasKombiInformationenzumAnzeigen(Text+Akustik)

Im MQB wird dieses Signal nicht unterstützt!
";
CM_ SG_ 2589283617 ESP_30_CRC "FürMLB:
Berechnung siehe Lastenheft 'Kommunikationsabsicherung für FlexRay und CAN'
Ab MQB und MLBevo:
Berechnung siehe Lastenheft 'End-to-End Kommunikationsabsicherung'

Endwerte siehe Begleitdokument 'S-PDU Kennungsfolgen'";
CM_ SG_ 2589283617 ESP_30_BZ "4bitBotschaftszähler,wirdmitjederSendebotschaftinkrementiert";
CM_ SG_ 2589283617 EDS_Charisma_FahrPr "AktuellesFahrprogrammdesCharisma-TeilnehmersElektronischeDifferentialsperreEDS";
CM_ SG_ 2589283617 EDS_Charisma_Status "SystemstatusdesCharismateilnehmersElektronischeDifferentialsperreEDS";
CM_ SG_ 2589283617 HHC_Charisma_Status "SystemstatusdesCharismateilnehmersBerganfahrassistentHHC";
CM_ SG_ 2589283617 HHC_Charisma_FahrPr "AktuellesFahrprogrammdesCharisma-TeilnehmersBerganfahrassistentHHC";
CM_ SG_ 2589283617 RLE_Anzeigen "AnzeigenfürdieRadlöseerkennung";
CM_ SG_ 2589283617 ESC_Lernfreigabe_Abrollumfang "MeldeteinenFahrdynamikzustand,dereszulässt,dassderAbrollumfangderRädergenauererrechnetwerdendarf.
Die Verwendung des Signals ist ausschließlich für die MQB-Plattform zugelassen.";
CM_ SG_ 2589283617 ESC_Texte_eBKV_Betaetigung "AnweisungenandenFahrerfürdieBetätigungderBremseüberdeneBKVunterVerwendungderSchaltwippenamLenkrad.";
CM_ SG_ 2589283617 ESC_MBK_Meldungen "DasSignalsteuertdieSchaltempfehlungimKombi,diebeiBergabfahrtdenFahrerdaraufhinweistineinegeeigneteFahrstufezuschaltenumeineRekuperationzuermöglichen.";
CM_ SG_ 2589283617 ESC_Anf_KL "NachrichtanMotor-bzw.AntriebssteuergerätzurFestlegungderMotorluefterdrehzahl
Angabe in Prozent der Maximaldrehzahl";
CM_ SG_ 2589283617 ESC_Anf_KV "NachrichtanMotorbzw.AntriebssteuergerätzumÖffnenderKühlerjalousie.";
CM_ SG_ 2589283617 ESC_FBA_Meldungen "HinweisandenFahrerüberdasKombi,beidauerhafterBergabfahrteinenGangeinzulegenumdieMotorbremsezunutzen.
Unterscheidung zwischen:
Handschalterfahrzeugen (FBA_Warnung_aktiv_MT)
Automatikfahrzeugen (FBA_Warnung_aktiv_AT)";
CM_ SG_ 2589283617 DBK_Fahrerwarnung "WarntdenFahrerbeierkannterDampfblaseinderBremsflüssigkeitundfordertihnzumAnhaltensowieWerkstattbesuchauf(2Bit):
0: kein Anfordern (Initwert)
1: Warnereignis 1 - fordert Warnlampe, Warnmeldung (Aufforderung Anhalten) und Warnton sowie F";
CM_ SG_ 2527679668 eTM_Ventil1_Status "AnsteuerungNT2Kuehler-BypassventilimKuehlkreisHV-Komponenten";
CM_ SG_ 2527679668 eTM_Ventil2_Status "AnsteuerungHeizkreisabsperrventilimKühlkreisHTKreis";
CM_ SG_ 2527679668 eTM_Ventil3_Status "AnsteuerungGetriebeölkühler-AbsperrventilimKühlkreisHTKreis";
CM_ SG_ 2527679668 eTM_Pumpe3_Status "AnsteuerungPumpeNT1(KühlkreisNTKomponenten)";
CM_ SG_ 2527679668 eTM_BMS_Pumpe1_SollAnsteuerung "SollwertAnsteuerungBMSPumpe1fürBefüllung";
CM_ SG_ 2527679668 eTM_Pumpe2_Volumenstrom "Soll-KühlwasservolumenstromvonPumpe2KühlkreisHVKomponenten";
CM_ SG_ 2527679668 eTM_BMS_Ventil2_Befuellung "AnsteuerungBMSVentil2fürBefüllung";
CM_ SG_ 2527679668 eTM_Pumpe1_Volumenstrom "Soll-KühlwasservolumenstromvonPumpe1KühlkreisHVKomponenten";
CM_ SG_ 2527679668 eTM_BMS_Pumpe1_Befuellung "AnsteuerungBMSPumpe1fürBefüllungaktiv";
CM_ SG_ 2527679668 eTM_BMS_Ventil1_Befuellung "AnsteuerungBMSVentil1fürBefüllung";
CM_ SG_ 2527679668 eTM_Pumpe1_Status "AnsteuerungPumpe1KühlkreisHVKomponenten";
CM_ SG_ 2527679668 eTM_Pumpe2_Status "AnsteuerungPumpe2KühlkreisHVKomponenten";
CM_ SG_ 2527679668 eTM_Temperatur_1 "Wassertemperatur1KühlkreisHVKomponenten";
CM_ SG_ 2527679668 eTM_Temperatur_2 "Wassertemperatur2KühlkreisHVKomponenten";
CM_ SG_ 2527679740 KBI_aktive_Laengsfunktion_02 "Auswahl,dervomFahrergewünschtenLaengsregelfunktion";
CM_ SG_ 2527679740 KBI_Anzeigestatus_GRA "AnzeigestatusderGRAHighWunschgeschwindigkeitsanzeigeimKombiinstrument.
Bei VW bedeutet 'nicht vorhanden' GRA-low fähig (LED immer verbaut).
0 = nicht vorhanden
1 = Wunschgeschwindigkeits-Anzeigemöglichkeit vorhanden
2 = reserviert
3 = Fehler (B";
CM_ SG_ 2527679740 KBI_Anzeigestatus_LIM "AnzeigestatusderSpeedlimiterWunschgeschwindigkeitsanzeigeimKombiinstrument(permanenterAnzeigebereich)
0 = nicht vorhanden
1 = Wunschgeschwindigkeits-Anzeigemöglichkeit vorhanden
2 = reserviert
3 = Fehler (Botschaftsüberwachung, Timeout, Akustik";
CM_ SG_ 2527679740 KBI_Anzeigestatus_ACC "StatusderACC-AnzeigeimnichtpermanentenDisplaybereich";
CM_ SG_ 2527679740 KBI_Konsistenz_ACC "RückmeldunganACC,dassdieBotschaftenzurAnsteuerungvonAnzeigennichtbzw.nichtkonsistentempfangenwurden(Timeout-,BZ-,CHK-undDLC-Fehler)";
CM_ SG_ 2527679740 KBI_Fehler_Anzeige_ACC "RückmeldunganACC,dassmindestenseinederACC-relevantenAnzeigen-roteFahrerübernahme,Mitteldisplay,Gong-fehlerhaftsind.";
CM_ SG_ 2589283684 GRA_FoD_Status "VerortungdesFOD-SlavesfürdieFunktionGRAerfolgtimGateway.SignalübermitteltdenFOD-StatusandasMSG.";
CM_ SG_ 2589283684 FoD_Transmission_Info "MitdemSignalzeigtderFoD-MasterallenFoD-SlavesdenBeginnunddasEndeeinesFreischaltuebertragungszykluses(FS-ID-Zyklus)an.";
CM_ SG_ 2549875574 FoD_MO_01_Req_Data "FoD-FunctionOnDemand
ISO-TP Datenkanal - FID2NA Knoten 0x76 Motor (ASG)

FoD-Master an FoD-Slave ASG";
CM_ SG_ 2550006646 FoD_MO_01_Resp_Data "FoD-FunctionOnDemand
ISO-TP Datenkanal - FID2NA
Response Knoten 0x76 Motor

Motor an FoD Master";
CM_ SG_ 987 ZV_verriegelt_extern_soll "Sollzustand:VerriegelungFahrzeugaussen
";
CM_ SG_ 987 BH_Lichthupe "BetaetigungLichthupe
";
CM_ SG_ 987 WFS_Klemmenfreigabe "FreigabevonderWFSzumEinschaltenderKlemme15undKlemmeS";
CM_ SG_ 987 ZV_Tankklappe_offen "ÖffnungsstatusderTankklappe";
CM_ SG_ 987 AAG_Anhaenger_abgesteckt "AnhaengerwurdebeiKl.15ausabgesteckt";
CM_ SG_ 987 BCM1_LDS_Stellung "DasSignalwirdvomAFS/LWRSteuergerätempfangenunddientderVerifizierungderLichtdrehschalterstellung.IntelligenteLichtfunktionenwiedyn.KLundgleitendeLeuchtweite(GLW)nurbeiLDS='AUTO'.";
CM_ SG_ 987 VS_Verdeck_Anf "



";
CM_ SG_ 987 VS_VD_entriegelt "

";
CM_ SG_ 987 ZV_HFS_offen "gespiegeltesBitHFS_Tuer_geoeffnetTSG_HFS_1Botschaft";
CM_ SG_ 987 ZV_HBFS_offen "gespiegeltesBitHBFS_Tuer_geoeffnetTSG_HBFS_1Botschaft";
CM_ SG_ 987 VS_VD_offen_ver "ZustanddesVerdecksverriegeltundoffen";
CM_ SG_ 987 VS_VD_zu_ver "
";
CM_ SG_ 987 ZV_BT_offen "gespiegeltesBitBT_Tuer_geoeffnetTSG_BT_1Botschaft";
CM_ SG_ 987 BCM1_Rueckfahrlicht_Schalter "Rückfahrlichtschalter
ab MQB/ MLBevo: Die Ganginformation wird unentprellt übertragen, im AT-Getriebe wird evtl. kurzzeitig der R-Gang angezeigt. Eine Entprellung muß im Empfänger erfolgen (typisch 400ms).";
CM_ SG_ 987 ZV_FT_offen "gespiegeltesBitFT_Tuer_geoeffnetTSG_FT_1Botschaft";
CM_ SG_ 987 Wischer_vorne_aktiv "Status:Wischervorne";
CM_ SG_ 987 AAG_Anhaenger_erkannt "ErkennungAnhaenger";
CM_ SG_ 987 BCM1_MH_Schalter "Motorhaubenkontakt";
CM_ SG_ 987 ZV_HD_offen "StatusHeckdeckel
";
CM_ SG_ 987 Waschen_vorne_aktiv "Status:Waschenvorneaktiv
";
CM_ SG_ 987 KL_Thermomanagement "StufendesThermomanagement";
CM_ SG_ 987 WFS_Schluessel_Fahrberecht "SchlüsselnummerFahrberechtigung
0 = ungueltig, xxxx = Schluessel-Nr.";
CM_ SG_ 987 BCM_Rueckfahrlicht_Anf "AnforderungRückfahrlicht(Sollzustand).
Das Signal wird entprellt (typisch 400ms) und bei KL15EIN gesendet. Das Signal ist unabhängig von der Position des Heckdeckels (kein Überhitzungsschutz).";
CM_ SG_ 987 WWSs_01_alt "VeraltetBitfürdieLIN-BotschaftWWSs_01.

Betroffene Signale:

Wischer_vorne_aktiv";
CM_ SG_ 987 BCM_Tankklappensteller_Fehler "Fehler:nichtFunktionalitätdesTankklappenstellers";
CM_ SG_ 987 AAG_LED_aktiv "DiesesSignalsendetderBeleuchtungsartdesAnhängers(LEDoderLampe)
Bei LED aktiv erfolgt kein Kaltüberwachung";
CM_ SG_ 987 ZV_verriegelt_soll "FahrzeugGesamtverriegelungsstatusSollzustandfürLadestecker-undLadeklappenverriegelung.";
CM_ SG_ 987 ZV_Schluessel_Zugang "aktuelleFunkschlüsselnummer";
CM_ SG_ 987 WFS_ID_Geb_autorisiert_in_Kl15 "AuthorisierungdesSchlüsselsimaktivenKlemme-15-Zyklus";
CM_ SG_ 987 BH_Fernlicht "BetaetigungFernlicht
";
CM_ SG_ 987 BH_Blinker_li "BlinkerhebelRichtunglinks
";
CM_ SG_ 987 BH_Blinker_re "BlinkerhebelRichtungrechts
";
CM_ SG_ 987 BCM1_OBD_FStatus_ATemp "FehlerstatusUmgebungstemperatursensor(OBDrelevanterSensor)
";
CM_ SG_ 987 BCM1_Aussen_Temp_ungef "ungefilterterWertdesAussentemperatursensors
";
CM_ SG_ 173 Getriebe_11_CRC "FürMLB:
'Berechnung siehe Lastenheft 'Kommunikationsabsicherung für FlexRay und CAN''

Ab MQB und MLBevo:
'Berechnung siehe Lastenheft 'End-to-End Kommunikationsabsicherung''

Endwerte siehe Begleitdokument 'S-PDU Kennungsfolgen'";
CM_ SG_ 173 Getriebe_11_BZ "Botschaftszähler";
CM_ SG_ 173 GE_MMom_Soll_02 "MomenteneingriffandenMotor.
Fordert vom MSG eine kurzfristige Reduzierung oder Anhebung des Moments.
Das Signal ist nur gültig in Kombination mit GE_MMom_Status (bei MQB) bzw. GE_MMom_Status_02 (bei MLBevo).

Achtung:
Einheitenloser Wert! Faktor i";
CM_ SG_ 173 GE_MMom_Vorhalt_02 "AnforderungeinerMomentenreservedurchdasGetriebe,giltnurmitFreigabedurch
GE_Freig_MMom_Vorhalt

Anforderung wird als Absolut-Wert umgesetzt, nicht als Relativ-Wert/Delta zum aktuellen Ist-Moment (d. h. eine Momentenreserve wird eingestellt, w";
CM_ SG_ 173 GE_Uefkt "ÜbertragungsfunktiondesGetriebes
Drehzahlverhältnis = Eingangsdrehzahl / Ausgangsdrehzahl

AL: Wandlerverstärkung x Drehzahlverhältnis
VL: Drehzahlverhältnis
DL: Drehzahlverhältnis der aktiven und kraftschluß führenden Welle zum Abtrieb, bei Schalt";
CM_ SG_ 173 GE_Fahrstufe "FahrprogrammdesGetriebes

Hinweis: Zwischenstellung '0x0' darf nur für Zustandswechsel P/R, R/N, N/D ausgegeben werden, nicht für D/S oder D/Tippgasse wegen Abschaltkriterium GRA/ACC";
CM_ SG_ 173 GE_Schaltablauf "DasSignalzeigtdenaktuellenStatuseinesSchaltvorgangs.

Bei Signal = 0 liegt kein Schaltvorgang vor.
Bei Signal =2 liegt die Befüllphase der zuschaltenden Kupplung bzw.
die Vorbereitungsphase dazu vor.

Mit den unterschie";
CM_ SG_ 173 GE_Uefkt_unplausibel "DasSignaldarfnurimReku-ManagerinHybrid-Variantenverwendetwerden.
Zeigt an, ob die Plausibilisierung Momenten-Verhältnis zu Drehzahl-Verhältnis i.O. ist.
Ein gesetztes Signal meldet eine unplausible GE_Uefkt bzw. GE_Uefkt_02.";
CM_ SG_ 173 GE_MMom_Status_02 "DasSignalqualifiziertGE_MMom_Soll_02undgibtan,wiederWertausGE_MMom_soll–vorbehaltlichderUmsetzbarkeitaufgrundmotorinternerRestriktionen–umgesetztwerdensoll.
Werte:
0= kein Eingriff
1=   absoluter reduzierender Eingriff auf Gesamt ";
CM_ SG_ 173 GE_Status_Kraftschluss "ZeigtdenIst-StatusdesKraftschlussesimGetriebe.
(Anmerkung: meist wird damit der Zustand des Anfahrelements beschrieben, d.h. bei DL/DQ die Kupplung;  bei AQ/AL der Wandler incl. Überbrückungskupplung)
0 = offen, kein Kraftschluss
1 = offen mit Kr";
CM_ SG_ 173 GE_MMom_Status "Qualifiziert
MLB: GE_MMom_Soll
MQB: GE_MMom_Soll_02";
CM_ SG_ 173 GE_Freig_MMom_Vorhalt "FreigabefürdieAnforderungeinerMomentenreservedurchdasGetriebeüberdasSignal
MLB: GE_MMom_Vorhalt
MQB/MLBevo: GE_MMom_Vorhalt_02";
CM_ SG_ 173 GE_Verbot_Ausblendung "VerbotEinspritzausblendungfürkomfortableSchaltungen";
CM_ SG_ 173 GE_Zielgang "VL-Getriebe:
Signalisiert den Zielgang im manuellen Modus während eines Schaltvorgangs bzw. die momentane simulierte Gangstufe wenn kein Schaltvorgang aktiv ist. In den Fahrprogrammen 'D' und 'S' ist die Übersetzung variabel und somit wird dauerhaft 'Ist";
CM_ SG_ 324 Getriebe_16_CRC "FürMLB:
'Berechnung siehe Lastenheft 'Kommunikationsabsicherung für FlexRay und CAN''

Ab MQB und MLBevo:
'Berechnung siehe Lastenheft 'End-to-End Kommunikationsabsicherung''

Endwerte siehe Begleitdokument 'S-PDU Kennungsfolgen'";
CM_ SG_ 324 GE_Ausleuchtung_Fahrstufe "FahrstufezurAnzeigeinderSchaltbetätigung.IstdieFahrstufeungültig,wirdkeineFahrstufeangezeigt.";
CM_ SG_ 324 GE_Testparameter_1 "Testparameter1(Frage)zurÜberwachungdesWählhebel-SG";
CM_ SG_ 324 GE_Testparameter_2 "Testparameter2(Frage)zurÜberwachungdesWählhebel-SG";
CM_ SG_ 324 GE_Test_Freigabe "DasBitwirdauf1gesetzt,wenngültigeTestparametergesendetwerden.";
CM_ SG_ 324 GE_N_Haltephase "DasGetriebesignalisiertdemWaehlhebel,dassdieN-Haltephaseaktivist.
Danach kann der Waehlhebel ein Abschalten des I-CAN ermöglichen";
CM_ SG_ 324 GE_WH_Abschalten "MitdiesemBitkanndasGetriebedasWählhebel-SGresetenbzw.dauerhaftdeaktivieren.DerWählhebelgehtdannineinenStandby-Modus.";
CM_ SG_ 324 GE_Soll_Haltemagnet "SollpositiondesParksperren-HaltemagnetenfürdieAnsteuerungdurchdenWaehlhebel";
CM_ SG_ 324 GE_WH_Shiftlock "Bitwirdauf1gesetzt,wenngetriebeseitigenBedingungenerfülltsind,umWählhebelzubewegen.";
CM_ SG_ 324 GE_WH_Mute "AnforderungandieSchaltbetätigung,denSendebetriebeinzustellen.";
CM_ SG_ 324 GE_Ausleuchtung_blinkend "AnforderungeinerblinkendenFahrstufenausleuchtunginderSchaltbetätigung";
BA_DEF_ BO_ "DiagRequest" ENUM "No", "Yes";
BA_DEF_ BO_ "DiagResponse" ENUM "No", "Yes";
BA_DEF_ BO_ "DiagState" ENUM "No", "Yes";
BA_DEF_ BO_ "GenMsgChkConstant" HEX 0 4095;
BA_DEF_ BO_ "GenMsgCycleTime" INT 0 65535;
BA_DEF_ BO_ "GenMsgCycleTimeFast" INT 0 65535;
BA_DEF_ BO_ "GenMsgDelayTime" INT 0 100000;
BA_DEF_ BO_ "GenMsgILSupport" ENUM "No", "Yes";
BA_DEF_ BO_ "GenMsgNrOfRepetition" INT 0 100;
BA_DEF_ BO_ "GenMsgPDUConstants" STRING;
BA_DEF_ BO_ "GenMsgSendType" ENUM "Cyclic", "not_used", "not_used", "not_used", "not_used", "not_used", "not_used", "IfActive", "NoMsgSendType";
BA_DEF_ BO_ "GenMsgStartDelayTime" INT 0 100000;
BA_DEF_ BO_ "NmMessage" ENUM "No", "Yes";
BA_DEF_ BO_ "NmhMessage" ENUM "No", "Yes";
BA_DEF_ BO_ "MsgType" ENUM "Application", "NM", "NMH", "TP2.0", "ISO-TP", "BAP", "EID", "KS";
BA_DEF_ BO_ "VAGTP20_API" HEX 0 255;
BA_DEF_ BO_ "VAGTP20_DynConnection" ENUM "No", "Yes";
BA_DEF_ BO_ "VAGTP20_DynSetup" ENUM "No", "Yes";
BA_DEF_ BO_ "VAGTP20_StatConnection" ENUM "No", "Yes";
BA_DEF_ BO_ "CANFD_BRS" ENUM "0", "1";
BA_DEF_ BO_ "VFrameFormat" ENUM "StandardCAN", "ExtendedCAN", "reserved", "reserved", "reserved", "reserved", "reserved", "reserved", "reserved", "reserved", "reserved", "reserved", "reserved", "reserved", "StandardCAN_FD", "ExtendedCAN_FD";
BA_DEF_ SG_ "GenSigSendType" ENUM "Cyclic", "OnWrite", "OnWriteWithRepetition", "OnChange", "OnChangeWithRepetition", "IfActive", "IfActiveWithRepetition", "NoSigSendType", "OnChangeAndIfActive", "OnChangeAndIfActiveWithRepetition";
BA_DEF_ SG_ "GenSigFuncType" ENUM "NoFunction", "MsgCounter", "CRC-8", "XOR", "XOR-2", "DatedBit", "SW-Kl15", "CHK", "Constant", "Protocol", "CRC-8-SAE_J1850";
BA_DEF_ SG_ "GenSigSwitchedByIgnition" ENUM "No", "Yes";
BA_DEF_DEF_  "DiagRequest" "No";
BA_DEF_DEF_  "DiagResponse" "No";
BA_DEF_DEF_  "DiagState" "No";
BA_DEF_DEF_  "GenMsgChkConstant" 0;
BA_DEF_DEF_  "GenMsgCycleTime" 0;
BA_DEF_DEF_  "GenMsgCycleTimeFast" 0;
BA_DEF_DEF_  "GenMsgDelayTime" 0;
BA_DEF_DEF_  "GenMsgILSupport" "No";
BA_DEF_DEF_  "GenMsgNrOfRepetition" 0;
BA_DEF_DEF_  "GenMsgPDUConstants" "";
BA_DEF_DEF_  "GenMsgSendType" "NoMsgSendType";
BA_DEF_DEF_  "GenMsgStartDelayTime" 0;
BA_DEF_DEF_  "NmMessage" "No";
BA_DEF_DEF_  "NmhMessage" "No";
BA_DEF_DEF_  "MsgType" "Application";
BA_DEF_DEF_  "VAGTP20_API" 0;
BA_DEF_DEF_  "VAGTP20_DynConnection" "No";
BA_DEF_DEF_  "VAGTP20_DynSetup" "No";
BA_DEF_DEF_  "VAGTP20_StatConnection" "No";
BA_DEF_DEF_  "CANFD_BRS" "1";
BA_DEF_DEF_  "VFrameFormat" "StandardCAN";
BA_DEF_DEF_  "GenSigSendType" "NoSigSendType";
BA_DEF_DEF_  "GenSigFuncType" "NoFunction";
BA_DEF_DEF_  "GenSigSwitchedByIgnition" "Yes";
BA_ "GenMsgCycleTime" BO_ 1603 1000;
BA_ "GenMsgDelayTime" BO_ 1603 100;
BA_ "GenMsgILSupport" BO_ 1603 "Yes";
BA_ "GenMsgSendType" BO_ 1603 "Cyclic";
BA_ "VFrameFormat" BO_ 1603 "StandardCAN_FD";
BA_ "GenMsgCycleTime" BO_ 192 10;
BA_ "GenMsgILSupport" BO_ 192 "Yes";
BA_ "GenMsgPDUConstants" BO_ 192 "0x2f,0x44,0x72,0xd3,0x07,0xf2,0x39,0x09,0x8d,0x6f,0x57,0x20,0x37,0xf9,0x9b,0xfa";
BA_ "GenMsgSendType" BO_ 192 "Cyclic";
BA_ "VFrameFormat" BO_ 192 "StandardCAN_FD";
BA_ "GenMsgCycleTime" BO_ 2463978673 100;
BA_ "GenMsgILSupport" BO_ 2463978673 "Yes";
BA_ "GenMsgSendType" BO_ 2463978673 "Cyclic";
BA_ "VFrameFormat" BO_ 2463978673 "ExtendedCAN_FD";
BA_ "GenMsgCycleTime" BO_ 2589283657 500;
BA_ "GenMsgILSupport" BO_ 2589283657 "Yes";
BA_ "GenMsgSendType" BO_ 2589283657 "Cyclic";
BA_ "VFrameFormat" BO_ 2589283657 "ExtendedCAN_FD";
BA_ "GenMsgCycleTime" BO_ 184 500;
BA_ "GenMsgDelayTime" BO_ 184 20;
BA_ "GenMsgILSupport" BO_ 184 "Yes";
BA_ "GenMsgSendType" BO_ 184 "Cyclic";
BA_ "VFrameFormat" BO_ 184 "StandardCAN_FD";
BA_ "GenMsgCycleTime" BO_ 2527679712 1000;
BA_ "GenMsgILSupport" BO_ 2527679712 "Yes";
BA_ "GenMsgSendType" BO_ 2527679712 "Cyclic";
BA_ "VFrameFormat" BO_ 2527679712 "ExtendedCAN_FD";
BA_ "GenMsgCycleTime" BO_ 193 10;
BA_ "GenMsgILSupport" BO_ 193 "Yes";
BA_ "GenMsgPDUConstants" BO_ 193 "0xd7,0x12,0x85,0x7e,0x0b,0x34,0xfa,0x16,0x7a,0x25,0x2d,0x8f,0x04,0x8e,0x5d,0x35";
BA_ "GenMsgSendType" BO_ 193 "Cyclic";
BA_ "VFrameFormat" BO_ 193 "StandardCAN_FD";
BA_ "GenMsgCycleTime" BO_ 2463978674 100;
BA_ "GenMsgILSupport" BO_ 2463978674 "Yes";
BA_ "GenMsgSendType" BO_ 2463978674 "Cyclic";
BA_ "VFrameFormat" BO_ 2463978674 "ExtendedCAN_FD";
BA_ "GenMsgCycleTime" BO_ 2589283660 500;
BA_ "GenMsgILSupport" BO_ 2589283660 "Yes";
BA_ "GenMsgSendType" BO_ 2589283660 "Cyclic";
BA_ "VFrameFormat" BO_ 2589283660 "ExtendedCAN_FD";
BA_ "GenMsgCycleTime" BO_ 199 500;
BA_ "GenMsgDelayTime" BO_ 199 20;
BA_ "GenMsgILSupport" BO_ 199 "Yes";
BA_ "GenMsgSendType" BO_ 199 "Cyclic";
BA_ "VFrameFormat" BO_ 199 "StandardCAN_FD";
BA_ "GenMsgCycleTime" BO_ 2527679713 1000;
BA_ "GenMsgILSupport" BO_ 2527679713 "Yes";
BA_ "GenMsgSendType" BO_ 2527679713 "Cyclic";
BA_ "VFrameFormat" BO_ 2527679713 "ExtendedCAN_FD";
BA_ "GenMsgCycleTime" BO_ 2589283649 200;
BA_ "GenMsgILSupport" BO_ 2589283649 "Yes";
BA_ "GenMsgPDUConstants" BO_ 2589283649 "0x3e,0xb4,0x25,0xc1,0x31,0x1f,0xf1,0xd7,0xb1,0xbe,0xcc,0xe0,0x0f,0x46,0x51,0xb2";
BA_ "GenMsgSendType" BO_ 2589283649 "Cyclic";
BA_ "VFrameFormat" BO_ 2589283649 "ExtendedCAN_FD";
BA_ "GenMsgCycleTime" BO_ 608 50;
BA_ "GenMsgILSupport" BO_ 608 "Yes";
BA_ "GenMsgSendType" BO_ 608 "Cyclic";
BA_ "VFrameFormat" BO_ 608 "StandardCAN_FD";
BA_ "GenMsgCycleTime" BO_ 2589283751 500;
BA_ "GenMsgILSupport" BO_ 2589283751 "Yes";
BA_ "GenMsgSendType" BO_ 2589283751 "Cyclic";
BA_ "VFrameFormat" BO_ 2589283751 "ExtendedCAN_FD";
BA_ "GenMsgCycleTime" BO_ 2527679687 2000;
BA_ "GenMsgDelayTime" BO_ 2527679687 100;
BA_ "GenMsgILSupport" BO_ 2527679687 "Yes";
BA_ "GenMsgSendType" BO_ 2527679687 "Cyclic";
BA_ "VFrameFormat" BO_ 2527679687 "ExtendedCAN_FD";
BA_ "GenMsgCycleTime" BO_ 258 20;
BA_ "GenMsgILSupport" BO_ 258 "Yes";
BA_ "GenMsgPDUConstants" BO_ 258 "0xd7,0x12,0x85,0x7e,0x0b,0x34,0xfa,0x16,0x7a,0x25,0x2d,0x8f,0x04,0x8e,0x5d,0x35";
BA_ "GenMsgSendType" BO_ 258 "Cyclic";
BA_ "VFrameFormat" BO_ 258 "StandardCAN_FD";
BA_ "GenMsgCycleTime" BO_ 252 10;
BA_ "GenMsgILSupport" BO_ 252 "Yes";
BA_ "GenMsgPDUConstants" BO_ 252 "0x77,0x5c,0xa0,0x89,0x4b,0x7c,0xbb,0xd6,0x1f,0x6c,0x4f,0xf6,0x20,0x2b,0x43,0xdd";
BA_ "GenMsgSendType" BO_ 252 "Cyclic";
BA_ "VFrameFormat" BO_ 252 "StandardCAN_FD";
BA_ "GenMsgCycleTime" BO_ 2463978647 100;
BA_ "GenMsgILSupport" BO_ 2463978647 "Yes";
BA_ "GenMsgSendType" BO_ 2463978647 "Cyclic";
BA_ "VFrameFormat" BO_ 2463978647 "ExtendedCAN_FD";
BA_ "GenMsgCycleTime" BO_ 2527679683 2000;
BA_ "GenMsgDelayTime" BO_ 2527679683 100;
BA_ "GenMsgILSupport" BO_ 2527679683 "Yes";
BA_ "GenMsgSendType" BO_ 2527679683 "Cyclic";
BA_ "VFrameFormat" BO_ 2527679683 "ExtendedCAN_FD";
BA_ "GenMsgChkConstant" BO_ 278 172;
BA_ "GenMsgCycleTime" BO_ 278 20;
BA_ "GenMsgILSupport" BO_ 278 "Yes";
BA_ "GenMsgPDUConstants" BO_ 278 "0xac,0xac,0xac,0xac,0xac,0xac,0xac,0xac,0xac,0xac,0xac,0xac,0xac,0xac,0xac,0xac";
BA_ "GenMsgSendType" BO_ 278 "Cyclic";
BA_ "VFrameFormat" BO_ 278 "StandardCAN_FD";
BA_ "GenMsgCycleTime" BO_ 1629 1000;
BA_ "GenMsgDelayTime" BO_ 1629 200;
BA_ "GenMsgILSupport" BO_ 1629 "Yes";
BA_ "GenMsgPDUConstants" BO_ 1629 "0xac,0xb3,0xab,0xeb,0x7a,0xe1,0x3b,0xf7,0x73,0xba,0x7c,0x9e,0x06,0x5f,0x02,0xd9";
BA_ "GenMsgSendType" BO_ 1629 "Cyclic";
BA_ "VFrameFormat" BO_ 1629 "StandardCAN_FD";
BA_ "GenMsgCycleTime" BO_ 253 20;
BA_ "GenMsgILSupport" BO_ 253 "Yes";
BA_ "GenMsgPDUConstants" BO_ 253 "0xb4,0xef,0xf8,0x49,0x1e,0xe5,0xc2,0xc0,0x97,0x19,0x3c,0xc9,0xf1,0x98,0xd6,0x61";
BA_ "GenMsgSendType" BO_ 253 "Cyclic";
BA_ "VFrameFormat" BO_ 253 "StandardCAN_FD";
BA_ "GenMsgCycleTime" BO_ 795 50;
BA_ "GenMsgILSupport" BO_ 795 "Yes";
BA_ "GenMsgPDUConstants" BO_ 795 "0x67,0x8a,0xae,0x22,0x4d,0xd0,0x51,0x80,0x5c,0xb9,0xce,0x1e,0xdf,0x02,0x2d,0xd4";
BA_ "GenMsgSendType" BO_ 795 "Cyclic";
BA_ "VFrameFormat" BO_ 795 "StandardCAN_FD";
BA_ "GenMsgCycleTime" BO_ 2589283617 1000;
BA_ "GenMsgDelayTime" BO_ 2589283617 50;
BA_ "GenMsgILSupport" BO_ 2589283617 "Yes";
BA_ "GenMsgPDUConstants" BO_ 2589283617 "0xad,0xbd,0x5e,0x44,0x5b,0x90,0xb4,0x8d,0x9a,0x74,0xba,0xfa,0x2b,0x91,0xe2,0x89";
BA_ "GenMsgSendType" BO_ 2589283617 "Cyclic";
BA_ "VFrameFormat" BO_ 2589283617 "ExtendedCAN_FD";
BA_ "GenMsgCycleTime" BO_ 2527679668 500;
BA_ "GenMsgDelayTime" BO_ 2527679668 100;
BA_ "GenMsgILSupport" BO_ 2527679668 "Yes";
BA_ "GenMsgSendType" BO_ 2527679668 "Cyclic";
BA_ "VFrameFormat" BO_ 2527679668 "ExtendedCAN_FD";
BA_ "GenMsgCycleTime" BO_ 2527679740 200;
BA_ "GenMsgDelayTime" BO_ 2527679740 50;
BA_ "GenMsgILSupport" BO_ 2527679740 "Yes";
BA_ "GenMsgSendType" BO_ 2527679740 "Cyclic";
BA_ "VFrameFormat" BO_ 2527679740 "ExtendedCAN_FD";
BA_ "GenMsgCycleTime" BO_ 2589283684 1000;
BA_ "GenMsgDelayTime" BO_ 2589283684 200;
BA_ "GenMsgILSupport" BO_ 2589283684 "Yes";
BA_ "GenMsgSendType" BO_ 2589283684 "Cyclic";
BA_ "VFrameFormat" BO_ 2589283684 "ExtendedCAN_FD";
BA_ "MsgType" BO_ 2549875574 "ISO-TP";
BA_ "VFrameFormat" BO_ 2549875574 "ExtendedCAN_FD";
BA_ "MsgType" BO_ 2550006646 "ISO-TP";
BA_ "VFrameFormat" BO_ 2550006646 "ExtendedCAN_FD";
BA_ "GenMsgCycleTime" BO_ 987 100;
BA_ "GenMsgDelayTime" BO_ 987 10;
BA_ "GenMsgILSupport" BO_ 987 "Yes";
BA_ "GenMsgSendType" BO_ 987 "Cyclic";
BA_ "VFrameFormat" BO_ 987 "StandardCAN_FD";
BA_ "GenMsgCycleTime" BO_ 173 10;
BA_ "GenMsgILSupport" BO_ 173 "Yes";
BA_ "GenMsgPDUConstants" BO_ 173 "0x3f,0x69,0x39,0xdc,0x94,0xf9,0x14,0x64,0xd8,0x6a,0x34,0xce,0xa2,0x55,0xb5,0x2c";
BA_ "GenMsgSendType" BO_ 173 "Cyclic";
BA_ "VFrameFormat" BO_ 173 "StandardCAN_FD";
BA_ "GenMsgChkConstant" BO_ 324 227;
BA_ "GenMsgCycleTime" BO_ 324 20;
BA_ "GenMsgILSupport" BO_ 324 "Yes";
BA_ "GenMsgPDUConstants" BO_ 324 "0xe3,0xe3,0xe3,0xe3,0xe3,0xe3,0xe3,0xe3,0xe3,0xe3,0xe3,0xe3,0xe3,0xe3,0xe3,0xe3";
BA_ "GenMsgSendType" BO_ 324 "Cyclic";
BA_ "VFrameFormat" BO_ 324 "StandardCAN_FD";
BA_ "GenMsgCycleTime" BO_ 1603 1000;
BA_ "GenMsgDelayTime" BO_ 1603 100;
BA_ "GenMsgILSupport" BO_ 1603 "Yes";
BA_ "GenMsgSendType" BO_ 1603 "Cyclic";
BA_ "VFrameFormat" BO_ 1603 "StandardCAN_FD";
BA_ "GenMsgCycleTime" BO_ 192 10;
BA_ "GenMsgILSupport" BO_ 192 "Yes";
BA_ "GenMsgPDUConstants" BO_ 192 "0x2f,0x44,0x72,0xd3,0x07,0xf2,0x39,0x09,0x8d,0x6f,0x57,0x20,0x37,0xf9,0x9b,0xfa";
BA_ "GenMsgSendType" BO_ 192 "Cyclic";
BA_ "VFrameFormat" BO_ 192 "StandardCAN_FD";
BA_ "GenMsgCycleTime" BO_ 2463978673 100;
BA_ "GenMsgILSupport" BO_ 2463978673 "Yes";
BA_ "GenMsgSendType" BO_ 2463978673 "Cyclic";
BA_ "VFrameFormat" BO_ 2463978673 "ExtendedCAN_FD";
BA_ "GenMsgCycleTime" BO_ 2589283657 500;
BA_ "GenMsgILSupport" BO_ 2589283657 "Yes";
BA_ "GenMsgSendType" BO_ 2589283657 "Cyclic";
BA_ "VFrameFormat" BO_ 2589283657 "ExtendedCAN_FD";
BA_ "GenMsgCycleTime" BO_ 184 500;
BA_ "GenMsgDelayTime" BO_ 184 20;
BA_ "GenMsgILSupport" BO_ 184 "Yes";
BA_ "GenMsgSendType" BO_ 184 "Cyclic";
BA_ "VFrameFormat" BO_ 184 "StandardCAN_FD";
BA_ "GenMsgCycleTime" BO_ 2527679712 1000;
BA_ "GenMsgILSupport" BO_ 2527679712 "Yes";
BA_ "GenMsgSendType" BO_ 2527679712 "Cyclic";
BA_ "VFrameFormat" BO_ 2527679712 "ExtendedCAN_FD";
BA_ "GenMsgCycleTime" BO_ 193 10;
BA_ "GenMsgILSupport" BO_ 193 "Yes";
BA_ "GenMsgPDUConstants" BO_ 193 "0xd7,0x12,0x85,0x7e,0x0b,0x34,0xfa,0x16,0x7a,0x25,0x2d,0x8f,0x04,0x8e,0x5d,0x35";
BA_ "GenMsgSendType" BO_ 193 "Cyclic";
BA_ "VFrameFormat" BO_ 193 "StandardCAN_FD";
BA_ "GenMsgCycleTime" BO_ 2463978674 100;
BA_ "GenMsgILSupport" BO_ 2463978674 "Yes";
BA_ "GenMsgSendType" BO_ 2463978674 "Cyclic";
BA_ "VFrameFormat" BO_ 2463978674 "ExtendedCAN_FD";
BA_ "GenMsgCycleTime" BO_ 2589283660 500;
BA_ "GenMsgILSupport" BO_ 2589283660 "Yes";
BA_ "GenMsgSendType" BO_ 2589283660 "Cyclic";
BA_ "VFrameFormat" BO_ 2589283660 "ExtendedCAN_FD";
BA_ "GenMsgCycleTime" BO_ 199 500;
BA_ "GenMsgDelayTime" BO_ 199 20;
BA_ "GenMsgILSupport" BO_ 199 "Yes";
BA_ "GenMsgSendType" BO_ 199 "Cyclic";
BA_ "VFrameFormat" BO_ 199 "StandardCAN_FD";
BA_ "GenMsgCycleTime" BO_ 2527679713 1000;
BA_ "GenMsgILSupport" BO_ 2527679713 "Yes";
BA_ "GenMsgSendType" BO_ 2527679713 "Cyclic";
BA_ "VFrameFormat" BO_ 2527679713 "ExtendedCAN_FD";
BA_ "GenMsgCycleTime" BO_ 2589283649 200;
BA_ "GenMsgILSupport" BO_ 2589283649 "Yes";
BA_ "GenMsgPDUConstants" BO_ 2589283649 "0x3e,0xb4,0x25,0xc1,0x31,0x1f,0xf1,0xd7,0xb1,0xbe,0xcc,0xe0,0x0f,0x46,0x51,0xb2";
BA_ "GenMsgSendType" BO_ 2589283649 "Cyclic";
BA_ "VFrameFormat" BO_ 2589283649 "ExtendedCAN_FD";
BA_ "GenMsgCycleTime" BO_ 608 50;
BA_ "GenMsgILSupport" BO_ 608 "Yes";
BA_ "GenMsgSendType" BO_ 608 "Cyclic";
BA_ "VFrameFormat" BO_ 608 "StandardCAN_FD";
BA_ "GenMsgCycleTime" BO_ 2589283751 500;
BA_ "GenMsgILSupport" BO_ 2589283751 "Yes";
BA_ "GenMsgSendType" BO_ 2589283751 "Cyclic";
BA_ "VFrameFormat" BO_ 2589283751 "ExtendedCAN_FD";
BA_ "GenMsgCycleTime" BO_ 2527679687 2000;
BA_ "GenMsgDelayTime" BO_ 2527679687 100;
BA_ "GenMsgILSupport" BO_ 2527679687 "Yes";
BA_ "GenMsgSendType" BO_ 2527679687 "Cyclic";
BA_ "VFrameFormat" BO_ 2527679687 "ExtendedCAN_FD";
BA_ "GenMsgCycleTime" BO_ 258 20;
BA_ "GenMsgILSupport" BO_ 258 "Yes";
BA_ "GenMsgPDUConstants" BO_ 258 "0xd7,0x12,0x85,0x7e,0x0b,0x34,0xfa,0x16,0x7a,0x25,0x2d,0x8f,0x04,0x8e,0x5d,0x35";
BA_ "GenMsgSendType" BO_ 258 "Cyclic";
BA_ "VFrameFormat" BO_ 258 "StandardCAN_FD";
BA_ "GenMsgCycleTime" BO_ 252 10;
BA_ "GenMsgILSupport" BO_ 252 "Yes";
BA_ "GenMsgPDUConstants" BO_ 252 "0x77,0x5c,0xa0,0x89,0x4b,0x7c,0xbb,0xd6,0x1f,0x6c,0x4f,0xf6,0x20,0x2b,0x43,0xdd";
BA_ "GenMsgSendType" BO_ 252 "Cyclic";
BA_ "VFrameFormat" BO_ 252 "StandardCAN_FD";
BA_ "GenMsgCycleTime" BO_ 2463978647 100;
BA_ "GenMsgILSupport" BO_ 2463978647 "Yes";
BA_ "GenMsgSendType" BO_ 2463978647 "Cyclic";
BA_ "VFrameFormat" BO_ 2463978647 "ExtendedCAN_FD";
BA_ "GenMsgCycleTime" BO_ 2527679683 2000;
BA_ "GenMsgDelayTime" BO_ 2527679683 100;
BA_ "GenMsgILSupport" BO_ 2527679683 "Yes";
BA_ "GenMsgSendType" BO_ 2527679683 "Cyclic";
BA_ "VFrameFormat" BO_ 2527679683 "ExtendedCAN_FD";
BA_ "GenMsgChkConstant" BO_ 278 172;
BA_ "GenMsgCycleTime" BO_ 278 20;
BA_ "GenMsgILSupport" BO_ 278 "Yes";
BA_ "GenMsgPDUConstants" BO_ 278 "0xac,0xac,0xac,0xac,0xac,0xac,0xac,0xac,0xac,0xac,0xac,0xac,0xac,0xac,0xac,0xac";
BA_ "GenMsgSendType" BO_ 278 "Cyclic";
BA_ "VFrameFormat" BO_ 278 "StandardCAN_FD";
BA_ "GenMsgCycleTime" BO_ 1629 1000;
BA_ "GenMsgDelayTime" BO_ 1629 200;
BA_ "GenMsgILSupport" BO_ 1629 "Yes";
BA_ "GenMsgPDUConstants" BO_ 1629 "0xac,0xb3,0xab,0xeb,0x7a,0xe1,0x3b,0xf7,0x73,0xba,0x7c,0x9e,0x06,0x5f,0x02,0xd9";
BA_ "GenMsgSendType" BO_ 1629 "Cyclic";
BA_ "VFrameFormat" BO_ 1629 "StandardCAN_FD";
BA_ "GenMsgCycleTime" BO_ 253 20;
BA_ "GenMsgILSupport" BO_ 253 "Yes";
BA_ "GenMsgPDUConstants" BO_ 253 "0xb4,0xef,0xf8,0x49,0x1e,0xe5,0xc2,0xc0,0x97,0x19,0x3c,0xc9,0xf1,0x98,0xd6,0x61";
BA_ "GenMsgSendType" BO_ 253 "Cyclic";
BA_ "VFrameFormat" BO_ 253 "StandardCAN_FD";
BA_ "GenMsgCycleTime" BO_ 795 50;
BA_ "GenMsgILSupport" BO_ 795 "Yes";
BA_ "GenMsgPDUConstants" BO_ 795 "0x67,0x8a,0xae,0x22,0x4d,0xd0,0x51,0x80,0x5c,0xb9,0xce,0x1e,0xdf,0x02,0x2d,0xd4";
BA_ "GenMsgSendType" BO_ 795 "Cyclic";
BA_ "VFrameFormat" BO_ 795 "StandardCAN_FD";
BA_ "GenMsgCycleTime" BO_ 2589283617 1000;
BA_ "GenMsgDelayTime" BO_ 2589283617 50;
BA_ "GenMsgILSupport" BO_ 2589283617 "Yes";
BA_ "GenMsgPDUConstants" BO_ 2589283617 "0xad,0xbd,0x5e,0x44,0x5b,0x90,0xb4,0x8d,0x9a,0x74,0xba,0xfa,0x2b,0x91,0xe2,0x89";
BA_ "GenMsgSendType" BO_ 2589283617 "Cyclic";
BA_ "VFrameFormat" BO_ 2589283617 "ExtendedCAN_FD";
BA_ "GenMsgCycleTime" BO_ 2527679668 500;
BA_ "GenMsgDelayTime" BO_ 2527679668 100;
BA_ "GenMsgILSupport" BO_ 2527679668 "Yes";
BA_ "GenMsgSendType" BO_ 2527679668 "Cyclic";
BA_ "VFrameFormat" BO_ 2527679668 "ExtendedCAN_FD";
BA_ "GenMsgCycleTime" BO_ 2527679740 200;
BA_ "GenMsgDelayTime" BO_ 2527679740 50;
BA_ "GenMsgILSupport" BO_ 2527679740 "Yes";
BA_ "GenMsgSendType" BO_ 2527679740 "Cyclic";
BA_ "VFrameFormat" BO_ 2527679740 "ExtendedCAN_FD";
BA_ "GenMsgCycleTime" BO_ 2589283684 1000;
BA_ "GenMsgDelayTime" BO_ 2589283684 200;
BA_ "GenMsgILSupport" BO_ 2589283684 "Yes";
BA_ "GenMsgSendType" BO_ 2589283684 "Cyclic";
BA_ "VFrameFormat" BO_ 2589283684 "ExtendedCAN_FD";
BA_ "MsgType" BO_ 2549875574 "ISO-TP";
BA_ "VFrameFormat" BO_ 2549875574 "ExtendedCAN_FD";
BA_ "MsgType" BO_ 2550006646 "ISO-TP";
BA_ "VFrameFormat" BO_ 2550006646 "ExtendedCAN_FD";
BA_ "GenMsgCycleTime" BO_ 987 100;
BA_ "GenMsgDelayTime" BO_ 987 10;
BA_ "GenMsgILSupport" BO_ 987 "Yes";
BA_ "GenMsgSendType" BO_ 987 "Cyclic";
BA_ "VFrameFormat" BO_ 987 "StandardCAN_FD";
BA_ "GenMsgCycleTime" BO_ 173 10;
BA_ "GenMsgILSupport" BO_ 173 "Yes";
BA_ "GenMsgPDUConstants" BO_ 173 "0x3f,0x69,0x39,0xdc,0x94,0xf9,0x14,0x64,0xd8,0x6a,0x34,0xce,0xa2,0x55,0xb5,0x2c";
BA_ "GenMsgSendType" BO_ 173 "Cyclic";
BA_ "VFrameFormat" BO_ 173 "StandardCAN_FD";
BA_ "GenMsgChkConstant" BO_ 324 227;
BA_ "GenMsgCycleTime" BO_ 324 20;
BA_ "GenMsgILSupport" BO_ 324 "Yes";
BA_ "GenMsgPDUConstants" BO_ 324 "0xe3,0xe3,0xe3,0xe3,0xe3,0xe3,0xe3,0xe3,0xe3,0xe3,0xe3,0xe3,0xe3,0xe3,0xe3,0xe3";
BA_ "GenMsgSendType" BO_ 324 "Cyclic";
BA_ "VFrameFormat" BO_ 324 "StandardCAN_FD";
VAL_ 1603 KBI_Einheit_Datum 0 "Tag/Monat/Jahr" 1 "Monat/Tag/Jahr" 2 "Jahr/Monat/Tag" 3 "reserviert";
VAL_ 1603 KBI_Einheit_Druck 0 "Druckangabe in bar" 1 "Druckangabe in psi" 2 "Druckangabe in kPa" 3 "tbd.";
VAL_ 1603 KBI_Einheit_Streckenanz 0 "Kilometer" 1 "Meilen";
VAL_ 1603 KBI_MFA_v_Einheit_02 0 "kmh" 1 "mph";
VAL_ 1603 KBI_Einheit_Temp 0 "Grad Celsius °C" 1 "Grad Fahrenheit °F";
VAL_ 1603 KBI_Einheit_Uhrzeit 0 "24h" 1 " 12h AM/PM";
VAL_ 1603 KBI_Einheit_Verbrauch 0 "mpg UK" 1 "mpg USA" 2 "Liter/100km" 3 "km/Liter";
VAL_ 1603 KBI_Einheit_Volumen 0 "Liter" 1 "Gallonen UK" 2 "Gallonen USA" 3 "reserviert";
VAL_ 1603 KBI_Einheit_Verbrauch_elektr 0 "kWh_pro_100km" 1 "km_pro_kWh" 2 "kWh_pro_100mls" 3 "mls_pro_kWh" 4 "MPGe";
VAL_ 1603 KBI_Einheit_Tacho 0 "km/h" 1 "mph";
VAL_ 1603 KBI_Einheit_Verbrauch_Gas 0 "kg_per_100km" 1 "km_per_kg" 2 "m3_per_100km" 3 "km_per_m3" 4 "miles_per_lbs" 5 "miles_per_yard3" 6 "miles_per_kg" 7 "miles_per_m3" 8 "miles_per_gallon_equivalent_US";
VAL_ 1603 KBI_Einheit_Masse 0 "kg" 1 "lbs" 2 "reserviert";
VAL_ 192 EM1_Istmodus 0 "Standby" 1 "Momentenreg" 2 "Int_Drehzahlreg" 3 "Spannungsreg" 4 "Ext_Drehzahlreg" 5 "Inverter_Fehler" 6 "Kalibrierung" 7 "Sonderbremsbetrieb" 8 "Freilauf" 15 "Initialisierung";
VAL_ 192 EM1_IstMoment 4094 "Init" 4095 "Fehler";
VAL_ 192 EM1_Moment_AR_Eingriff 4094 "Init" 4095 "Fehler";
VAL_ 192 EM1_IstDrehzahl 32766 "Init" 32767 "Fehler";
VAL_ 192 EM1_AR_aktiv 0 "Init" 1 "Ruckeldaempfer_aktiv";
VAL_ 192 EM1_IstSpannung 4094 "Init" 4095 "Fehler";
VAL_ 192 EM1_Strom_HV 4094 "Init" 4095 "Fehler";
VAL_ 192 EM1_Max_Moment 2046 "Init" 2047 "Fehler";
VAL_ 192 EM1_ErwGrenzen_aktiv 0 "kein_extended_Range" 1 "extended_Range";
VAL_ 192 EM1_Min_Moment 2046 "Init" 2047 "Fehler";
VAL_ 192 EM1_Fehler_ElAntriebAbschaltung 0 "Init" 1 "Abschaltung";
VAL_ 192 EM1_Max_Moment_Lim 2046 "Init" 2047 "Fehler";
VAL_ 192 EM1_Fehler_Notabschaltung 0 "kein_Fehler" 1 "Fehler";
VAL_ 192 EM1_Min_Moment_Lim 2046 "Init" 2047 "Fehler";
VAL_ 192 EM1_Status_DrzEingriff 0 "kein_Eingriff" 1 "Eingriff_Max_Drehzahlregler" 2 "Eingriff_Min_Drehzahlregler" 3 "Fehler";
VAL_ 192 EM1_Mom_DrzEingriff 2046 "Init" 2047 "Fehler";
VAL_ 2463978673 EM1_Status_Spgfreiheit 0 "Init" 1 "HV_Komponente_spannungsfrei" 2 "HV_Komp_nicht_spannungsfrei" 3 "Fehler_nicht_spannungsfrei";
VAL_ 2463978673 EM1_Status_EoHVL 0 "Init" 1 "Keine_offene_HV_Leitung_erkannt" 2 "offene_HV_Leitung_erkannt" 3 "Fehler";
VAL_ 2463978673 EM1_Max_LeistungMech_Sockel 8190 "Init" 8191 "Fehler";
VAL_ 2463978673 EM1_Max_Moment_Sockel 2046 "Init" 2047 "Fehler";
VAL_ 2463978673 EM1_Min_LeistungMech_Sockel 8190 "Init" 8191 "Fehler";
VAL_ 2463978673 EM1_Min_Moment_Sockel 2046 "Init" 2047 "Fehler";
VAL_ 2463978673 EM1_PerfInd_MaxLeistung 1022 "Init";
VAL_ 2463978673 EM1_PerfInd_MaxMoment 1022 "Init";
VAL_ 2463978673 EM1_AnlernenElMotor_Anf 0 "kein_Diagnose_Request" 1 "Diagnose_Request";
VAL_ 2463978673 EM1_OBD_Lampe_Anf 0 "kein_MIL_Request" 1 "MIL_Request";
VAL_ 2463978673 EM1_Generator_Moment 1022 "Init" 1023 "Fehler";
VAL_ 2463978673 EM1_PerfInd_Temperatur 254 "Init";
VAL_ 2463978673 EM1_MaxZul_Drehzahl 254 "Init" 255 "Fehler";
VAL_ 2463978673 EM1_Min_Moment_Gesamt 2046 "Init" 2047 "Fehler";
VAL_ 2463978673 EM1_Fehlerlampe_Anf 0 "kein_Fehler" 1 "Anforderung_rote_Lampe";
VAL_ 2463978673 EM1_Max_Moment_Gesamt 2046 "Init" 2047 "Fehler";
VAL_ 2463978673 EM1_Warnlampe_Anf 0 "kein_Fehler" 1 "Anforderung_gelbe_Lampe";
VAL_ 2463978673 EM1_Rekuperation_Ueberlauf 0 "kein_Ueberlauf" 1 "Ueberlauf";
VAL_ 2463978673 EM1_Verbrauch_Ueberlauf 0 "kein_Ueberlauf" 1 "Ueberlauf";
VAL_ 2463978673 EM1_Fehler_AE 0 "kein_Fehler" 1 "Fehler_aktive_Entladung";
VAL_ 2463978673 EM1_Fehler_Leistungsred 0 "Init" 1 "Leistungsreduzierung";
VAL_ 2463978673 EM1_Fehler_ElAntriebFreilauf 0 "Init" 1 "Fehler__EM_im_Freilauf";
VAL_ 2463978673 EM1_PWR_SollVolumenstrom 62 "Init" 63 "Fehler";
VAL_ 2589283657 EM1_SollVorlauftemperatur 254 "Init" 255 "Fehler";
VAL_ 2589283657 EM1_Temperatur_EM 510 "Init" 511 "Fehler";
VAL_ 2589283657 EM1_EM_SollVolumenstrom 62 "Init" 63 "Fehler";
VAL_ 2589283657 EM1_Max_MechLeistung_nom 4094 "Init" 4095 "Fehler";
VAL_ 2589283657 EM1_Max_Moment_nom 1022 "Init" 1023 "Fehler";
VAL_ 2589283657 EM1_Temperatur_PWR 254 "Init" 255 "Fehler";
VAL_ 184 EM1_Freigabe_Info_WFS 0 "ungueltig" 1 "gueltig";
VAL_ 184 EM1_Sperr_Info_WFS 0 "nicht_gesperrt" 1 "gesperrt";
VAL_ 184 EM1_AR_aktiv 0 "Init" 1 "Ruckeldaempfer_aktiv";
VAL_ 184 EM1_Eta_Sys 510 "Init" 511 "Fehler";
VAL_ 184 EM1_IstStrom 2046 "Init" 2047 "Fehler";
VAL_ 184 EM1_Fehler_ElAntriebFreilauf_Anf 0 "Init" 1 "Fehler_EM_im_Freilauf";
VAL_ 184 EM1_Abregelung_Temperatur 0 "Init" 1 "Abregelung_Temperatur";
VAL_ 184 EM1_AnlernenElMotor_Anf 0 "kein_Diagnose_Request" 1 "Diagnose_Request";
VAL_ 184 EM1_Moment_HVVerbraucher 1023 "Init";
VAL_ 184 EM1_Freigabe_Verfallsinfo_WFS 0 "Aus" 1 "Ein";
VAL_ 184 EM1_Parken_WFS_Status 0 "Limitierung_Inaktiv" 1 "Limitierung_Aktiv" 2 "Abbruch";
VAL_ 184 EM1_HV_betriebsbereit 0 "Init" 1 "Ready_HV";
VAL_ 2527679712 EM1_RtmWarnKommunikation 0 "kein_Fehler" 1 "Fehler_Stufe_1" 2 "Fehler_Stufe_2" 3 "Fehler_Stufe_3" 4 "reserviert" 5 "reserviert" 6 "reserviert" 7 "reserviert";
VAL_ 2527679712 EM1_RtmWarnUeberdrehzahl 0 "kein_Fehler" 1 "Fehler_Stufe_1" 2 "Fehler_Stufe_2" 3 "Fehler_Stufe_3" 4 "reserviert" 5 "reserviert" 6 "reserviert" 7 "reserviert";
VAL_ 2527679712 EM1_RtmWarnUeberstrom 0 "kein_Fehler" 1 "Fehler_Stufe_1" 2 "Fehler_Stufe_2" 3 "Fehler_Stufe_3" 4 "reserviert" 5 "reserviert" 6 "reserviert" 7 "reserviert";
VAL_ 2527679712 EM1_RtmWarnTempEM 0 "kein_Fehler" 1 "Fehler_Stufe_1" 2 "Fehler_Stufe_2" 3 "Fehler_Stufe_3" 4 "reserviert" 5 "reserviert" 6 "reserviert" 7 "reserviert";
VAL_ 2527679712 EM1_RtmWarnTempPWR 0 "kein_Fehler" 1 "Fehler_Stufe_1" 2 "Fehler_Stufe_2" 3 "Fehler_Stufe_3" 4 "reserviert" 5 "reserviert" 6 "reserviert" 7 "reserviert";
VAL_ 193 EM2_Istmodus 0 "Standby" 1 "Momentenreg" 2 "Int_Drehzahlreg" 3 "Spannungsreg" 4 "Ext_Drehzahlreg" 5 "Inverter_Fehler" 6 "Kalibrierung" 7 "Sonderbremsbetrieb" 8 "Freilauf" 15 "Initialisierung";
VAL_ 193 EM2_IstMoment 4094 "Init" 4095 "Fehler";
VAL_ 193 EM2_Moment_AR_Eingriff 4094 "Init" 4095 "Fehler";
VAL_ 193 EM2_IstDrehzahl 32766 "Init" 32767 "Fehler";
VAL_ 193 EM2_AR_aktiv 0 "Init";
VAL_ 193 EM2_IstSpannung 4094 "Init" 4095 "Fehler";
VAL_ 193 EM2_Strom_HV 4094 "Init" 4095 "Fehler";
VAL_ 193 EM2_Max_Moment 2046 "Init" 2047 "Fehler";
VAL_ 193 EM2_ErwGrenzen_aktiv 0 "kein_extended_Range" 1 "extended_Range";
VAL_ 193 EM2_Min_Moment 2046 "Init" 2047 "Fehler";
VAL_ 193 EM2_Fehler_ElAntriebAbschaltung 0 "Init" 1 "Abschaltung";
VAL_ 193 EM2_Max_Moment_Lim 2046 "Init" 2047 "Fehler";
VAL_ 193 EM2_Fehler_Notabschaltung 0 "kein_Fehler" 1 "Fehler";
VAL_ 193 EM2_Min_Moment_Lim 2046 "Init" 2047 "Fehler";
VAL_ 193 EM2_Status_DrzEingriff 0 "kein_Eingriff" 1 "Eingriff_Max_Drehzahlregler" 2 "Eingriff_Min_Drehzahlregler" 3 "Fehler";
VAL_ 193 EM2_Mom_DrzEingriff 2046 "Init" 2047 "Fehler";
VAL_ 2463978674 EM2_Status_Spgfreiheit 0 "Init" 1 "HV_Komponente_spannungsfrei" 2 "HV_Komp_nicht_spannungsfrei" 3 "Fehler_nicht_spannungsfrei";
VAL_ 2463978674 EM2_Status_EoHVL 0 "Init" 1 "Keine_offene_HV_Leitung_erkannt" 2 "offene_HV_Leitung_erkannt" 3 "Fehler";
VAL_ 2463978674 EM2_Max_LeistungMech_Sockel 8190 "Init" 8191 "Fehler";
VAL_ 2463978674 EM2_Max_Moment_Sockel 2046 "Init" 2047 "Fehler";
VAL_ 2463978674 EM2_Min_LeistungMech_Sockel 8190 "Init" 8191 "Fehler";
VAL_ 2463978674 EM2_Min_Moment_Sockel 2046 "Init" 2047 "Fehler";
VAL_ 2463978674 EM2_PerfInd_MaxLeistung 1022 "Init";
VAL_ 2463978674 EM2_PerfInd_MaxMoment 1022 "Init";
VAL_ 2463978674 EM2_AnlernenElMotor_Anf 0 "kein_Diagnose_Request" 1 "Diagnose_Request";
VAL_ 2463978674 EM2_OBD_Lampe_Anf 0 "kein_MIL_Request" 1 "MIL_Request";
VAL_ 2463978674 EM2_Generator_Moment 1022 "Init" 1023 "Fehler";
VAL_ 2463978674 EM2_PerfInd_Temperatur 254 "Init";
VAL_ 2463978674 EM2_MaxZul_Drehzahl 254 "Init" 255 "Fehler";
VAL_ 2463978674 EM2_Min_Moment_Gesamt 2046 "Init" 2047 "Fehler";
VAL_ 2463978674 EM2_Fehlerlampe_Anf 0 "kein_Fehler" 1 "Anforderung_rote_Lampe";
VAL_ 2463978674 EM2_Max_Moment_Gesamt 2046 "Init" 2047 "Fehler";
VAL_ 2463978674 EM2_Warnlampe_Anf 0 "kein_Fehler" 1 "Anforderung_gelbe_Lampe";
VAL_ 2463978674 EM2_Rekuperation_Ueberlauf 0 "kein_Ueberlauf" 1 "Ueberlauf";
VAL_ 2463978674 EM2_Verbrauch_Ueberlauf 0 "kein_Ueberlauf" 1 "Ueberlauf";
VAL_ 2463978674 EM2_Fehler_AE 0 "kein_Fehler" 1 "Fehler_aktive_Entladung";
VAL_ 2463978674 EM2_Fehler_Leistungsred 0 "Init" 1 "Leistungsreduzierung";
VAL_ 2463978674 EM2_Fehler_ElAntriebFreilauf 0 "Init" 1 "Fehler__EM_im_Freilauf";
VAL_ 2463978674 EM2_PWR_SollVolumenstrom 62 "Init" 63 "Fehler";
VAL_ 2589283660 EM2_SollVorlauftemperatur 254 "Init" 255 "Fehler";
VAL_ 2589283660 EM2_Temperatur_EM 510 "Init" 511 "Fehler";
VAL_ 2589283660 EM2_EM_SollVolumenstrom 62 "Init" 63 "Fehler";
VAL_ 2589283660 EM2_Max_MechLeistung_nom 4094 "Init" 4095 "Fehler";
VAL_ 2589283660 EM2_Max_Moment_nom 1022 "Init" 1023 "Fehler";
VAL_ 2589283660 EM2_Temperatur_PWR 254 "Init" 255 "Fehler";
VAL_ 199 EM2_Freigabe_Info_WFS 0 "ungueltig" 1 "gueltig";
VAL_ 199 EM2_Sperr_Info_WFS 0 "nicht_gesperrt" 1 "gesperrt";
VAL_ 199 EM2_AR_aktiv 0 "Init";
VAL_ 199 EM2_Eta_Sys 510 "Init" 511 "Fehler";
VAL_ 199 EM2_IstStrom 2046 "Init" 2047 "Fehler";
VAL_ 199 EM2_Fehler_ElAntriebFreilauf_Anf 0 "Init" 1 "Fehler_EM_im_Freilauf";
VAL_ 199 EM2_Abregelung_Temperatur 0 "Init" 1 "Abregelung_Temperatur";
VAL_ 199 EM2_AnlernenElMotor_Anf 0 "kein_Diagnose_Request" 1 "Diagnose_Request";
VAL_ 199 EM2_Freigabe_Verfallsinfo_WFS 0 "Aus" 1 "Ein";
VAL_ 199 EM2_Parken_WFS_Status 0 "Limitierung_Inaktiv" 1 "Limitierung_Aktiv" 2 "Abbruch";
VAL_ 199 EM2_HV_betriebsbereit 0 "Init" 1 "Ready_HV";
VAL_ 2527679713 EM2_RtmWarnKommunikation 0 "kein_Fehler" 1 "Fehler_Stufe_1" 2 "Fehler_Stufe_2" 3 "Fehler_Stufe_3" 4 "reserviert" 5 "reserviert" 6 "reserviert" 7 "reserviert";
VAL_ 2527679713 EM2_RtmWarnUeberdrehzahl 0 "kein_Fehler" 1 "Fehler_Stufe_1" 2 "Fehler_Stufe_2" 3 "Fehler_Stufe_3" 4 "reserviert" 5 "reserviert" 6 "reserviert" 7 "reserviert";
VAL_ 2527679713 EM2_RtmWarnUeberstrom 0 "kein_Fehler" 1 "Fehler_Stufe_1" 2 "Fehler_Stufe_2" 3 "Fehler_Stufe_3" 4 "reserviert" 5 "reserviert" 6 "reserviert" 7 "reserviert";
VAL_ 2527679713 EM2_RtmWarnTempEM 0 "kein_Fehler" 1 "Fehler_Stufe_1" 2 "Fehler_Stufe_2" 3 "Fehler_Stufe_3" 4 "reserviert" 5 "reserviert" 6 "reserviert" 7 "reserviert";
VAL_ 2527679713 EM2_RtmWarnTempPWR 0 "kein_Fehler" 1 "Fehler_Stufe_1" 2 "Fehler_Stufe_2" 3 "Fehler_Stufe_3" 4 "reserviert" 5 "reserviert" 6 "reserviert" 7 "reserviert";
VAL_ 2589283649 EML_ReifenKorrFaktorHL 510 "Init" 511 "Fehler";
VAL_ 2589283649 EML_ReifenKorrFaktorHR 510 "Init" 511 "Fehler";
VAL_ 2589283649 EML_ReifenKorrFaktorVL 510 "Init" 511 "Fehler";
VAL_ 2589283649 EML_ReifenKorrFaktorVR 510 "Init" 511 "Fehler";
VAL_ 2589283649 EML_QBit_Reifenumfang 0 "gueltiger_Wert" 1 "Ersatz_Init_oder_Fehlerwert";
VAL_ 608 EML_AnzeigeGeschw 1022 "Init" 1023 "Fehler";
VAL_ 2527679687 EPS_ASM_Ereignis 0 "No_Event" 255 "ASM_Trigger";
VAL_ 2527679687 EPS_ASM_Zeitstempel 255 "INIT";
VAL_ 258 ESP_QBit_Gierrate 0 "gueltiger_Wert" 1 "Ersatz_Init_oder_Fehlerwert";
VAL_ 258 ESP_QBit_Laengsbeschl 0 "gueltiger_Wert" 1 "Ersatz_Init_oder_Fehlerwert";
VAL_ 258 ESP_QBit_Querb 0 "gueltiger_Wert" 1 "Ersatz_Init_oder_Fehlerwert";
VAL_ 258 ESP_Querbeschleunigung 255 "Fehler";
VAL_ 258 ESP_Laengsbeschl 1022 "Signal_nicht_vorhanden" 1023 "Fehler";
VAL_ 258 ESC_Motorstartverzoegerung 0 "Startfreigabe" 1 "Anforderung_Startverzoegerung";
VAL_ 258 ESC_SeitenwindAssistent_Eingriff 0 "Kein_SWA_Eingriff_und_Init" 1 "SWA_Eingriff_aktiv";
VAL_ 258 ESP_Anschleppstart_Freigabe 0 "kein_Schleppstart_oder_NotSchleppstart_erlaubt" 1 "NotSchleppstart_erlaubt" 2 "Schleppstart_und_NotSchleppStart_erlaubt";
VAL_ 258 ESC_Unterdruckmangel_erkannt 0 "kein_Unterdruckmangel_erkannt" 1 "Unterdruckmangel_erkannt";
VAL_ 258 ESP_Gierrate 16383 "Fehler";
VAL_ 258 ESP_VZ_Gierrate 0 "positiv" 1 "negativ";
VAL_ 258 ESP_Notbremsanzeige 0 "keine_Notbremsung_erkannt" 1 "Notbremsung_erkannt";
VAL_ 258 ESP_SpannungsAnf 0 "keine_Anforderung" 1 "Anforderung_Spannungswert_1";
VAL_ 258 ESP_PLA_Abbruch 0 "Init" 1 "Geschwindigkeitsueberschreitung" 2 "Falscher_PLA_Status" 3 "Deaktivierung_durch_Abbruch_Lenkung" 4 "PLA_Bremsanforderung_nach_Stillstand" 5 "Abbruch_durch_Kl15_aus" 6 "Abbruch_durch_FT_offen";
VAL_ 258 ESP_Status_ESP_PLA 8 "ESP_PLA_funktionsbereit" 0 "ESP_PLA_deaktiv" 9 "ESP_PLA_Neustart" 1 "ESP_PLA_Init" 10 "ESP_PLA_Abbruch" 2 "ESP_PLA_Fehler" 4 "ESP_PLA_aktivierbar" 6 "ESP_PLA_Bremse_aktiv";
VAL_ 258 ESP_QBit_Bremsdruck 0 "gueltiger_Wert" 1 "Ersatz_Init_oder_Fehlerwert";
VAL_ 258 ESP_QBit_Fahrer_bremst 0 "gueltiger_Wert" 1 "Ersatz_Init_oder_Fehlerwert";
VAL_ 258 ESP_Schwelle_Unterdruck 0 "kein_Signal" 1 "Unterdruck_kleiner_gleich_450_mbar" 2 "Unterdruck_groesser_450_mbar" 3 "Fehler_Unterdrucksensor";
VAL_ 258 ESP_Bremsdruck 1023 "Fehler";
VAL_ 258 ESP_Fahrer_bremst 0 "Bremsdruckschwelle_nicht_ueberschritten" 1 "Bremsdruckschwelle_ueberschritten";
VAL_ 258 ESP_Verz_TSK_aktiv 0 "TSK_Verzoegerung_inaktiv" 1 "TSK_Verzoegerung_aktiv";
VAL_ 258 ESP_Lenkeingriff_ADS 0 "kein_Lenkeingriff" 1 "stabilisierender_Lenkeingriff";
VAL_ 258 ESP_Konsistenz_TSK 0 "Botschaft_fuer_Verzoegerungsanforderung_konsistent" 1 "Botschaft_fuer_Verzoegerungsanforderung_nicht_konsistent";
VAL_ 258 ESP_Bremsruck_AWV2 0 "kein_Bremsruck_ausgefuehrt" 1 "Bremsruck_ausgefuehrt";
VAL_ 258 ESP_Konsistenz_AWV2 0 "Botschaft_fuer_AWV2_konsistent" 1 "Botschaft_fuer_AWV2_nicht_konsistent";
VAL_ 258 ECD_Fehler 0 "ECD_iO" 1 "ECD_Fehler";
VAL_ 258 ECD_nicht_verfuegbar 0 "ECD_Funktion_verfuegbar" 1 "ECD_Funktion_nicht_verfuegbar";
VAL_ 258 ESP_Status_Bremsentemp 0 "Bremse_nicht_ueberhitzt" 1 "Bremse_ueberhitzt";
VAL_ 258 ESP_Autohold_Standby 0 "Autohold_nicht_im_Standby" 1 "Autohold_im_Standby";
VAL_ 258 ESP_HDC_Standby 0 "HDC_Funktion_nicht_im_Standby" 1 "HDC_Funktion_im_Standby";
VAL_ 258 ESP_HBA_aktiv 0 "HBA_nicht_aktiv" 1 "HBA_aktiv";
VAL_ 258 ESP_Prefill_ausgeloest 0 "nicht_ausgeloest" 1 "Prefill_ausgeloest";
VAL_ 258 ESP_Rueckwaertsfahrt_erkannt 0 "keine_Rueckwaetsfahrt" 1 "Rueckwaertsfahrt_sicher_erkannt";
VAL_ 258 ESP_Status_Anfahrhilfe 0 "Aus" 1 "Ein";
VAL_ 258 ESP_HDC_aktiv 0 "inaktiv" 1 "aktiv";
VAL_ 258 ESP_StartStopp_Info 0 "Motorlauf_nicht_notwendig_(Stoppfreigabe)" 1 "Motoranlauf_nicht_zwingend_notwendig_(Stoppverbot,keine_Startanforderung)" 2 "Motoranlauf_zwingend_notwendig_(Startanforderung)" 3 "Systemfehler";
VAL_ 258 ESP_Eingr_HL 0 "kein_Eingriff" 1 "ESP_Eingriff_HL";
VAL_ 258 ESP_Eingr_HR 0 "kein_Eingriff" 1 "ESP_Eingriff_HR";
VAL_ 258 ESP_Eingr_VL 0 "kein_Eingriff" 1 "ESP_Eingriff_VL";
VAL_ 258 ESP_Eingr_VR 0 "kein_Eingriff" 1 "ESP_Eingriff_VR";
VAL_ 258 ESP_BKV_Unterdruck 0 "nicht_verbaut_oder_nicht_kodiert" 254 "Init" 255 "Fehler";
VAL_ 258 ESP_Autohold_aktiv 0 "Autohold_inaktiv" 1 "Autohold_aktiv";
VAL_ 258 ESP_FStatus_Anfahrhilfe 0 "kein_Fehler" 1 "Fehler";
VAL_ 258 ESP_Verz_EPB_aktiv 0 "nicht_aktiviert" 1 "aktiviert";
VAL_ 258 ECD_Bremslicht 0 "Aus" 1 "Ein";
VAL_ 258 ESP_Verzoeg_EPB_verf 0 "nicht_verfuegbar" 1 "System_verfuegbar";
VAL_ 258 ESP_Status_Bremsdruck 0 "Bremse_drucklos" 1 "mit_Bremsdruck";
VAL_ 258 ESP_Anforderung_EPB 0 "keine_Anforderung" 1 "Anforderung_Oeffnen" 2 "Anforderung_Schliessen" 3 "reserviert";
VAL_ 258 ESP_ANB_CM_Rueckk_Umsetz 0 "keine_Ausfuehrung" 1 "Ausfuehrung";
VAL_ 258 ESP_Konsistenz_ACC_Botschaft 0 "Botschaft_fuer_ACC_konsistent" 1 "Botschaft_fuer_ACC_nicht_konsistent";
VAL_ 258 ESP_Stillstandsphase_erschoepft 0 "sicheres_Halten_moeglich" 1 "kein_sicheres_Halten_moeglich";
VAL_ 258 ESP_ZT_Rueckk_Umsetz 0 "keine_Ausfuehrung" 1 "Ausfuehrung";
VAL_ 258 ESP_Tuerkontakt_Fahrertuer 0 "Schalter_geschlossen" 1 "Schalter_offen";
VAL_ 258 ESP_Abrutschen_Stillstand 0 "kein_Abrutschen_erkannt" 1 "Abrutschen_erkannt";
VAL_ 258 ESP_Fahrer_tritt_ZBR_Schw 0 "Fahrer_uebertritt_ZBR_Schwelle_nicht" 1 "Fahrer_uebertritt_ZBR_Schwelle";
VAL_ 258 ESP_QBit_v_ref 0 "gueltiger_Wert" 1 "Ersatz_Init_oder_Fehlerwert";
VAL_ 258 ESP_v_ref_Fahrtrichtung 0 "Fahrtrichtung_nicht_definiert" 1 "Vorwaerts" 2 "Rueckwaerts" 3 "Stillstand";
VAL_ 258 ESC_Bremsdruckgradient 251 "groesser_2500_bar_per_sec" 254 "Init" 255 "Fehler";
VAL_ 258 ESP_v_ref 4093 "Unterspannung" 4094 "Init" 4095 "Fehler";
VAL_ 258 ESC_Hydr_Fkt_aktiv 0 "keine_Aktivitaet" 1 "ESC_Druckaufbau_HBx_HFC_aktiv" 2 "Warnrucklevel_Summand_1" 3 "Warnrucklevel_Summand_3";
VAL_ 258 ESC_QBit_Fahrerbremswunsch 0 "gueltiger_Wert" 1 "Ersatz_Init_oder_Fehlerwert";
VAL_ 258 ESC_Fahrerbremswunsch 1023 "Fehler";
VAL_ 258 ESCGeneratorSollMoment 4094 "Init" 4095 "Fehler";
VAL_ 258 ESC_Raddruck_max 254 "Init" 255 "Fehler";
VAL_ 258 EPB_QBit_Pedalweg_Kuppl 0 "gültiger Wert" 1 "Ersatz-, Init- oder Fehlerwert";
VAL_ 258 EPB_Freig_Verzoeg_Anf 0 "nicht freigegeben" 1 "freigegeben";
VAL_ 258 EPB_Pedalweg_Kuppl 0 "Init" 255 "Fehler";
VAL_ 258 EPB_DAA_Randbed_erf 0 "Randbed_nicht_erfuellt" 1 "Randbed_erfuellt";
VAL_ 258 EPB_Fehlerstatus_02 0 "kein_Fehler" 1 "Fehler_ausserhalb_apply_release" 2 "Fehler_einseitig_apply_release" 3 "Fehler_beidseitig_apply_release";
VAL_ 258 EPB_Schalterposition 0 "keine Fahreranforderung" 1 "Fahreranforderung Öffnen" 2 "Fahreranforderung Schließen" 3 "Fehler";
VAL_ 258 EPB_QBit_Schalterpos 0 "gültiger Wert (volle Funktion)" 1 " Ersatz-, Init- oder Fehlerwert (Schalter ausser Funktion)";
VAL_ 258 EPB_Spannkraft 30 "Init" 31 "Fehler";
VAL_ 258 EPB_Status_02 0 "offen" 1 "geschlossen_Parken" 2 "teilgespannt_Halten" 3 "im_Lauf_oeffnen" 4 "im_Lauf_schliessen" 5 "tbd" 6 "Init" 7 "unbekannt";
VAL_ 258 EPB_Status 0 "offen" 1 "Bremse_geschl_(Spannkraft_voll/reduziert)" 2 "Aktuator_im_Lauf" 3 "Fehler_oder_unbekannt";
VAL_ 258 ESP_Status_Bremsentemp_02 0 "nicht_erhoeht" 1 "Schwelle_1" 2 "Schwelle_2";
VAL_ 252 ESC_aktBr_Modus 0 "Aktivbremsung_Aus" 1 "Aktivbremsung_Volumenkompensation" 2 "Aktivbremsung_Aktiv" 3 "Aktivbremsung_Runout";
VAL_ 252 ESC_Blending_Solldruck 1022 "Init" 1023 "Fehler";
VAL_ 252 ESC_EBKV_Kraftblending_Modus 0 "Inactive" 1 "Hold" 2 "Active";
VAL_ 252 ESC_Bremsdruck_Modell 1022 "Init" 1023 "Fehler";
VAL_ 252 ESC_Bremsdruck_02 1023 "Fehler";
VAL_ 252 ESC_QBit_Bremsdruck_02 0 "gueltiger_Wert" 1 "Ersatz_Init_oder_Fehlerwert";
VAL_ 252 ESP_HL_Radgeschw_02 65533 "Unterspannung" 65534 "Init" 65535 "Fehler";
VAL_ 252 ESP_HR_Radgeschw_02 65533 "Unterspannung" 65534 "Init" 65535 "Fehler";
VAL_ 252 ESP_VL_Radgeschw_02 65533 "Unterspannung" 65534 "Init" 65535 "Fehler";
VAL_ 252 ESP_VR_Radgeschw_02 65533 "Unterspannung" 65534 "Init" 65535 "Fehler";
VAL_ 252 ESP_FZR_uebersteuern 254 "Init" 255 "Fehler";
VAL_ 252 ESP_FZR_untersteuern 254 "Init" 255 "Fehler";
VAL_ 252 ESC_Anf_Mindestreku 0 "nicht_angefordert" 1 "angefordert";
VAL_ 252 ESC_GMV_aktiv 0 "keine_Aktivitaet" 1 "Aktivitaet_durch_AWA";
VAL_ 252 ESC_GMV_nicht_verfuegbar 0 "verfuegbar" 1 "nicht_verfuegbar";
VAL_ 252 ESC_Status_vRef_Stuetzeingriff 0 "kein_Eingriff" 1 "Stuetzungseingriff";
VAL_ 252 FDR_Allradverteilung_aktiv 0 "kein_Eingriff" 1 "Allradeingriff_aktiv";
VAL_ 252 FDR_Anf_Allradbetrieb 0 "keine_Anforderung" 1 "Kraftschluss_an_beiden_Achsen_herstellen";
VAL_ 252 ESP_HL_Bremsmoment 254 "Init" 255 "Fehler";
VAL_ 252 ESP_HR_Bremsmoment 254 "Init" 255 "Fehler";
VAL_ 252 ESP_VR_Bremsmoment 254 "Init" 255 "Fehler";
VAL_ 252 ESP_VL_Bremsmoment 254 "Init" 255 "Fehler";
VAL_ 252 ESP_FDR_uebersteuern 254 "Init" 255 "Fehler";
VAL_ 252 ESP_FDR_untersteuern 254 "Init" 255 "Fehler";
VAL_ 252 TSMomBegrenzung 4094 "Init" 4095 "Fehler";
VAL_ 252 ESC_Allrad_Anteil_max_sek 510 "Init" 511 "Fehler";
VAL_ 252 ESC_Allrad_Anteil_min_sek 510 "Init" 511 "Fehler";
VAL_ 252 ESC_Status_Eingriff 0 "kein Eingriff" 1 "ASR-Eingriff" 2 "MSR-Eingriff" 3 "nicht belegt ";
VAL_ 252 ESC_Status_Eingriff_sek 0 "kein Eingriff" 1 "ASR-Eingriff" 2 "MSR-Eingriff" 3 "nicht belegt ";
VAL_ 252 ESC_MomRad_Eingriff 8190 "Init" 8191 "Fehler";
VAL_ 252 ESC_MomRad_Eingriff_sek 8190 "Init" 8191 "Fehler";
VAL_ 252 ESC_Achsdrehzahl_Max 16382 "Init" 16383 "Fehler";
VAL_ 252 ESC_Achsdrehzahl_Min 16382 "Init" 16383 "Fehler";
VAL_ 252 ESC_Achsdrehzahl_Max_sek 16382 "Init" 16383 "Fehler";
VAL_ 252 ESC_Achsdrehzahl_Min_sek 16382 "Init" 16383 "Fehler";
VAL_ 2463978647 ESP_ACC_LDE 0 "Lebensdauerende_nicht_erreicht" 1 "Lebensdauerende_erreicht";
VAL_ 2463978647 ESP_Allrad_Antrieb 0 "Front" 1 "Allrad";
VAL_ 2463978647 ESP_Codierung_ADS 0 "Init" 1 "ESP_nicht_ADS_codiert" 2 "ADS_codiert" 3 "tbd";
VAL_ 2463978647 ESP_RTA_HL 254 "Abgleich_nocht_nicht_genuegend_konvergent" 255 "Fehler";
VAL_ 2463978647 ESP_RTA_HR 254 "Abgleich_nocht_nicht_genuegend_konvergent" 255 "Fehler";
VAL_ 2463978647 ESP_RTA_VR 254 "Abgleich_nocht_nicht_genuegend_konvergent" 255 "Fehler";
VAL_ 2463978647 OBD_Fehler_Radsensor_HL 0 "kein Fehler / Init / nicht verbaut" 1 "KS- (Kurzschluss nach minus)" 2 "KS+ (Kurzschluss nach plus)" 3 "OC (Leitungsunterbrechung)" 4 "OOR+ (Signal zu gross)" 5 "OOR- (Signal zu klein)" 6 "RC+ (Signal unplausibel zu gross)" 7 "RC- (Signal unplausibel zu klein)" 8 "KS+/OC (Kurzschluss nach plus/Unterbrechung)" 9 "KS-/OC  (Kurzschluss nach minus/Unterbrechung)" 10 "KS-/KS+  (Kurzschluss nach minus/plus)" 11 "KS-/KS+/OC (Kurzschluss nach minus/plus/Unterbrechung)" 12 "frei" 13 "frei" 14 "frei" 15 "frei";
VAL_ 2463978647 OBD_Fehler_Radsensor_HR 0 "kein Fehler / Init / nicht verbaut" 1 "KS- (Kurzschluss nach minus)" 2 "KS+ (Kurzschluss nach plus)" 3 "OC (Leitungsunterbrechung)" 4 "OOR+ (Signal zu gross)" 5 "OOR- (Signal zu klein)" 6 "RC+ (Signal unplausibel zu gross)" 7 "RC- (Signal unplausibel zu klein)" 8 "KS+/OC (Kurzschluss nach plus/Unterbrechung)" 9 "KS-/OC  (Kurzschluss nach minus/Unterbrechung)" 10 "KS-/KS+  (Kurzschluss nach minus/plus)" 11 "KS-/KS+/OC (Kurzschluss nach minus/plus/Unterbrechung)" 12 "frei" 13 "frei" 14 "frei" 15 "frei";
VAL_ 2463978647 OBD_Fehler_Radsensor_VL 0 "kein Fehler / Init / nicht verbaut" 1 "KS- (Kurzschluss nach minus)" 2 "KS+ (Kurzschluss nach plus)" 3 "OC (Leitungsunterbrechung)" 4 "OOR+ (Signal zu gross)" 5 "OOR- (Signal zu klein)" 6 "RC+ (Signal unplausibel zu gross)" 7 "RC- (Signal unplausibel zu klein)" 8 "KS+/OC (Kurzschluss nach plus/Unterbrechung)" 9 "KS-/OC  (Kurzschluss nach minus/Unterbrechung)" 10 "KS-/KS+  (Kurzschluss nach minus/plus)" 11 "KS-/KS+/OC (Kurzschluss nach minus/plus/Unterbrechung)" 12 "frei" 13 "frei" 14 "frei" 15 "frei";
VAL_ 2463978647 OBD_Fehler_Radsensor_VR 0 "kein Fehler / Init / nicht verbaut" 1 "KS- (Kurzschluss nach minus)" 2 "KS+ (Kurzschluss nach plus)" 3 "OC (Leitungsunterbrechung)" 4 "OOR+ (Signal zu gross)" 5 "OOR- (Signal zu klein)" 6 "RC+ (Signal unplausibel zu gross)" 7 "RC- (Signal unplausibel zu klein)" 8 "KS+/OC (Kurzschluss nach plus/Unterbrechung)" 9 "KS-/OC  (Kurzschluss nach minus/Unterbrechung)" 10 "KS-/KS+  (Kurzschluss nach minus/plus)" 11 "KS-/KS+/OC (Kurzschluss nach minus/plus/Unterbrechung)" 12 "frei" 13 "frei" 14 "frei" 15 "frei";
VAL_ 2463978647 ESP_Qualifizierung_Antriebsart 0 "alte_Bedeutung_Bit_ESP_Allrad_Antrieb" 1 "neue_Bedeutung_Bit_ESP_Allrad_Antrieb";
VAL_ 2463978647 ESP_Offroad_Modus 0 "kein_ESP_Offroadmodus" 1 "ESP_Offroadmodus";
VAL_ 2463978647 ESP_MKB_ausloesbar 0 "Multikollisionsbremsung_nicht_freigeschaltet" 1 "Multikollisionsbremsung_freigeschaltet";
VAL_ 2463978647 ESP_Stat_FallBack_eBKV 0 "Rueckfallebene_nicht_vorhanden" 1 "Rueckfallebene_vorhanden";
VAL_ 2463978647 ESP_CM_Variante 0 "Standard" 1 "Erweitert";
VAL_ 2463978647 ESP_OBD_Status 0 "MIL_aus" 1 "MIL_ein";
VAL_ 2463978647 ESP_Rollenmodus_Deaktivieren 0 "keine_Aenderung" 1 "Abbruch";
VAL_ 2463978647 ESP_nachtr_Stopp_Anf 0 "nicht_angefordert" 1 "angefordert";
VAL_ 2527679683 ESC_ASM_Ereignis 0 "No_Event" 255 "ASM_Trigger";
VAL_ 2527679683 ESC_ASM_Zeitstempel 255 "Init";
VAL_ 278 ESP_QBit_Wegimpuls_VL 0 "gueltiger_Wert" 1 "Ersatz_Init_oder_Fehlerwert";
VAL_ 278 ESP_QBit_Wegimpuls_VR 0 "gueltiger_Wert" 1 "Ersatz_Init_oder_Fehlerwert";
VAL_ 278 ESP_QBit_Wegimpuls_HL 0 "gueltiger_Wert" 1 "Ersatz_Init_oder_Fehlerwert";
VAL_ 278 ESP_QBit_Wegimpuls_HR 0 "gueltiger_Wert" 1 "Ersatz_Init_oder_Fehlerwert";
VAL_ 278 ESP_Wegimpuls_VL 1021 "Init" 1022 "Unterspannung" 1023 "Fehler";
VAL_ 278 ESP_Wegimpuls_VR 1021 "Init" 1022 "Unterspannung" 1023 "Fehler";
VAL_ 278 ESP_Wegimpuls_HL 1021 "Init" 1022 "Unterspannung" 1023 "Fehler";
VAL_ 278 ESP_Wegimpuls_HR 1021 "Init" 1022 "Unterspannung" 1023 "Fehler";
VAL_ 278 ESP_VL_Fahrtrichtung 0 "Vorwaerts" 1 "Rueckwaerts" 2 "Init" 3 "ungueltig_oder_nicht_verbaut";
VAL_ 278 ESP_VR_Fahrtrichtung 0 "Vorwaerts" 1 "Rueckwaerts" 2 "Init" 3 "ungueltig_oder_nicht_verbaut";
VAL_ 278 ESP_HL_Fahrtrichtung 0 "Vorwaerts" 1 "Rueckwaerts" 2 "Init" 3 "ungueltig_oder_nicht_verbaut";
VAL_ 278 ESP_HR_Fahrtrichtung 0 "Vorwaerts" 1 "Rueckwaerts" 2 "Init" 3 "ungueltig_oder_nicht_verbaut";
VAL_ 1629 BR_Systemart 0 "ABS" 1 "ABS_ASR" 2 "ESP" 3 "ESP_mit_integrierter_EPB";
VAL_ 1629 ESP_SpannungsAnf_02 0 "keine_Anforderung" 1 "Anforderung_Stufe1" 2 "Anforderung_Stufe2" 3 "Anforderung_Stufe3";
VAL_ 1629 ESP_Charisma_FahrPr 0 "keine_Funktion" 1 "Programm_1" 2 "Programm_2" 3 "Programm_3" 4 "Programm_4" 5 "Programm_5" 6 "Programm_6" 7 "Programm_7" 8 "Programm_8" 9 "Programm_9" 10 "Programm_10" 11 "Programm_11" 12 "Programm_12" 13 "Programm_13" 14 "Programm_14" 15 "Programm_15";
VAL_ 1629 ESP_Charisma_Status 0 "Init" 1 "verfuegbar" 2 "nicht_verfuegbar" 3 "asynchron_durch_Fahrerwunsch";
VAL_ 1629 ESP_Wiederstart_Anz_01 0 "keine_Anzeige" 1 "Rueckwaertsrollen";
VAL_ 1629 ESP_Wiederstart_Anz_02 0 "keine_Anzeige" 1 "Autohold_Rutschen";
VAL_ 1629 ESP_Wiederstart_Anz_03 0 "keine_Anzeige" 1 "Offroad_HDC";
VAL_ 1629 ESP_Wiederstart_Anz_04 0 "keine_Anzeige" 1 "ESC_Off";
VAL_ 1629 ESP_Stoppverbot_Anz_01 0 "keine_Anzeige" 1 "Notbremsung_aktiv";
VAL_ 1629 ESP_Stoppverbot_Anz_02 0 "keine_Anzeige" 1 "Autohold_AVH_Rutschen";
VAL_ 1629 ESP_Stoppverbot_Anz_03 0 "keine_Anzeige" 1 "Rueckwaertsrollen";
VAL_ 1629 ESP_Stoppverbot_Anz_04 0 "keine_Anzeige" 1 "ESP_Pumpenlauf";
VAL_ 1629 ESP_Stoppverbot_Anz_05 0 "keine_Anzeige" 1 "ESP_OFF";
VAL_ 1629 ESP_Stoppverbot_Anz_06 0 "keine_Anzeige" 1 "Offroad_HDC";
VAL_ 1629 ESP_Stoppverbot_Anz_07 0 "keine_Anzeige" 1 "ESP_Haltefunktion_nicht_verfuegbar";
VAL_ 1629 ESP_Stoppverbot_Anz_Std 0 "keine_Anzeige" 1 "Standard_Stoppvetogrund";
VAL_ 1629 ESP_Dachrelingsensor 0 "Sensor_nicht_verbaut" 1 "Quertraeger_montiert" 2 "Quertraeger_nicht_montiert" 3 "Fehler";
VAL_ 1629 ESP_Stoppverbot_Anz_08 0 "keine_Anzeige" 1 "Neigungsbegrenzung";
VAL_ 1629 HDC_Charisma_FahrPr 0 "keine_Funktion" 1 "Programm_1" 2 "Programm_2" 3 "Programm_3" 4 "Programm_4" 5 "Programm_5" 6 "Programm_6" 7 "Programm_7" 8 "Programm_8" 9 "Programm_9" 10 "Programm_10" 11 "Programm_11" 12 "Programm_12" 13 "Programm_13" 14 "Programm_14" 15 "Programm_15";
VAL_ 1629 HDC_Charisma_Status 0 "Init" 1 "verfuegbar" 2 "nicht_verfuegbar" 3 "asynchron_durch_Fahrerwunsch";
VAL_ 1629 BR_QBit_Reifenumfang 0 "gueltiger_Wert" 1 "Ersatz_Init_oder_Fehlerwert";
VAL_ 253 BR_Eingriffsmoment 1022 "Init" 1023 "Fehler";
VAL_ 253 ESP_PLA_Bremseingriff 0 "inaktiv" 1 "aktiv";
VAL_ 253 ESP_Diagnose 0 "ESP_nicht_in_Diagnose" 1 "ESP_in_Diagnose";
VAL_ 253 ESC_Reku_Freigabe 0 "keine_Freigabe_der_Rekuperation" 1 "Freigabe_der_Rekuperation";
VAL_ 253 ESC_v_Signal_Qualifier_High_Low 0 "Gueteschwelle_kleiner_1kmh" 1 "Gueteschwelle_kleiner_3kmh" 2 "Gueteschwelle_kleiner_5kmh" 3 "Gueteschwelle_kleiner_10kmh" 4 "Gueteschwelle_kleiner_20kmh" 5 "Gueteschwelle_groessergleich_20kmh" 6 "Init" 7 "Fehler";
VAL_ 253 ESP_Vorsteuerung 0 "keine_Vorsteuerung_aktiv" 1 "Vorsteuerung_aktiv";
VAL_ 253 ESP_AWV3_Brems_aktiv 0 "inaktiv" 1 "aktiv";
VAL_ 253 OBD_Schlechtweg 0 "kein_Schlechtweg_erkannt" 1 "Schlechtweg_erkannt";
VAL_ 253 OBD_QBit_Schlechtweg 0 "gueltiger_Wert" 1 "Ersatz_Init_oder_Fehlerwert";
VAL_ 253 ESP_v_Signal 65533 "Unterspannung" 65534 "Init" 65535 "Fehler";
VAL_ 253 ASR_Tastung_passiv 0 "ASR_aktiviert" 1 "ASR_passiv_getastet_oder_Schwellen_geaendert";
VAL_ 253 ESP_Tastung_passiv 0 "ESP_aktiviert" 1 "ESP_passiv_getastet_oder_Schwellen_geaendert";
VAL_ 253 ESP_Systemstatus 0 "iO" 1 "Fehler";
VAL_ 253 ASR_Schalteingriff 0 "keine_Anforderung" 1 "ASR_Schaltkennfeld" 2 "Rueckschaltung" 3 "Schaltverbot";
VAL_ 253 ESP_Haltebestaetigung 0 "kein_sicheres_Halten" 1 "sicheres_Halten";
VAL_ 253 ESP_MKB_Abbruch_Geschw 0 "MKB_nicht_beendet_wg_v_Schwelle" 1 "MKB_beendet_wg_v_Schwelle";
VAL_ 253 ESP_QBit_v_Signal 0 "gueltiger_Wert" 1 "Ersatz_Init_oder_Fehlerwert";
VAL_ 253 ABS_Bremsung 0 "keine_ABS_Regelung" 1 "ABS_Regelung_aktiv";
VAL_ 253 ASR_Anf 0 "keine_Anforderung" 1 "ASR_Anforderung";
VAL_ 253 MSR_Anf 0 "keine Anfoderung" 1 "MSR-Anforderung";
VAL_ 253 EBV_Eingriff 0 "kein_EBV_Eingriff" 1 "EBV_Eingriff";
VAL_ 253 EDS_Eingriff 0 "kein_EDS_Eingriff" 1 "EDS_Eingriff";
VAL_ 253 ESP_Eingriff 0 "kein_ESP_Eingriff" 1 "ESP_Eingriff_aktiv";
VAL_ 253 ESP_ASP 0 "inaktiv" 1 "aktiv";
VAL_ 253 ESP_Anhaltevorgang_ACC_aktiv 0 "inaktiv" 1 "aktiv";
VAL_ 795 ESP_Lampe 0 "Aus" 1 "Ein";
VAL_ 795 ABS_Lampe 0 "Aus" 1 "Ein";
VAL_ 795 BK_Lampe_02 0 "aus" 1 "ein_statisch" 3 "Warnung";
VAL_ 795 TC_Lampe 0 "Aus" 1 "Ein";
VAL_ 795 ESP_m_Raddrehz 32765 "Unterspannung" 32766 "Init" 32767 "Fehler";
VAL_ 795 ESP_Textanzeigen_03 0 "kein_Text" 1 "ESP_Stoerung" 2 "ABS_Stoerung" 3 "ESP_ABS_Stoerung" 4 "Werkstatt_Bremse" 5 "ASR_Stoerung" 6 "ESP_switched_off" 7 "ASR_off" 8 "ESP_ASR_on" 10 "keine_Bremskraftverstaerkung" 11 "ASR_aktiviert" 12 "ABS_ASR_Stoerung" 15 "ESP_offroad" 17 "ESP_sport" 18 "ESP_Zwangsaktivierung" 19 "ESP_Taster_Info" 20 "TC_aktiv" 21 "reserviert_fuer_Verlwarn" 22 "TC_switched_off" 23 "Verlwarn_akt_Rollsicher_inakt" 24 "ESP_SuperSport" 25 "ESP_Offroad_nicht_verfuegbar";
VAL_ 795 ESP_Meldungen 0 "keine_Anzeige" 1 "Autohold_Hinweis_1" 2 "Stoerung_Autohold" 3 "Stoerung_Hillholder" 4 "Uebernehmen" 5 "Autohold_aus" 6 "Autohold_Hinweis_2";
VAL_ 795 ESP_Fehlerstatus_Wegimp 0 "Wegimpulse_iO" 1 "Fehler";
VAL_ 795 ESP_Wegimp_Ueberlauf 0 "Reset_und_kein_Ueberlauf" 1 "mindestens_1x_Ueberlauf";
VAL_ 795 ESP_QBit_Wegimp_VA 0 "gueltiger_Wert" 1 "Ersatz_Init_oder_Fehlerwert";
VAL_ 795 ESP_HDC_FktLampe 0 "Aus" 1 "Ein";
VAL_ 795 ESP_Off_Lampe 0 "Lampe_aus" 1 "Lampe_ein";
VAL_ 795 ESP_HDC_Regelgeschw 0 "nicht_verbaut" 125 "HDC_Standby" 126 "Init" 127 "Fehler";
VAL_ 795 ESP_BKV_Warnung 0 "keine_Anzeige" 1 "keine_Bremskraftverstaerkung";
VAL_ 2589283617 EDS_Charisma_FahrPr 0 "keine_Funktion" 1 "Programm_1" 2 "Programm_2" 3 "Programm_3" 4 "Programm_4" 5 "Programm_5" 6 "Programm_6" 7 "Programm_7" 8 "Programm_8" 9 "Programm_9" 10 "Programm_10" 11 "Programm_11" 12 "Programm_12" 13 "Programm_13" 14 "Programm_14" 15 "Programm_15";
VAL_ 2589283617 EDS_Charisma_Status 0 "Init" 1 "verfuegbar" 2 "nicht_verfuegbar" 3 "asynchron_durch_Fahrerwunsch";
VAL_ 2589283617 HHC_Charisma_Status 0 "Init" 1 "verfuegbar" 2 "nicht_verfuegbar" 3 "asynchron_durch_Fahrerwunsch";
VAL_ 2589283617 HHC_Charisma_FahrPr 0 "keine_Funktion" 1 "Programm_1" 2 "Programm_2" 3 "Programm_3" 4 "Programm_4" 5 "Programm_5" 6 "Programm_6" 7 "Programm_7" 8 "Programm_8" 9 "Programm_9" 10 "Programm_10" 11 "Programm_11" 12 "Programm_12" 13 "Programm_13" 14 "Programm_14" 15 "Programm_15";
VAL_ 2589283617 RLE_Anzeigen 0 "keine_Anzeige" 1 "Rad_lose_allgemein" 2 "Rad_VL_lose" 3 "Rad_VR_lose" 4 "Rad_HL_lose" 5 "Rad_HR_lose" 6 "RLE_Pruefphase" 7 "RLE_Systemstoerung";
VAL_ 2589283617 ESC_Lernfreigabe_Abrollumfang 0 "keine_Lernfreigabe" 1 "Lernfreigabe";
VAL_ 2589283617 ESC_Texte_eBKV_Betaetigung 0 "keine_Anzeige" 1 "Halten_ueber_Schaltwippen_aktiv" 2 "Beide_Schaltwippen_betaetigen" 3 "Abbr_Halten_ueber_Schaltwippen" 4 "Bremspedal_betaetigen" 5 "Fahrpedal_loesen_Bremse_treten";
VAL_ 2589283617 ESC_MBK_Meldungen 0 "kein_Text" 1 "MBK_Hinweis_aktiv" 2 "MBK_Eskalation1_aktiv";
VAL_ 2589283617 ESC_Anf_KV 0 "kein_Oeffnen" 1 "Oeffnen";
VAL_ 2589283617 ESC_FBA_Meldungen 0 "kein_Text" 1 "FBA_Warnung_aktiv_MT" 2 "FBA_Warnung_aktiv_AT";
VAL_ 2589283617 DBK_Fahrerwarnung 0 "kein_Anfordern" 1 "Warnung_Aufforderung_Anhalten" 2 "Warnung_Aufforderung_Werkstatt" 3 "nicht_belegt";
VAL_ 2527679668 eTM_Ventil1_Status 0 "Ventil_nicht_angesteuert" 1 "Ventil_angesteuert" 5 "Ventil_nicht_verbaut" 6 "Init" 7 "Fehler";
VAL_ 2527679668 eTM_Ventil2_Status 0 "Ventil_nicht_angesteuert" 1 "Ventil_angesteuert" 5 "Ventil_nicht_verbaut" 6 "Init" 7 "Fehler";
VAL_ 2527679668 eTM_Ventil3_Status 0 "Ventil_nicht_angesteuert" 1 "Ventil_angesteuert" 5 "Ventil_nicht_verbaut" 6 "Init" 7 "Fehler";
VAL_ 2527679668 eTM_Pumpe3_Status 14 "Init" 15 "Fehler";
VAL_ 2527679668 eTM_BMS_Pumpe1_SollAnsteuerung 14 "Init" 15 "Fehler";
VAL_ 2527679668 eTM_Pumpe2_Volumenstrom 62 "Init" 63 "Fehler";
VAL_ 2527679668 eTM_BMS_Ventil2_Befuellung 0 "false" 1 "true";
VAL_ 2527679668 eTM_Pumpe1_Volumenstrom 62 "Init" 63 "Fehler";
VAL_ 2527679668 eTM_BMS_Pumpe1_Befuellung 0 "false" 1 "true";
VAL_ 2527679668 eTM_BMS_Ventil1_Befuellung 0 "false" 1 "true";
VAL_ 2527679668 eTM_Pumpe1_Status 14 "Init" 15 "Fehler";
VAL_ 2527679668 eTM_Pumpe2_Status 14 "Init" 15 "Fehler";
VAL_ 2527679668 eTM_Temperatur_1 254 "Init" 255 "Fehler";
VAL_ 2527679668 eTM_Temperatur_2 254 "Init" 255 "Fehler";
VAL_ 2527679740 KBI_aktive_Laengsfunktion_02 0 "Init" 1 "Speedlimiter" 2 "GRA_oder_ACC" 3 "PACCh" 4 "HDC" 5 "p_GRA" 6 "p_Lim" 7 "ACC_im_GRA_Modus";
VAL_ 2527679740 KBI_Anzeigestatus_GRA 0 "nicht_vorhanden" 1 "Anzeigemoeglichkeit_vorhanden" 2 "reserviert" 3 "Fehler";
VAL_ 2527679740 KBI_Anzeigestatus_LIM 0 "nicht_vorhanden" 1 "Anzeigemoeglichkeit_vorhanden" 2 "reserviert" 3 "Fehler";
VAL_ 2527679740 KBI_Anzeigestatus_ACC 0 "keine_ACC_Anzeige" 1 "ACC_Anzeige_aktiv";
VAL_ 2527679740 KBI_Konsistenz_ACC 0 "ACC Botschaft konsistent" 1 "ACC Botschaft inkonsistent";
VAL_ 2527679740 KBI_Fehler_Anzeige_ACC 0 " iO" 1 "Anzeigefehler ACC";
VAL_ 2589283684 GRA_FoD_Status 0 "Init" 1 "Funktion_inaktiv" 2 "Funktion_aktiv";
VAL_ 2589283684 FoD_Transmission_Info 0 "Initwert" 1 "start_transmission" 2 "finish_transmission";
VAL_ 987 BCM_01_alt 0 "aktuell" 1 "veraltet";
VAL_ 987 SMLS_01_alt 0 "aktuell" 1 "veraltet";
VAL_ 987 ZV_02_alt 0 "aktuell" 1 "veraltet";
VAL_ 987 Wischer_01_alt 0 "aktuell" 1 "veraltet";
VAL_ 987 Anhaenger_01_alt 0 "aktuell" 1 "veraltet";
VAL_ 987 Klima_Sensor_02_alt 0 "aktuell" 1 "veraltet";
VAL_ 987 Verdeck_01_alt 0 "aktuell" 1 "veraltet";
VAL_ 987 Klima_11_alt 0 "aktuell" 1 "veraltet";
VAL_ 987 WFS_01_alt 0 "aktuell" 1 "veraltet";
VAL_ 987 Licht_Anf_01_alt 0 "aktuell" 1 "veraltet";
VAL_ 987 ZV_verriegelt_extern_soll 1 "Fahrzeug verriegelt extern; Sollzusstand";
VAL_ 987 BH_Lichthupe 0 "nicht_betaetigt" 1 "Blinkerhebel in Richtung Lichthupe betaetigt";
VAL_ 987 WFS_Klemmenfreigabe 0 "keine_Freigabe" 1 "Freigabe";
VAL_ 987 ZV_Tankklappe_offen 0 "Tankklappe_geschlossen" 1 "Tankklappe_offen";
VAL_ 987 AAG_Anhaenger_abgesteckt 1 "Anhaenger_wurde_bei_KL15_aus_abgesteckt";
VAL_ 987 BCM1_LDS_Stellung 0 "Init" 1 "Stellung_0" 2 "Auto" 3 "Standlicht" 4 "Abblendlicht" 7 "Fehler";
VAL_ 987 VS_VD_entriegelt 1 "Zustand des Verdeck entriegelt";
VAL_ 987 ZV_HFS_offen 0 "geschlossen" 1 "offen";
VAL_ 987 ZV_HBFS_offen 0 "geschlossen" 1 "offen";
VAL_ 987 VS_VD_offen_ver 0 "Init" 1 "Verdeck_verriegelt_und_offen";
VAL_ 987 VS_VD_zu_ver 1 "Zustand des Verdecks verriegelt und geschlossen";
VAL_ 987 ZV_BT_offen 1 "BT_geoeffnet";
VAL_ 987 BCM1_Rueckfahrlicht_Schalter 0 "nicht_betaetigt" 1 "betaetigt";
VAL_ 987 ZV_FT_offen 1 "FT_geoeffnet";
VAL_ 987 Wischer_vorne_aktiv 1 "Wischer vorne läuft";
VAL_ 987 AAG_Anhaenger_erkannt 0 "kein_Anhaenger_erkannt" 1 "AAG_Anhaenger_erkannt";
VAL_ 987 BCM1_MH_Schalter 0 "MH_geschlossen" 1 "MH_offen";
VAL_ 987 ZV_HD_offen 1 "Heckdeckel_auf";
VAL_ 987 Waschen_vorne_aktiv 1 "Waschen aktiv";
VAL_ 987 KL_Thermomanagement 0 "keine_Freigabe_TMM__max_Heizbedarf" 1 "kleine_Freigabe_TMM" 2 "mittlere_Freigabe_TMM" 3 "volle_Freigabe_TMM__kein_Heizbedarf";
VAL_ 987 WFS_Schluessel_Fahrberecht 0 "kein authorisierter Schluessel erkannt" 1 "aktive_Funkschluessel_Nr_01" 2 "aktive_Funkschluessel_Nr_02" 3 "aktive_Funkschluessel_Nr_03" 4 "aktive_Funkschluessel_Nr_04" 5 "aktive_Funkschluessel_Nr_05" 6 "aktive_Funkschluessel_Nr_06" 7 "aktive_Funkschluessel_Nr_07" 8 "aktive_Funkschluessel_Nr_08" 9 "ungueltig_09" 10 "ungueltig_10" 11 "ungueltig_11" 12 "ungueltig_12" 13 "ungueltig_13" 14 "ungueltig_14" 15 "digitaler_Schluessel_aktiv";
VAL_ 987 BCM_Rueckfahrlicht_Anf 0 "Licht_nicht_angefordert" 1 "Licht_angefordert";
VAL_ 987 WWSs_01_alt 0 "aktuell" 1 "veraltet";
VAL_ 987 BCM_Tankklappensteller_Fehler 0 "kein_Fehler" 1 "Fehler";
VAL_ 987 AAG_LED_aktiv 0 "Lampen" 1 "LED";
VAL_ 987 ZV_verriegelt_soll 0 "Init" 1 "nicht_verriegelt" 2 "verriegelt";
VAL_ 987 ZV_Schluessel_Zugang 0 "kein authorisierter Schluessel erkannt " 1 "aktive_Funkschluessel_Nr_01" 2 "aktive_Funkschluessel_Nr_02" 3 "aktive_Funkschluessel_Nr_03" 4 "aktive_Funkschluessel_Nr_04" 5 "aktive_Funkschluessel_Nr_05" 6 "aktive_Funkschluessel_Nr_06" 7 "aktive_Funkschluessel_Nr_07" 8 "aktive_Funkschluessel_Nr_08" 9 "ungueltig_09" 10 "ungueltig_10" 11 "ungueltig_11" 12 "ungueltig_12" 13 "ungueltig_13" 14 "ungueltig_14" 15 "ungueltig_15";
VAL_ 987 WFS_ID_Geb_autorisiert_in_Kl15 0 "nicht_authorisiert_in_Kl15" 1 "authorisiert_in_Kl15";
VAL_ 987 BH_Fernlicht 0 "nicht_betaetigt" 1 "Blinkerhebel_in_Richtung_Fernlicht_betaetigt";
VAL_ 987 BH_Blinker_li 0 "nicht_betaetigt" 1 "Blinkerhebel_Richtung_links_betaetigt";
VAL_ 987 BH_Blinker_re 0 "nicht_betaetigt" 1 "Blinkerhebel_Richtung_rechts_betaetigt";
VAL_ 987 BCM1_OBD_FStatus_ATemp 0 "kein Fehler / Init / nicht verbaut" 1 "KS- (Kurzschluss nach minus)" 2 "KS+ (Kurzschluss nach plus)" 3 "OC (Leitungsunterbrechung)" 4 "OOR+ (Signal zu gross)" 5 "OOR- (Signal zu klein)" 6 "RC+ (Signal unplausibel zu gross)" 7 "RC- (Signal unplausibel zu klein)" 8 "KS+/OC (Kurzschluss nach plus/Unterbrechung)" 9 "KS-/OC  (Kurzschluss nach minus/Unterbrechung)" 10 "KS-/KS+  (Kurzschluss nach minus/plus)" 11 "KS-/KS+/OC (Kurzschluss nach minus/plus/Unterbrechung)" 12 "frei" 13 "frei" 14 "frei" 15 "frei";
VAL_ 987 BCM1_Aussen_Temp_ungef 253 "nicht_verbaut" 254 "Initwert" 255 "Fehler";
VAL_ 173 GE_MMom_Soll_02 1022 "keine_Anforderung_Init" 1023 "Fehler";
VAL_ 173 GE_MMom_Vorhalt_02 1022 "Init" 1023 "Fehler";
VAL_ 173 GE_Uefkt 1023 "Fehler";
VAL_ 173 GE_Fahrstufe 8 "Position_D" 0 "Zwischenstellung" 9 "Position_S" 1 "Init" 5 "Position_P" 6 "Position_R" 7 "Position_N" 10 "Effizienz" 13 "Tipp_in_S" 14 "Tipp_in_D" 15 "Fehler";
VAL_ 173 GE_Schaltablauf 0 "keine_Schaltung" 1 "Momentenueberschneidung" 2 "Befuellphase" 3 "Drehzahlueberfuehrung";
VAL_ 173 GE_Uefkt_unplausibel 0 "Uefkt_plausibel" 1 "Uefkt_unplausibel";
VAL_ 173 GE_MMom_Status_02 0 "kein_Eingriff" 1 "abs_reduzierender_Eingriff_auf_Gesamt_Antrieb_nur_schneller_Pfad" 2 "abs_erhoehender_Eingriff_auf_Gesamt_Antrieb" 3 "relativer_Eingriff_auf_Gesamt_Antrieb" 4 "relativer_Eingriff_auf_E_Maschine" 5 "abs_red_Eingr_auf_Gesamt_Antrieb_nur_Luftpfad" 6 "abs_red_Eingr_auf_Gesamt_Antrieb_Luft-_und_schnellen_Pfad" 7 "abs_Eingriff_auf_Gesamtantrieb_erhoehend_und_reduzierend";
VAL_ 173 GE_Status_Kraftschluss 0 "offen_kein_Kraftschluss" 1 "offen_mit_Kraftschluss" 2 "schlupfend_geregelt" 3 "abgesichert_offen_kein_Kraftschl" 4 "geschlossen_mit_Mikroschlupf" 5 "geschlossen_mit_Ueberanpressung" 6 "sonstige_Fehler" 7 "fehlerhaft_geschlossen";
VAL_ 173 GE_MMom_Status 0 "keine Anforderung" 1 "reduzierender Getriebeeingriff" 2 "erhöhender Getriebeeingriff" 3 "Änderung mit Sprung";
VAL_ 173 GE_Freig_MMom_Vorhalt 0 "nicht_freigegeben" 1 "freigegeben";
VAL_ 173 GE_Verbot_Ausblendung 0 "kein_Verbot" 1 "Verbot";
VAL_ 173 GE_Zielgang 0 "Gang P/N (ausgekuppelt)" 1 "Gang 1" 2 "Gang 2" 3 "Gang 3" 4 "Gang 4" 5 "Gang 5" 6 "Gang 6" 7 "Gang 7" 8 "Gang R" 11 "Gang 8" 12 "Gang 9" 13 "Gang10" 14 "Istgang nicht definiert" 15 "Fehler";
VAL_ 324 GE_Ausleuchtung_Fahrstufe 8 "P" 0 "Init" 5 "D" 6 "N" 7 "R" 10 "Tipp_Plus" 11 "Tipp_Minus" 12 "S" 13 "Kurz_Manuell_Programm" 14 "Tipp_Gasse" 15 "Fehler";
VAL_ 324 GE_Test_Freigabe 0 "kein Test" 1 "gültige Testparameter";
VAL_ 324 GE_N_Haltephase 0 "nicht_aktiv" 1 "aktiv";
VAL_ 324 GE_WH_Abschalten 0 "Wählhebel-SG ein" 1 "Wählhebel-SH aus";
VAL_ 324 GE_Soll_Haltemagnet 0 "Init_nicht_verwendet" 1 "nicht_halten" 2 "halten" 3 "keine_Vorgabe";
VAL_ 324 GE_WH_Shiftlock 0 "Waehlhebel_sperren" 1 "Waehlhebel_freigeben";
VAL_ 324 GE_WH_Mute 0 "Senden_ein" 1 "Senden_aus";
VAL_ 324 GE_Ausleuchtung_blinkend 0 "kein_Blinken" 1 "Blinken";
